VERSION "HINBNNNYYNNNYYNNNNNNNNNNNNYNNNYYYNNYNNNNNN/4//%%/4/'%**4NNN///"

NS_ :

BS_:

BU_: VirtualNMTMaster TTGateway_ID2 Master_ID1 SupportFront_ID12 LadderDrive_ID11 SupportRear_ID13 ControlPanel_ID10

BO_ 1794 HBGuard_002: 1 TTGateway_ID2
 SG_ Toggle : 7|1@1+ (1,0) [0|0] "" Vector__XXX
 SG_ State : 0|7@1+ (1,0) [0|0] "" Vector__XXX

BO_ 1410 SSDO_002: 8 TTGateway_ID2
 SG_ requested_engine_speed_minimum_v m3 : 32|16@1+ (1,0) [0|65535] "" Vector__XXX
 SG_ requested_engine_speed_maximum_v m2 : 32|16@1+ (1,0) [0|65535] "" Vector__XXX
 SG_ requested_engine_speed_value_614 m1 : 32|16@1- (1,0) [-32768|32767] "" Vector__XXX
 SG_ requested_engine_speed_number_of m0 : 32|8@1+ (1,0) [0|255] "" Vector__XXX
 SG_ SubIndex_614A m24906M : 24|8@1+ (1,0) [0|3] "" Vector__XXX
 SG_ requested_engine_speed_lower_lim m3 : 32|16@1+ (1,0) [0|65535] "" Vector__XXX
 SG_ requested_engine_speed_lowe_0000 m2 : 32|16@1+ (1,0) [0|65535] "" Vector__XXX
 SG_ requested_engine_speed_lowe_0001 m1 : 32|16@1+ (1,0) [0|65535] "" Vector__XXX
 SG_ requested_engine_speed_lowe_0002 m0 : 32|8@1+ (1,0) [0|255] "" Vector__XXX
 SG_ SubIndex_6142 m24898M : 24|8@1+ (1,0) [0|3] "" Vector__XXX
 SG_ requested_engine_speed_upper_lim m3 : 32|16@1+ (1,0) [0|65535] "" Vector__XXX
 SG_ requested_engine_speed_uppe_0000 m2 : 32|16@1+ (1,0) [0|65535] "" Vector__XXX
 SG_ requested_engine_speed_uppe_0001 m1 : 32|16@1+ (1,0) [0|65535] "" Vector__XXX
 SG_ requested_engine_speed_uppe_0002 m0 : 32|8@1+ (1,0) [0|255] "" Vector__XXX
 SG_ SubIndex_6140 m24896M : 24|8@1+ (1,0) [0|3] "" Vector__XXX
 SG_ engine_stop_switch_Bit_1_613F_01 m1 : 32|8@1+ (1,0) [0|255] "" Vector__XXX
 SG_ engine_stop_switch_Number_of_ent m0 : 32|8@1+ (1,0) [0|255] "" Vector__XXX
 SG_ SubIndex_613F m24895M : 24|8@1+ (1,0) [0|1] "" Vector__XXX
 SG_ engine_start_switch_Bit_1_613E_0 m1 : 32|8@1+ (1,0) [0|255] "" Vector__XXX
 SG_ engine_start_switch_Number_of_en m0 : 32|8@1+ (1,0) [0|255] "" Vector__XXX
 SG_ SubIndex_613E m24894M : 24|8@1+ (1,0) [0|1] "" Vector__XXX
 SG_ first_clutch_dependent_PTO_switc m1 : 32|8@1+ (1,0) [0|255] "" Vector__XXX
 SG_ first_clutch_dependent_PTO__0000 m0 : 32|8@1+ (1,0) [0|255] "" Vector__XXX
 SG_ SubIndex_6136 m24886M : 24|8@1+ (1,0) [0|1] "" Vector__XXX
 SG_ first_engine_mounted_PTO_feedbac m1 : 32|8@1+ (1,0) [0|255] "" Vector__XXX
 SG_ first_engine_mounted_PTO_fe_0000 m0 : 32|8@1+ (1,0) [0|255] "" Vector__XXX
 SG_ SubIndex_6131 m24881M : 24|8@1+ (1,0) [0|1] "" Vector__XXX
 SG_ PTOSwitch_6113_05 m5 : 32|8@1+ (1,0) [0|255] "" Vector__XXX
 SG_ SupportPositionGateIn_6113_04 m4 : 32|8@1+ (1,0) [0|255] "" Vector__XXX
 SG_ engine_speed_minimum_value_range m3 : 32|16@1+ (1,0) [0|65535] "" Vector__XXX
 SG_ engine_speed_maximum_value_range m2 : 32|16@1+ (1,0) [0|65535] "" Vector__XXX
 SG_ EngineSpeed_6113_01 m1 : 32|16@1+ (1,0) [0|65535] "" Vector__XXX
 SG_ NrOfObjects_6113_00 m0 : 32|8@1+ (1,0) [5|5] "" Vector__XXX
 SG_ SubIndex_6113 m24851M : 24|8@1+ (1,0) [0|5] "" Vector__XXX
 SG_ current_gear_minimum_value_range m3 : 32|8@1- (1,0) [-128|127] "" Vector__XXX
 SG_ current_gear_maximum_value_range m2 : 32|8@1- (1,0) [-128|127] "" Vector__XXX
 SG_ CurrentGearValue_610C_01 m1 : 32|8@1- (1,0) [-128|127] "" Vector__XXX
 SG_ NrOfObjects_610C_00 m0 : 32|8@1+ (1,0) [0|255] "" Vector__XXX
 SG_ SubIndex_610C m24844M : 24|8@1+ (1,0) [0|3] "" Vector__XXX
 SG_ wheel_based_vehicle_speed_minimu m3 : 32|16@1+ (1,0) [0|65535] "" Vector__XXX
 SG_ wheel_based_vehicle_speed_maximu m2 : 32|16@1+ (1,0) [0|65535] "" Vector__XXX
 SG_ wheel_based_vehicle_speed_value_ m1 : 32|16@1+ (1,0) [0|65535] "" Vector__XXX
 SG_ wheel_based_vehicle_speed_number m0 : 32|8@1+ (1,0) [0|255] "" Vector__XXX
 SG_ SubIndex_6006 m24582M : 24|8@1+ (1,0) [0|3] "" Vector__XXX
 SG_ park_brake_demand_value_minimum_ m3 : 32|8@1+ (1,0) [0|255] "" Vector__XXX
 SG_ park_brake_demand_value_maximum_ m2 : 32|8@1+ (1,0) [0|255] "" Vector__XXX
 SG_ ParkBrakeDemandValue_6000_01 m1 : 32|8@1+ (1,0) [0|255] "" Vector__XXX
 SG_ NrOfObjects_6000_00 m0 : 32|8@1+ (1,0) [0|255] "" Vector__XXX
 SG_ SubIndex_6000 m24576M : 24|8@1+ (1,0) [0|3] "" Vector__XXX
 SG_ NrOfMappedObjects_1A02_00 m0 : 32|8@1+ (1,0) [0|64] "" Vector__XXX
 SG_ SubIndex_1A02 m6658M : 24|8@1+ (1,0) [0|0] "" Vector__XXX
 SG_ NrOfMappedObjects_1A01_00 m0 : 32|8@1+ (1,0) [0|64] "" Vector__XXX
 SG_ SubIndex_1A01 m6657M : 24|8@1+ (1,0) [0|0] "" Vector__XXX
 SG_ mappedObj5_1A00_05 m5 : 32|32@1+ (1,0) [0|4294967295] "" Vector__XXX
 SG_ mappedObj4_1A00_04 m4 : 32|32@1+ (1,0) [0|4294967295] "" Vector__XXX
 SG_ mappedObj3_1A00_03 m3 : 32|32@1+ (1,0) [0|4294967295] "" Vector__XXX
 SG_ mappedObj2_1A00_02 m2 : 32|32@1+ (1,0) [0|4294967295] "" Vector__XXX
 SG_ mappedObj1_1A00_01 m1 : 32|32@1+ (1,0) [0|4294967295] "" Vector__XXX
 SG_ NrOfMappedObjects_1A00_00 m0 : 32|8@1+ (1,0) [0|64] "" Vector__XXX
 SG_ SubIndex_1A00 m6656M : 24|8@1+ (1,0) [0|5] "" Vector__XXX
 SG_ EventTimer_1802_05 m5 : 32|16@1+ (1,0) [0|65535] "" Vector__XXX
 SG_ TransmissionType_1802_02 m2 : 32|8@1+ (1,0) [0|255] "" Vector__XXX
 SG_ COB_ID_1802_01 m1 : 32|32@1+ (1,0) [1|4294967295] "" Vector__XXX
 SG_ Highest_sub_index_supported_1802 m0 : 32|8@1+ (1,0) [2|5] "" Vector__XXX
 SG_ SubIndex_1802 m6146M : 24|8@1+ (1,0) [0|5] "" Vector__XXX
 SG_ EventTimer_1801_05 m5 : 32|16@1+ (1,0) [0|65535] "" Vector__XXX
 SG_ TransmissionType_1801_02 m2 : 32|8@1+ (1,0) [0|255] "" Vector__XXX
 SG_ COB_ID_1801_01 m1 : 32|32@1+ (1,0) [1|4294967295] "" Vector__XXX
 SG_ Highest_sub_index_supported_1801 m0 : 32|8@1+ (1,0) [2|5] "" Vector__XXX
 SG_ SubIndex_1801 m6145M : 24|8@1+ (1,0) [0|5] "" Vector__XXX
 SG_ EventTimer_1800_05 m5 : 32|16@1+ (1,0) [0|65535] "" Vector__XXX
 SG_ TransmissionType_1800_02 m2 : 32|8@1+ (1,0) [0|255] "" Vector__XXX
 SG_ COB_ID_1800_01 m1 : 32|32@1+ (1,0) [1|4294967295] "" Vector__XXX
 SG_ Highest_sub_index_supported_1800 m0 : 32|8@1+ (1,0) [2|5] "" Vector__XXX
 SG_ SubIndex_1800 m6144M : 24|8@1+ (1,0) [0|5] "" Vector__XXX
 SG_ GENERATED_1602_03 m3 : 32|32@1+ (1,0) [0|4294967295] "" Vector__XXX
 SG_ GENERATED_1602_02 m2 : 32|32@1+ (1,0) [0|4294967295] "" Vector__XXX
 SG_ GENERATED_1602_01 m1 : 32|32@1+ (1,0) [0|4294967295] "" Vector__XXX
 SG_ NrOfMappedObjects_1602_00 m0 : 32|8@1+ (1,0) [0|64] "" Vector__XXX
 SG_ SubIndex_1602 m5634M : 24|8@1+ (1,0) [0|3] "" Vector__XXX
 SG_ PTO_Switch_1601_01 m1 : 32|8@1+ (1,0) [0|255] "" Vector__XXX
 SG_ NrOfMappedObjects_1601_00 m0 : 32|8@1+ (1,0) [0|64] "" Vector__XXX
 SG_ SubIndex_1601 m5633M : 24|8@1+ (1,0) [0|1] "" Vector__XXX
 SG_ mappedObj5_1600_05 m5 : 32|32@1+ (1,0) [0|4294967295] "" Vector__XXX
 SG_ mappedObj4_1600_04 m4 : 32|32@1+ (1,0) [0|4294967295] "" Vector__XXX
 SG_ mappedObj3_1600_03 m3 : 32|32@1+ (1,0) [0|4294967295] "" Vector__XXX
 SG_ mappedObj2_1600_02 m2 : 32|32@1+ (1,0) [0|4294967295] "" Vector__XXX
 SG_ mappedObj1_1600_01 m1 : 32|32@1+ (1,0) [0|4294967295] "" Vector__XXX
 SG_ NrOfMappedObjects_1600_00 m0 : 32|8@1+ (1,0) [0|64] "" Vector__XXX
 SG_ SubIndex_1600 m5632M : 24|8@1+ (1,0) [0|5] "" Vector__XXX
 SG_ TransmissionType_1402_02 m2 : 32|8@1+ (1,0) [0|255] "" Vector__XXX
 SG_ COB_ID_1402_01 m1 : 32|32@1+ (1,0) [1|4294967295] "" Vector__XXX
 SG_ Highest_sub_index_supported_1402 m0 : 32|8@1+ (1,0) [2|5] "" Vector__XXX
 SG_ SubIndex_1402 m5122M : 24|8@1+ (1,0) [0|2] "" Vector__XXX
 SG_ TransmissionType_1401_02 m2 : 32|8@1+ (1,0) [0|255] "" Vector__XXX
 SG_ COB_ID_1401_01 m1 : 32|32@1+ (1,0) [1|4294967295] "" Vector__XXX
 SG_ Highest_sub_index_supported_1401 m0 : 32|8@1+ (1,0) [2|5] "" Vector__XXX
 SG_ SubIndex_1401 m5121M : 24|8@1+ (1,0) [0|2] "" Vector__XXX
 SG_ TransmissionType_1400_02 m2 : 32|8@1+ (1,0) [0|255] "" Vector__XXX
 SG_ COB_ID_1400_01 m1 : 32|32@1+ (1,0) [1|4294967295] "" Vector__XXX
 SG_ Highest_sub_index_supported_1400 m0 : 32|8@1+ (1,0) [2|5] "" Vector__XXX
 SG_ SubIndex_1400 m5120M : 24|8@1+ (1,0) [0|2] "" Vector__XXX
 SG_ Vendor_Id_1018_01 m1 : 32|32@1+ (1,0) [0|4294967295] "" Vector__XXX
 SG_ NrOfElements_1018_00 m0 : 32|8@1+ (1,0) [1|4] "" Vector__XXX
 SG_ SubIndex_1018 m4120M : 24|8@1+ (1,0) [0|1] "" Vector__XXX
 SG_ Sync_Window_Length_1007 m0 : 32|32@1+ (1,0) [0|4294967295] "" Vector__XXX
 SG_ SubIndex_1007 m4103M : 24|8@1+ (1,0) [0|0] "" Vector__XXX
 SG_ Communication_Cycle_Period_1006 m0 : 32|32@1+ (1,0) [0|4294967295] "" Vector__XXX
 SG_ SubIndex_1006 m4102M : 24|8@1+ (1,0) [0|0] "" Vector__XXX
 SG_ COB_ID_SYNC_1005 m0 : 32|32@1+ (1,0) [1|4294967295] "" Vector__XXX
 SG_ SubIndex_1005 m4101M : 24|8@1+ (1,0) [0|0] "" Vector__XXX
 SG_ ErrorRegister_1001 m0 : 32|8@1+ (1,0) [0|255] "" Vector__XXX
 SG_ SubIndex_1001 m4097M : 24|8@1+ (1,0) [0|0] "" Vector__XXX
 SG_ Device_Type_1000 m0 : 32|32@1+ (1,0) [0|4294967295] "" Vector__XXX
 SG_ SubIndex_1000 m4096M : 24|8@1+ (1,0) [0|0] "" Vector__XXX
 SG_ Index m1M : 8|16@1+ (1,0) [4096|24906] "" Vector__XXX
 SG_ TransferType m1M : 1|1@1+ (1,0) [0|1] "" Vector__XXX
 SG_ NotUsedBytes m1 : 2|2@1+ (1,0) [0|3] "" Vector__XXX
 SG_ SizeIndicator m1 : 0|1@1+ (1,0) [0|1] "" Vector__XXX
 SG_ SCS M : 5|3@1+ (1,0) [0|6] "" Vector__XXX

BO_ 1538 CSDO_002: 8 Vector__XXX
 SG_ requested_engine_speed_mini_0000 m3 : 32|16@1+ (1,0) [0|65535] ""  TTGateway_ID2
 SG_ requested_engine_speed_maxi_0000 m2 : 32|16@1+ (1,0) [0|65535] ""  TTGateway_ID2
 SG_ requested_engine_speed_valu_0000 m1 : 32|16@1- (1,0) [-32768|32767] ""  TTGateway_ID2
 SG_ requested_engine_speed_numb_0000 m0 : 32|8@1+ (1,0) [0|255] ""  TTGateway_ID2
 SG_ SubIndex_614A m24906M : 24|8@1+ (1,0) [0|3] ""  TTGateway_ID2
 SG_ requested_engine_speed_lowe_0003 m3 : 32|16@1+ (1,0) [0|65535] ""  TTGateway_ID2
 SG_ requested_engine_speed_lowe_0004 m2 : 32|16@1+ (1,0) [0|65535] ""  TTGateway_ID2
 SG_ requested_engine_speed_lowe_0005 m1 : 32|16@1+ (1,0) [0|65535] ""  TTGateway_ID2
 SG_ requested_engine_speed_lowe_0006 m0 : 32|8@1+ (1,0) [0|255] ""  TTGateway_ID2
 SG_ SubIndex_6142 m24898M : 24|8@1+ (1,0) [0|3] ""  TTGateway_ID2
 SG_ requested_engine_speed_uppe_0003 m3 : 32|16@1+ (1,0) [0|65535] ""  TTGateway_ID2
 SG_ requested_engine_speed_uppe_0004 m2 : 32|16@1+ (1,0) [0|65535] ""  TTGateway_ID2
 SG_ requested_engine_speed_uppe_0005 m1 : 32|16@1+ (1,0) [0|65535] ""  TTGateway_ID2
 SG_ requested_engine_speed_uppe_0006 m0 : 32|8@1+ (1,0) [0|255] ""  TTGateway_ID2
 SG_ SubIndex_6140 m24896M : 24|8@1+ (1,0) [0|3] ""  TTGateway_ID2
 SG_ engine_stop_switch_Bit_1_613F_01 m1 : 32|8@1+ (1,0) [0|255] ""  TTGateway_ID2
 SG_ engine_stop_switch_Number_o_0000 m0 : 32|8@1+ (1,0) [0|255] ""  TTGateway_ID2
 SG_ SubIndex_613F m24895M : 24|8@1+ (1,0) [0|1] ""  TTGateway_ID2
 SG_ engine_start_switch_Bit_1_6_0000 m1 : 32|8@1+ (1,0) [0|255] ""  TTGateway_ID2
 SG_ engine_start_switch_Number__0000 m0 : 32|8@1+ (1,0) [0|255] ""  TTGateway_ID2
 SG_ SubIndex_613E m24894M : 24|8@1+ (1,0) [0|1] ""  TTGateway_ID2
 SG_ first_clutch_dependent_PTO__0001 m1 : 32|8@1+ (1,0) [0|255] ""  TTGateway_ID2
 SG_ first_clutch_dependent_PTO__0002 m0 : 32|8@1+ (1,0) [0|255] ""  TTGateway_ID2
 SG_ SubIndex_6136 m24886M : 24|8@1+ (1,0) [0|1] ""  TTGateway_ID2
 SG_ first_engine_mounted_PTO_fe_0001 m1 : 32|8@1+ (1,0) [0|255] ""  TTGateway_ID2
 SG_ first_engine_mounted_PTO_fe_0002 m0 : 32|8@1+ (1,0) [0|255] ""  TTGateway_ID2
 SG_ SubIndex_6131 m24881M : 24|8@1+ (1,0) [0|1] ""  TTGateway_ID2
 SG_ PTOSwitch_6113_05 m5 : 32|8@1+ (1,0) [0|255] ""  TTGateway_ID2
 SG_ SupportPositionGateIn_6113_04 m4 : 32|8@1+ (1,0) [0|255] ""  TTGateway_ID2
 SG_ engine_speed_minimum_value__0000 m3 : 32|16@1+ (1,0) [0|65535] ""  TTGateway_ID2
 SG_ engine_speed_maximum_value__0000 m2 : 32|16@1+ (1,0) [0|65535] ""  TTGateway_ID2
 SG_ EngineSpeed_6113_01 m1 : 32|16@1+ (1,0) [0|65535] ""  TTGateway_ID2
 SG_ NrOfObjects_6113_00 m0 : 32|8@1+ (1,0) [5|5] ""  TTGateway_ID2
 SG_ SubIndex_6113 m24851M : 24|8@1+ (1,0) [0|5] ""  TTGateway_ID2
 SG_ current_gear_minimum_value__0000 m3 : 32|8@1- (1,0) [-128|127] ""  TTGateway_ID2
 SG_ current_gear_maximum_value__0000 m2 : 32|8@1- (1,0) [-128|127] ""  TTGateway_ID2
 SG_ CurrentGearValue_610C_01 m1 : 32|8@1- (1,0) [-128|127] ""  TTGateway_ID2
 SG_ NrOfObjects_610C_00 m0 : 32|8@1+ (1,0) [0|255] ""  TTGateway_ID2
 SG_ SubIndex_610C m24844M : 24|8@1+ (1,0) [0|3] ""  TTGateway_ID2
 SG_ wheel_based_vehicle_speed_m_0000 m3 : 32|16@1+ (1,0) [0|65535] ""  TTGateway_ID2
 SG_ wheel_based_vehicle_speed_m_0001 m2 : 32|16@1+ (1,0) [0|65535] ""  TTGateway_ID2
 SG_ wheel_based_vehicle_speed_v_0000 m1 : 32|16@1+ (1,0) [0|65535] ""  TTGateway_ID2
 SG_ wheel_based_vehicle_speed_n_0000 m0 : 32|8@1+ (1,0) [0|255] ""  TTGateway_ID2
 SG_ SubIndex_6006 m24582M : 24|8@1+ (1,0) [0|3] ""  TTGateway_ID2
 SG_ park_brake_demand_value_min_0000 m3 : 32|8@1+ (1,0) [0|255] ""  TTGateway_ID2
 SG_ park_brake_demand_value_max_0000 m2 : 32|8@1+ (1,0) [0|255] ""  TTGateway_ID2
 SG_ ParkBrakeDemandValue_6000_01 m1 : 32|8@1+ (1,0) [0|255] ""  TTGateway_ID2
 SG_ NrOfObjects_6000_00 m0 : 32|8@1+ (1,0) [0|255] ""  TTGateway_ID2
 SG_ SubIndex_6000 m24576M : 24|8@1+ (1,0) [0|3] ""  TTGateway_ID2
 SG_ NrOfMappedObjects_1A02_00 m0 : 32|8@1+ (1,0) [0|64] ""  TTGateway_ID2
 SG_ SubIndex_1A02 m6658M : 24|8@1+ (1,0) [0|0] ""  TTGateway_ID2
 SG_ NrOfMappedObjects_1A01_00 m0 : 32|8@1+ (1,0) [0|64] ""  TTGateway_ID2
 SG_ SubIndex_1A01 m6657M : 24|8@1+ (1,0) [0|0] ""  TTGateway_ID2
 SG_ mappedObj5_1A00_05 m5 : 32|32@1+ (1,0) [0|4294967295] ""  TTGateway_ID2
 SG_ mappedObj4_1A00_04 m4 : 32|32@1+ (1,0) [0|4294967295] ""  TTGateway_ID2
 SG_ mappedObj3_1A00_03 m3 : 32|32@1+ (1,0) [0|4294967295] ""  TTGateway_ID2
 SG_ mappedObj2_1A00_02 m2 : 32|32@1+ (1,0) [0|4294967295] ""  TTGateway_ID2
 SG_ mappedObj1_1A00_01 m1 : 32|32@1+ (1,0) [0|4294967295] ""  TTGateway_ID2
 SG_ NrOfMappedObjects_1A00_00 m0 : 32|8@1+ (1,0) [0|64] ""  TTGateway_ID2
 SG_ SubIndex_1A00 m6656M : 24|8@1+ (1,0) [0|5] ""  TTGateway_ID2
 SG_ EventTimer_1802_05 m5 : 32|16@1+ (1,0) [0|65535] ""  TTGateway_ID2
 SG_ TransmissionType_1802_02 m2 : 32|8@1+ (1,0) [0|255] ""  TTGateway_ID2
 SG_ COB_ID_1802_01 m1 : 32|32@1+ (1,0) [1|4294967295] ""  TTGateway_ID2
 SG_ Highest_sub_index_supported_0000 m0 : 32|8@1+ (1,0) [2|5] ""  TTGateway_ID2
 SG_ SubIndex_1802 m6146M : 24|8@1+ (1,0) [0|5] ""  TTGateway_ID2
 SG_ EventTimer_1801_05 m5 : 32|16@1+ (1,0) [0|65535] ""  TTGateway_ID2
 SG_ TransmissionType_1801_02 m2 : 32|8@1+ (1,0) [0|255] ""  TTGateway_ID2
 SG_ COB_ID_1801_01 m1 : 32|32@1+ (1,0) [1|4294967295] ""  TTGateway_ID2
 SG_ Highest_sub_index_supported_0001 m0 : 32|8@1+ (1,0) [2|5] ""  TTGateway_ID2
 SG_ SubIndex_1801 m6145M : 24|8@1+ (1,0) [0|5] ""  TTGateway_ID2
 SG_ EventTimer_1800_05 m5 : 32|16@1+ (1,0) [0|65535] ""  TTGateway_ID2
 SG_ TransmissionType_1800_02 m2 : 32|8@1+ (1,0) [0|255] ""  TTGateway_ID2
 SG_ COB_ID_1800_01 m1 : 32|32@1+ (1,0) [1|4294967295] ""  TTGateway_ID2
 SG_ Highest_sub_index_supported_0002 m0 : 32|8@1+ (1,0) [2|5] ""  TTGateway_ID2
 SG_ SubIndex_1800 m6144M : 24|8@1+ (1,0) [0|5] ""  TTGateway_ID2
 SG_ GENERATED_1602_03 m3 : 32|32@1+ (1,0) [0|4294967295] ""  TTGateway_ID2
 SG_ GENERATED_1602_02 m2 : 32|32@1+ (1,0) [0|4294967295] ""  TTGateway_ID2
 SG_ GENERATED_1602_01 m1 : 32|32@1+ (1,0) [0|4294967295] ""  TTGateway_ID2
 SG_ NrOfMappedObjects_1602_00 m0 : 32|8@1+ (1,0) [0|64] ""  TTGateway_ID2
 SG_ SubIndex_1602 m5634M : 24|8@1+ (1,0) [0|3] ""  TTGateway_ID2
 SG_ PTO_Switch_1601_01 m1 : 32|8@1+ (1,0) [0|255] ""  TTGateway_ID2
 SG_ NrOfMappedObjects_1601_00 m0 : 32|8@1+ (1,0) [0|64] ""  TTGateway_ID2
 SG_ SubIndex_1601 m5633M : 24|8@1+ (1,0) [0|1] ""  TTGateway_ID2
 SG_ mappedObj5_1600_05 m5 : 32|32@1+ (1,0) [0|4294967295] ""  TTGateway_ID2
 SG_ mappedObj4_1600_04 m4 : 32|32@1+ (1,0) [0|4294967295] ""  TTGateway_ID2
 SG_ mappedObj3_1600_03 m3 : 32|32@1+ (1,0) [0|4294967295] ""  TTGateway_ID2
 SG_ mappedObj2_1600_02 m2 : 32|32@1+ (1,0) [0|4294967295] ""  TTGateway_ID2
 SG_ mappedObj1_1600_01 m1 : 32|32@1+ (1,0) [0|4294967295] ""  TTGateway_ID2
 SG_ NrOfMappedObjects_1600_00 m0 : 32|8@1+ (1,0) [0|64] ""  TTGateway_ID2
 SG_ SubIndex_1600 m5632M : 24|8@1+ (1,0) [0|5] ""  TTGateway_ID2
 SG_ TransmissionType_1402_02 m2 : 32|8@1+ (1,0) [0|255] ""  TTGateway_ID2
 SG_ COB_ID_1402_01 m1 : 32|32@1+ (1,0) [1|4294967295] ""  TTGateway_ID2
 SG_ Highest_sub_index_supported_0003 m0 : 32|8@1+ (1,0) [2|5] ""  TTGateway_ID2
 SG_ SubIndex_1402 m5122M : 24|8@1+ (1,0) [0|2] ""  TTGateway_ID2
 SG_ TransmissionType_1401_02 m2 : 32|8@1+ (1,0) [0|255] ""  TTGateway_ID2
 SG_ COB_ID_1401_01 m1 : 32|32@1+ (1,0) [1|4294967295] ""  TTGateway_ID2
 SG_ Highest_sub_index_supported_0004 m0 : 32|8@1+ (1,0) [2|5] ""  TTGateway_ID2
 SG_ SubIndex_1401 m5121M : 24|8@1+ (1,0) [0|2] ""  TTGateway_ID2
 SG_ TransmissionType_1400_02 m2 : 32|8@1+ (1,0) [0|255] ""  TTGateway_ID2
 SG_ COB_ID_1400_01 m1 : 32|32@1+ (1,0) [1|4294967295] ""  TTGateway_ID2
 SG_ Highest_sub_index_supported_0005 m0 : 32|8@1+ (1,0) [2|5] ""  TTGateway_ID2
 SG_ SubIndex_1400 m5120M : 24|8@1+ (1,0) [0|2] ""  TTGateway_ID2
 SG_ Vendor_Id_1018_01 m1 : 32|32@1+ (1,0) [0|4294967295] ""  TTGateway_ID2
 SG_ NrOfElements_1018_00 m0 : 32|8@1+ (1,0) [1|4] ""  TTGateway_ID2
 SG_ SubIndex_1018 m4120M : 24|8@1+ (1,0) [0|1] ""  TTGateway_ID2
 SG_ Sync_Window_Length_1007 m0 : 32|32@1+ (1,0) [0|4294967295] ""  TTGateway_ID2
 SG_ SubIndex_1007 m4103M : 24|8@1+ (1,0) [0|0] ""  TTGateway_ID2
 SG_ Communication_Cycle_Period_1006 m0 : 32|32@1+ (1,0) [0|4294967295] ""  TTGateway_ID2
 SG_ SubIndex_1006 m4102M : 24|8@1+ (1,0) [0|0] ""  TTGateway_ID2
 SG_ COB_ID_SYNC_1005 m0 : 32|32@1+ (1,0) [1|4294967295] ""  TTGateway_ID2
 SG_ SubIndex_1005 m4101M : 24|8@1+ (1,0) [0|0] ""  TTGateway_ID2
 SG_ ErrorRegister_1001 m0 : 32|8@1+ (1,0) [0|255] ""  TTGateway_ID2
 SG_ SubIndex_1001 m4097M : 24|8@1+ (1,0) [0|0] ""  TTGateway_ID2
 SG_ Device_Type_1000 m0 : 32|32@1+ (1,0) [0|4294967295] ""  TTGateway_ID2
 SG_ SubIndex_1000 m4096M : 24|8@1+ (1,0) [0|0] ""  TTGateway_ID2
 SG_ Index m1M : 8|16@1+ (1,0) [4096|24906] ""  TTGateway_ID2
 SG_ TransferType m1M : 1|1@1+ (1,0) [0|1] ""  TTGateway_ID2
 SG_ NotUsedBytes m1 : 2|2@1+ (1,0) [0|3] ""  TTGateway_ID2
 SG_ SizeIndicator m1 : 0|1@1+ (1,0) [0|1] ""  TTGateway_ID2
 SG_ CCS M : 5|3@1+ (1,0) [0|6] ""  TTGateway_ID2

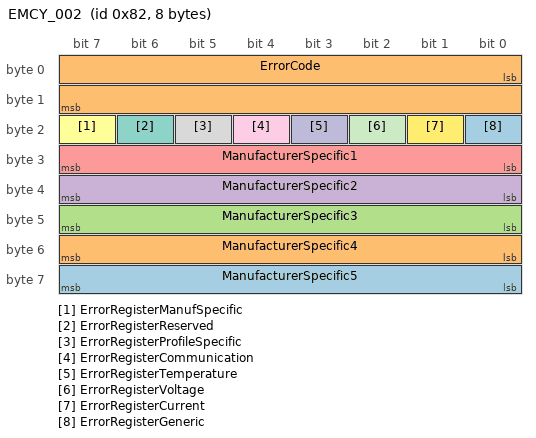
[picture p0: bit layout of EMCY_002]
BO_ 130 EMCY_002: 8 TTGateway_ID2
 SG_ ManufacturerSpecific5 : 56|8@1+ (1,0) [0|0] "" Vector__XXX
 SG_ ManufacturerSpecific4 : 48|8@1+ (1,0) [0|0] "" Vector__XXX
 SG_ ManufacturerSpecific3 : 40|8@1+ (1,0) [0|0] "" Vector__XXX
 SG_ ManufacturerSpecific2 : 32|8@1+ (1,0) [0|0] "" Vector__XXX
 SG_ ManufacturerSpecific1 : 24|8@1+ (1,0) [0|0] "" Vector__XXX
 SG_ ErrorRegisterManufSpecific : 23|1@1+ (1,0) [0|0] "" Vector__XXX
 SG_ ErrorRegisterReserved : 22|1@1+ (1,0) [0|0] "" Vector__XXX
 SG_ ErrorRegisterProfileSpecific : 21|1@1+ (1,0) [0|0] "" Vector__XXX
 SG_ ErrorRegisterCommunication : 20|1@1+ (1,0) [0|0] "" Vector__XXX
 SG_ ErrorRegisterTemperature : 19|1@1+ (1,0) [0|0] "" Vector__XXX
 SG_ ErrorRegisterVoltage : 18|1@1+ (1,0) [0|0] "" Vector__XXX
 SG_ ErrorRegisterCurrent : 17|1@1+ (1,0) [0|0] "" Vector__XXX
 SG_ ErrorRegisterGeneric : 16|1@1+ (1,0) [0|0] "" Vector__XXX
 SG_ ErrorCode : 0|16@1+ (1,0) [0|0] "" Vector__XXX

BO_ 128 SYNC_001: 0 Vector__XXX

BO_ 1793 HBGuard_001: 1 Master_ID1
 SG_ Toggle : 7|1@1+ (1,0) [0|0] "" Vector__XXX
 SG_ State : 0|7@1+ (1,0) [0|0] "" Vector__XXX

BO_ 1409 SSDO_001: 8 Master_ID1
 SG_ NetVarUInt32Out10_A680_0A m10 : 32|32@1+ (1,0) [0|4294967295] "" Vector__XXX
 SG_ NetVarUInt32Out9_A680_09 m9 : 32|32@1+ (1,0) [0|4294967295] "" Vector__XXX
 SG_ NetVarUInt32Out8_A680_08 m8 : 32|32@1+ (1,0) [0|4294967295] "" Vector__XXX
 SG_ NetVarUInt32Out7_A680_07 m7 : 32|32@1+ (1,0) [0|4294967295] "" Vector__XXX
 SG_ NetVarUInt32Out6_A680_06 m6 : 32|32@1+ (1,0) [0|4294967295] "" Vector__XXX
 SG_ NetVarUInt32Out5_A680_05 m5 : 32|32@1+ (1,0) [0|4294967295] "" Vector__XXX
 SG_ NetVarUInt32Out4_A680_04 m4 : 32|32@1+ (1,0) [0|4294967295] "" Vector__XXX
 SG_ NetVarUInt32Out3_A680_03 m3 : 32|32@1+ (1,0) [0|4294967295] "" Vector__XXX
 SG_ NetVarUInt32Out2_A680_02 m2 : 32|32@1+ (1,0) [0|4294967295] "" Vector__XXX
 SG_ NetVarUInt32Out1_A680_01 m1 : 32|32@1+ (1,0) [0|4294967295] "" Vector__XXX
 SG_ NrOfObjects_A680_00 m0 : 32|8@1+ (1,0) [0|255] "" Vector__XXX
 SG_ SubIndex_A680 m42624M : 24|8@1+ (1,0) [0|10] "" Vector__XXX
 SG_ NetVarInt32Out10_A640_0A m10 : 32|32@1- (1,0) [-2147483648|2147483647] "" Vector__XXX
 SG_ NetVarInt32Out9_A640_09 m9 : 32|32@1- (1,0) [-2147483648|2147483647] "" Vector__XXX
 SG_ NetVarInt32Out8_A640_08 m8 : 32|32@1- (1,0) [-2147483648|2147483647] "" Vector__XXX
 SG_ NetVarInt32Out7_A640_07 m7 : 32|32@1- (1,0) [-2147483648|2147483647] "" Vector__XXX
 SG_ NetVarInt32Out6_A640_06 m6 : 32|32@1- (1,0) [-2147483648|2147483647] "" Vector__XXX
 SG_ NetVarInt32Out5_A640_05 m5 : 32|32@1- (1,0) [-2147483648|2147483647] "" Vector__XXX
 SG_ NetVarInt32Out4_A640_04 m4 : 32|32@1- (1,0) [-2147483648|2147483647] "" Vector__XXX
 SG_ pos_act_val_sup_rear_A640_03 m3 : 32|32@1- (1,0) [-2147483648|2147483647] "" Vector__XXX
 SG_ pos_act_val_sup_front_A640_02 m2 : 32|32@1- (1,0) [-2147483648|2147483647] "" Vector__XXX
 SG_ pos_act_val_ladder_A640_01 m1 : 32|32@1- (1,0) [-2147483648|2147483647] "" Vector__XXX
 SG_ NrOfObjects_A640_00 m0 : 32|8@1+ (1,0) [0|255] "" Vector__XXX
 SG_ SubIndex_A640 m42560M : 24|8@1+ (1,0) [0|10] "" Vector__XXX
 SG_ NetVarUInt16Out10_A580_0A m10 : 32|16@1+ (1,0) [0|65535] "" Vector__XXX
 SG_ NetVarUInt16Out9_A580_09 m9 : 32|16@1+ (1,0) [0|65535] "" Vector__XXX
 SG_ NetVarUInt16Out8_A580_08 m8 : 32|16@1+ (1,0) [0|65535] "" Vector__XXX
 SG_ EngineSpeed_A580_07 m7 : 32|16@1+ (1,0) [0|65535] "" Vector__XXX
 SG_ wheel_based_vehicle_speed_A580_0 m6 : 32|16@1+ (1,0) [0|65535] "" Vector__XXX
 SG_ NetVarUInt16Out5_A580_05 m5 : 32|16@1+ (1,0) [0|65535] "" Vector__XXX
 SG_ NetVarUInt16Out4_A580_04 m4 : 32|16@1+ (1,0) [0|65535] "" Vector__XXX
 SG_ statusword_support_rear_A580_03 m3 : 32|16@1+ (1,0) [0|65535] "" Vector__XXX
 SG_ statusword_support_front_A580_02 m2 : 32|16@1+ (1,0) [0|65535] "" Vector__XXX
 SG_ statusword_ladder_A580_01 m1 : 32|16@1+ (1,0) [0|65535] "" Vector__XXX
 SG_ NrOfObjects_A580_00 m0 : 32|8@1+ (1,0) [0|255] "" Vector__XXX
 SG_ SubIndex_A580 m42368M : 24|8@1+ (1,0) [0|10] "" Vector__XXX
 SG_ NetVarInt16Out10_A540_0A m10 : 32|16@1- (1,0) [-32768|32767] "" Vector__XXX
 SG_ NetVarInt16Out9_A540_09 m9 : 32|16@1- (1,0) [-32768|32767] "" Vector__XXX
 SG_ NetVarInt16Out8_A540_08 m8 : 32|16@1- (1,0) [-32768|32767] "" Vector__XXX
 SG_ NetVarInt16Out7_A540_07 m7 : 32|16@1- (1,0) [-32768|32767] "" Vector__XXX
 SG_ NetVarInt16Out6_A540_06 m6 : 32|16@1- (1,0) [-32768|32767] "" Vector__XXX
 SG_ NetVarInt16Out5_A540_05 m5 : 32|16@1- (1,0) [-32768|32767] "" Vector__XXX
 SG_ NetVarInt16Out4_A540_04 m4 : 32|16@1- (1,0) [-32768|32767] "" Vector__XXX
 SG_ NetVarInt16Out3_A540_03 m3 : 32|16@1- (1,0) [-32768|32767] "" Vector__XXX
 SG_ NetVarInt16Out2_A540_02 m2 : 32|16@1- (1,0) [-32768|32767] "" Vector__XXX
 SG_ velocity_demand_ladder_A540_01 m1 : 32|16@1- (1,0) [-32768|32767] "" Vector__XXX
 SG_ NrOfObjects_A540_00 m0 : 32|8@1+ (1,0) [0|255] "" Vector__XXX
 SG_ SubIndex_A540 m42304M : 24|8@1+ (1,0) [0|10] "" Vector__XXX
 SG_ PTO_gear_Feedback_A4C0_0A m10 : 32|8@1+ (1,0) [0|255] "" Vector__XXX
 SG_ PTO_Switch_A4C0_09 m9 : 32|8@1+ (1,0) [0|255] "" Vector__XXX
 SG_ NetVarUInt8Out8_A4C0_08 m8 : 32|8@1+ (1,0) [0|255] "" Vector__XXX
 SG_ NetVarUInt8Out7_A4C0_07 m7 : 32|8@1+ (1,0) [0|255] "" Vector__XXX
 SG_ EngMountedPTO_A4C0_06 m6 : 32|8@1+ (1,0) [0|255] "" Vector__XXX
 SG_ ParkBrakeDemandValue_A4C0_05 m5 : 32|8@1+ (1,0) [0|255] "" Vector__XXX
 SG_ Support_Down_A4C0_04 m4 : 32|8@1+ (1,0) [0|255] "" Vector__XXX
 SG_ Support_Up_A4C0_03 m3 : 32|8@1+ (1,0) [0|255] "" Vector__XXX
 SG_ Ladder_Down_A4C0_02 m2 : 32|8@1+ (1,0) [0|255] "" Vector__XXX
 SG_ Ladder_Up_A4C0_01 m1 : 32|8@1+ (1,0) [0|255] "" Vector__XXX
 SG_ NrOfObjects_A4C0_00 m0 : 32|8@1+ (1,0) [0|255] "" Vector__XXX
 SG_ SubIndex_A4C0 m42176M : 24|8@1+ (1,0) [0|10] "" Vector__XXX
 SG_ NetVarInt8Out10_A480_0A m10 : 32|8@1- (1,0) [-128|127] "" Vector__XXX
 SG_ NetVarInt8Out9_A480_09 m9 : 32|8@1- (1,0) [-128|127] "" Vector__XXX
 SG_ NetVarInt8Out8_A480_08 m8 : 32|8@1- (1,0) [-128|127] "" Vector__XXX
 SG_ NetVarInt8Out7_A480_07 m7 : 32|8@1- (1,0) [-128|127] "" Vector__XXX
 SG_ CurrentGearValue_A480_06 m6 : 32|8@1- (1,0) [-128|127] "" Vector__XXX
 SG_ NetVarInt8Out5_A480_05 m5 : 32|16@1+ (1,0) [0|65535] "" Vector__XXX
 SG_ NetVarInt8Out4_A480_04 m4 : 32|16@1+ (1,0) [0|65535] "" Vector__XXX
 SG_ NetVarInt8Out3_A480_03 m3 : 32|8@1+ (1,0) [0|255] "" Vector__XXX
 SG_ NetVarInt8Out2_A480_02 m2 : 32|8@1+ (1,0) [0|255] "" Vector__XXX
 SG_ NetVarInt8Out1_A480_01 m1 : 32|8@1- (1,0) [-128|127] "" Vector__XXX
 SG_ NrOfObjects_A480_00 m0 : 32|8@1+ (1,0) [0|255] "" Vector__XXX
 SG_ SubIndex_A480 m42112M : 24|8@1+ (1,0) [0|10] "" Vector__XXX
 SG_ NetVarUInt32In10_A200_0A m10 : 32|32@1+ (1,0) [0|4294967295] "" Vector__XXX
 SG_ NetVarUInt32In9_A200_09 m9 : 32|32@1+ (1,0) [0|4294967295] "" Vector__XXX
 SG_ NetVarUInt32In8_A200_08 m8 : 32|32@1+ (1,0) [0|4294967295] "" Vector__XXX
 SG_ NetVarUInt32In7_A200_07 m7 : 32|32@1+ (1,0) [0|4294967295] "" Vector__XXX
 SG_ NetVarUInt32In6_A200_06 m6 : 32|32@1+ (1,0) [0|4294967295] "" Vector__XXX
 SG_ NetVarUInt32In5_A200_05 m5 : 32|32@1+ (1,0) [0|4294967295] "" Vector__XXX
 SG_ NetVarUInt32In4_A200_04 m4 : 32|32@1+ (1,0) [0|4294967295] "" Vector__XXX
 SG_ NetVarUInt32In3_A200_03 m3 : 32|32@1+ (1,0) [0|4294967295] "" Vector__XXX
 SG_ NetVarUInt32In2_A200_02 m2 : 32|32@1+ (1,0) [0|4294967295] "" Vector__XXX
 SG_ NetVarUInt32In1_A200_01 m1 : 32|32@1+ (1,0) [0|4294967295] "" Vector__XXX
 SG_ NrOfObjects_A200_00 m0 : 32|8@1+ (1,0) [0|255] "" Vector__XXX
 SG_ SubIndex_A200 m41472M : 24|8@1+ (1,0) [0|10] "" Vector__XXX
 SG_ NetVarInt32In10_A1C0_0A m10 : 32|32@1- (1,0) [-2147483648|2147483647] "" Vector__XXX
 SG_ NetVarInt32In9_A1C0_09 m9 : 32|32@1- (1,0) [-2147483648|2147483647] "" Vector__XXX
 SG_ NetVarInt32In8_A1C0_08 m8 : 32|32@1- (1,0) [-2147483648|2147483647] "" Vector__XXX
 SG_ NetVarInt32In7_A1C0_07 m7 : 32|32@1- (1,0) [-2147483648|2147483647] "" Vector__XXX
 SG_ NetVarInt32In6_A1C0_06 m6 : 32|32@1- (1,0) [-2147483648|2147483647] "" Vector__XXX
 SG_ NetVarInt32In5_A1C0_05 m5 : 32|32@1- (1,0) [-2147483648|2147483647] "" Vector__XXX
 SG_ NetVarInt32In4_A1C0_04 m4 : 32|32@1- (1,0) [-2147483648|2147483647] "" Vector__XXX
 SG_ NetVarInt32In3_A1C0_03 m3 : 32|32@1- (1,0) [-2147483648|2147483647] "" Vector__XXX
 SG_ NetVarInt32In2_A1C0_02 m2 : 32|32@1- (1,0) [-2147483648|2147483647] "" Vector__XXX
 SG_ NetVarInt32In1_A1C0_01 m1 : 32|32@1- (1,0) [-2147483648|2147483647] "" Vector__XXX
 SG_ NrOfObjects_A1C0_00 m0 : 32|8@1+ (1,0) [0|255] "" Vector__XXX
 SG_ SubIndex_A1C0 m41408M : 24|8@1+ (1,0) [0|10] "" Vector__XXX
 SG_ NetVarUInt16In10_A100_0A m10 : 32|16@1+ (1,0) [0|65535] "" Vector__XXX
 SG_ NetVarUInt16In9_A100_09 m9 : 32|16@1+ (1,0) [0|65535] "" Vector__XXX
 SG_ NetVarUInt16In8_A100_08 m8 : 32|16@1+ (1,0) [0|65535] "" Vector__XXX
 SG_ NetVarUInt16In7_A100_07 m7 : 32|16@1+ (1,0) [0|65535] "" Vector__XXX
 SG_ NetVarUInt16In6_A100_06 m6 : 32|16@1+ (1,0) [0|65535] "" Vector__XXX
 SG_ NetVarUInt16In5_A100_05 m5 : 32|16@1+ (1,0) [0|65535] "" Vector__XXX
 SG_ NetVarUInt16In4_A100_04 m4 : 32|16@1+ (1,0) [0|65535] "" Vector__XXX
 SG_ controlword_sup_rear_A100_03 m3 : 32|16@1+ (1,0) [0|65535] "" Vector__XXX
 SG_ controlword_sup_front_A100_02 m2 : 32|16@1+ (1,0) [0|65535] "" Vector__XXX
 SG_ controlword_ladder_A100_01 m1 : 32|16@1+ (1,0) [0|65535] "" Vector__XXX
 SG_ NrOfObjects_A100_00 m0 : 32|8@1+ (1,0) [0|255] "" Vector__XXX
 SG_ SubIndex_A100 m41216M : 24|8@1+ (1,0) [0|10] "" Vector__XXX
 SG_ NetVarInt16In10_A0C0_0A m10 : 32|16@1- (1,0) [-32768|32767] "" Vector__XXX
 SG_ NetVarInt16In9_A0C0_09 m9 : 32|16@1- (1,0) [-32768|32767] "" Vector__XXX
 SG_ NetVarInt16In8_A0C0_08 m8 : 32|16@1- (1,0) [-32768|32767] "" Vector__XXX
 SG_ NetVarInt16In7_A0C0_07 m7 : 32|16@1- (1,0) [-32768|32767] "" Vector__XXX
 SG_ NetVarInt16In6_A0C0_06 m6 : 32|16@1- (1,0) [-32768|32767] "" Vector__XXX
 SG_ NetVarInt16In5_A0C0_05 m5 : 32|16@1- (1,0) [-32768|32767] "" Vector__XXX
 SG_ requested_engine_speed_A0C0_04 m4 : 32|16@1- (1,0) [-32768|32767] "" Vector__XXX
 SG_ vl_target_velocity_sup_rear_A0C0 m3 : 32|16@1- (1,0) [-32768|32767] "" Vector__XXX
 SG_ vl_target_velocity_sup_front_A0C m2 : 32|16@1- (1,0) [-32768|32767] "" Vector__XXX
 SG_ vl_target_velocity_ladder_A0C0_0 m1 : 32|16@1- (1,0) [-32768|32767] "" Vector__XXX
 SG_ NrOfObjects_A0C0_00 m0 : 32|8@1+ (1,0) [0|255] "" Vector__XXX
 SG_ SubIndex_A0C0 m41152M : 24|8@1+ (1,0) [0|10] "" Vector__XXX
 SG_ NetVarUInt8In9A_A040_0A m10 : 32|8@1+ (1,0) [0|255] "" Vector__XXX
 SG_ MasterPTO_Feedback_A040_09 m9 : 32|8@1+ (1,0) [0|255] "" Vector__XXX
 SG_ NetVarUInt8In8_A040_08 m8 : 32|8@1+ (1,0) [0|255] "" Vector__XXX
 SG_ NetVarUInt8In7_A040_07 m7 : 32|8@1+ (1,0) [0|255] "" Vector__XXX
 SG_ NetVarUInt8In6_A040_06 m6 : 32|8@1+ (1,0) [0|255] "" Vector__XXX
 SG_ NetVarUInt8In5_A040_05 m5 : 32|8@1+ (1,0) [0|255] "" Vector__XXX
 SG_ PTO_Switch_State_A040_04 m4 : 32|8@1+ (1,0) [0|255] "" Vector__XXX
 SG_ Supportposvalue_A040_03 m3 : 32|8@1+ (1,0) [0|255] "" Vector__XXX
 SG_ SupportLock_A040_02 m2 : 32|8@1+ (1,0) [0|255] "" Vector__XXX
 SG_ LadderLock_A040_01 m1 : 32|8@1+ (1,0) [0|255] "" Vector__XXX
 SG_ NrOfObjects_A040_00 m0 : 32|8@1+ (1,0) [0|255] "" Vector__XXX
 SG_ SubIndex_A040 m41024M : 24|8@1+ (1,0) [0|10] "" Vector__XXX
 SG_ NetVarInt8In10_A000_0A m10 : 32|8@1- (1,0) [-128|127] "" Vector__XXX
 SG_ NetVarInt8In9_A000_09 m9 : 32|8@1- (1,0) [-128|127] "" Vector__XXX
 SG_ NetVarInt8In8_A000_08 m8 : 32|8@1- (1,0) [-128|127] "" Vector__XXX
 SG_ NetVarInt8In7_A000_07 m7 : 32|8@1- (1,0) [-128|127] "" Vector__XXX
 SG_ NetVarInt8In6_A000_06 m6 : 32|8@1- (1,0) [-128|127] "" Vector__XXX
 SG_ NetVarInt8In5_A000_05 m5 : 32|8@1- (1,0) [-128|127] "" Vector__XXX
 SG_ NetVarInt8In4_A000_04 m4 : 32|8@1- (1,0) [-128|127] "" Vector__XXX
 SG_ NetVarInt8In3_A000_03 m3 : 32|8@1- (1,0) [-128|127] "" Vector__XXX
 SG_ NetVarInt8In2_A000_02 m2 : 32|8@1- (1,0) [-128|127] "" Vector__XXX
 SG_ CurrentGearValueM_A000_01 m1 : 32|8@1- (1,0) [-128|127] "" Vector__XXX
 SG_ NrOfObjects_A000_00 m0 : 32|8@1+ (1,0) [0|255] "" Vector__XXX
 SG_ SubIndex_A000 m40960M : 24|8@1+ (1,0) [0|10] "" Vector__XXX
 SG_ SerialNumber_7f_1F88_7F m127 : 32|32@1+ (1,0) [0|4294967295] "" Vector__XXX
 SG_ SerialNumber_7e_1F88_7E m126 : 32|32@1+ (1,0) [0|4294967295] "" Vector__XXX
 SG_ SerialNumber_7d_1F88_7D m125 : 32|32@1+ (1,0) [0|4294967295] "" Vector__XXX
 SG_ SerialNumber_7c_1F88_7C m124 : 32|32@1+ (1,0) [0|4294967295] "" Vector__XXX
 SG_ SerialNumber_7b_1F88_7B m123 : 32|32@1+ (1,0) [0|4294967295] "" Vector__XXX
 SG_ SerialNumber_7a_1F88_7A m122 : 32|32@1+ (1,0) [0|4294967295] "" Vector__XXX
 SG_ SerialNumber_79_1F88_79 m121 : 32|32@1+ (1,0) [0|4294967295] "" Vector__XXX
 SG_ SerialNumber_78_1F88_78 m120 : 32|32@1+ (1,0) [0|4294967295] "" Vector__XXX
 SG_ SerialNumber_77_1F88_77 m119 : 32|32@1+ (1,0) [0|4294967295] "" Vector__XXX
 SG_ SerialNumber_76_1F88_76 m118 : 32|32@1+ (1,0) [0|4294967295] "" Vector__XXX
 SG_ SerialNumber_75_1F88_75 m117 : 32|32@1+ (1,0) [0|4294967295] "" Vector__XXX
 SG_ SerialNumber_74_1F88_74 m116 : 32|32@1+ (1,0) [0|4294967295] "" Vector__XXX
 SG_ SerialNumber_73_1F88_73 m115 : 32|32@1+ (1,0) [0|4294967295] "" Vector__XXX
 SG_ SerialNumber_72_1F88_72 m114 : 32|32@1+ (1,0) [0|4294967295] "" Vector__XXX
 SG_ SerialNumber_71_1F88_71 m113 : 32|32@1+ (1,0) [0|4294967295] "" Vector__XXX
 SG_ SerialNumber_70_1F88_70 m112 : 32|32@1+ (1,0) [0|4294967295] "" Vector__XXX
 SG_ SerialNumber_6f_1F88_6F m111 : 32|32@1+ (1,0) [0|4294967295] "" Vector__XXX
 SG_ SerialNumber_6e_1F88_6E m110 : 32|32@1+ (1,0) [0|4294967295] "" Vector__XXX
 SG_ SerialNumber_6d_1F88_6D m109 : 32|32@1+ (1,0) [0|4294967295] "" Vector__XXX
 SG_ SerialNumber_6c_1F88_6C m108 : 32|32@1+ (1,0) [0|4294967295] "" Vector__XXX
 SG_ SerialNumber_6b_1F88_6B m107 : 32|32@1+ (1,0) [0|4294967295] "" Vector__XXX
 SG_ SerialNumber_6a_1F88_6A m106 : 32|32@1+ (1,0) [0|4294967295] "" Vector__XXX
 SG_ SerialNumber_69_1F88_69 m105 : 32|32@1+ (1,0) [0|4294967295] "" Vector__XXX
 SG_ SerialNumber_68_1F88_68 m104 : 32|32@1+ (1,0) [0|4294967295] "" Vector__XXX
 SG_ SerialNumber_67_1F88_67 m103 : 32|32@1+ (1,0) [0|4294967295] "" Vector__XXX
 SG_ SerialNumber_66_1F88_66 m102 : 32|32@1+ (1,0) [0|4294967295] "" Vector__XXX
 SG_ SerialNumber_65_1F88_65 m101 : 32|32@1+ (1,0) [0|4294967295] "" Vector__XXX
 SG_ SerialNumber_64_1F88_64 m100 : 32|32@1+ (1,0) [0|4294967295] "" Vector__XXX
 SG_ SerialNumber_63_1F88_63 m99 : 32|32@1+ (1,0) [0|4294967295] "" Vector__XXX
 SG_ SerialNumber_62_1F88_62 m98 : 32|32@1+ (1,0) [0|4294967295] "" Vector__XXX
 SG_ SerialNumber_61_1F88_61 m97 : 32|32@1+ (1,0) [0|4294967295] "" Vector__XXX
 SG_ SerialNumber_60_1F88_60 m96 : 32|32@1+ (1,0) [0|4294967295] "" Vector__XXX
 SG_ SerialNumber_5f_1F88_5F m95 : 32|32@1+ (1,0) [0|4294967295] "" Vector__XXX
 SG_ SerialNumber_5e_1F88_5E m94 : 32|32@1+ (1,0) [0|4294967295] "" Vector__XXX
 SG_ SerialNumber_5d_1F88_5D m93 : 32|32@1+ (1,0) [0|4294967295] "" Vector__XXX
 SG_ SerialNumber_5c_1F88_5C m92 : 32|32@1+ (1,0) [0|4294967295] "" Vector__XXX
 SG_ SerialNumber_5b_1F88_5B m91 : 32|32@1+ (1,0) [0|4294967295] "" Vector__XXX
 SG_ SerialNumber_5a_1F88_5A m90 : 32|32@1+ (1,0) [0|4294967295] "" Vector__XXX
 SG_ SerialNumber_59_1F88_59 m89 : 32|32@1+ (1,0) [0|4294967295] "" Vector__XXX
 SG_ SerialNumber_58_1F88_58 m88 : 32|32@1+ (1,0) [0|4294967295] "" Vector__XXX
 SG_ SerialNumber_57_1F88_57 m87 : 32|32@1+ (1,0) [0|4294967295] "" Vector__XXX
 SG_ SerialNumber_56_1F88_56 m86 : 32|32@1+ (1,0) [0|4294967295] "" Vector__XXX
 SG_ SerialNumber_55_1F88_55 m85 : 32|32@1+ (1,0) [0|4294967295] "" Vector__XXX
 SG_ SerialNumber_54_1F88_54 m84 : 32|32@1+ (1,0) [0|4294967295] "" Vector__XXX
 SG_ SerialNumber_53_1F88_53 m83 : 32|32@1+ (1,0) [0|4294967295] "" Vector__XXX
 SG_ SerialNumber_52_1F88_52 m82 : 32|32@1+ (1,0) [0|4294967295] "" Vector__XXX
 SG_ SerialNumber_51_1F88_51 m81 : 32|32@1+ (1,0) [0|4294967295] "" Vector__XXX
 SG_ SerialNumber_50_1F88_50 m80 : 32|32@1+ (1,0) [0|4294967295] "" Vector__XXX
 SG_ SerialNumber_4f_1F88_4F m79 : 32|32@1+ (1,0) [0|4294967295] "" Vector__XXX
 SG_ SerialNumber_4e_1F88_4E m78 : 32|32@1+ (1,0) [0|4294967295] "" Vector__XXX
 SG_ SerialNumber_4d_1F88_4D m77 : 32|32@1+ (1,0) [0|4294967295] "" Vector__XXX
 SG_ SerialNumber_4c_1F88_4C m76 : 32|32@1+ (1,0) [0|4294967295] "" Vector__XXX
 SG_ SerialNumber_4b_1F88_4B m75 : 32|32@1+ (1,0) [0|4294967295] "" Vector__XXX
 SG_ SerialNumber_4a_1F88_4A m74 : 32|32@1+ (1,0) [0|4294967295] "" Vector__XXX
 SG_ SerialNumber_49_1F88_49 m73 : 32|32@1+ (1,0) [0|4294967295] "" Vector__XXX
 SG_ SerialNumber_48_1F88_48 m72 : 32|32@1+ (1,0) [0|4294967295] "" Vector__XXX
 SG_ SerialNumber_47_1F88_47 m71 : 32|32@1+ (1,0) [0|4294967295] "" Vector__XXX
 SG_ SerialNumber_46_1F88_46 m70 : 32|32@1+ (1,0) [0|4294967295] "" Vector__XXX
 SG_ SerialNumber_45_1F88_45 m69 : 32|32@1+ (1,0) [0|4294967295] "" Vector__XXX
 SG_ SerialNumber_44_1F88_44 m68 : 32|32@1+ (1,0) [0|4294967295] "" Vector__XXX
 SG_ SerialNumber_43_1F88_43 m67 : 32|32@1+ (1,0) [0|4294967295] "" Vector__XXX
 SG_ SerialNumber_42_1F88_42 m66 : 32|32@1+ (1,0) [0|4294967295] "" Vector__XXX
 SG_ SerialNumber_41_1F88_41 m65 : 32|32@1+ (1,0) [0|4294967295] "" Vector__XXX
 SG_ SerialNumber_40_1F88_40 m64 : 32|32@1+ (1,0) [0|4294967295] "" Vector__XXX
 SG_ SerialNumber_3f_1F88_3F m63 : 32|32@1+ (1,0) [0|4294967295] "" Vector__XXX
 SG_ SerialNumber_3e_1F88_3E m62 : 32|32@1+ (1,0) [0|4294967295] "" Vector__XXX
 SG_ SerialNumber_3d_1F88_3D m61 : 32|32@1+ (1,0) [0|4294967295] "" Vector__XXX
 SG_ SerialNumber_3c_1F88_3C m60 : 32|32@1+ (1,0) [0|4294967295] "" Vector__XXX
 SG_ SerialNumber_3b_1F88_3B m59 : 32|32@1+ (1,0) [0|4294967295] "" Vector__XXX
 SG_ SerialNumber_3a_1F88_3A m58 : 32|32@1+ (1,0) [0|4294967295] "" Vector__XXX
 SG_ SerialNumber_39_1F88_39 m57 : 32|32@1+ (1,0) [0|4294967295] "" Vector__XXX
 SG_ SerialNumber_38_1F88_38 m56 : 32|32@1+ (1,0) [0|4294967295] "" Vector__XXX
 SG_ SerialNumber_37_1F88_37 m55 : 32|32@1+ (1,0) [0|4294967295] "" Vector__XXX
 SG_ SerialNumber_36_1F88_36 m54 : 32|32@1+ (1,0) [0|4294967295] "" Vector__XXX
 SG_ SerialNumber_35_1F88_35 m53 : 32|32@1+ (1,0) [0|4294967295] "" Vector__XXX
 SG_ SerialNumber_34_1F88_34 m52 : 32|32@1+ (1,0) [0|4294967295] "" Vector__XXX
 SG_ SerialNumber_33_1F88_33 m51 : 32|32@1+ (1,0) [0|4294967295] "" Vector__XXX
 SG_ SerialNumber_32_1F88_32 m50 : 32|32@1+ (1,0) [0|4294967295] "" Vector__XXX
 SG_ SerialNumber_31_1F88_31 m49 : 32|32@1+ (1,0) [0|4294967295] "" Vector__XXX
 SG_ SerialNumber_30_1F88_30 m48 : 32|32@1+ (1,0) [0|4294967295] "" Vector__XXX
 SG_ SerialNumber_2f_1F88_2F m47 : 32|32@1+ (1,0) [0|4294967295] "" Vector__XXX
 SG_ SerialNumber_2e_1F88_2E m46 : 32|32@1+ (1,0) [0|4294967295] "" Vector__XXX
 SG_ SerialNumber_2d_1F88_2D m45 : 32|32@1+ (1,0) [0|4294967295] "" Vector__XXX
 SG_ SerialNumber_2c_1F88_2C m44 : 32|32@1+ (1,0) [0|4294967295] "" Vector__XXX
 SG_ SerialNumber_2b_1F88_2B m43 : 32|32@1+ (1,0) [0|4294967295] "" Vector__XXX
 SG_ SerialNumber_2a_1F88_2A m42 : 32|32@1+ (1,0) [0|4294967295] "" Vector__XXX
 SG_ SerialNumber_29_1F88_29 m41 : 32|32@1+ (1,0) [0|4294967295] "" Vector__XXX
 SG_ SerialNumber_28_1F88_28 m40 : 32|32@1+ (1,0) [0|4294967295] "" Vector__XXX
 SG_ SerialNumber_27_1F88_27 m39 : 32|32@1+ (1,0) [0|4294967295] "" Vector__XXX
 SG_ SerialNumber_26_1F88_26 m38 : 32|32@1+ (1,0) [0|4294967295] "" Vector__XXX
 SG_ SerialNumber_25_1F88_25 m37 : 32|32@1+ (1,0) [0|4294967295] "" Vector__XXX
 SG_ SerialNumber_24_1F88_24 m36 : 32|32@1+ (1,0) [0|4294967295] "" Vector__XXX
 SG_ SerialNumber_23_1F88_23 m35 : 32|32@1+ (1,0) [0|4294967295] "" Vector__XXX
 SG_ SerialNumber_22_1F88_22 m34 : 32|32@1+ (1,0) [0|4294967295] "" Vector__XXX
 SG_ SerialNumber_21_1F88_21 m33 : 32|32@1+ (1,0) [0|4294967295] "" Vector__XXX
 SG_ SerialNumber_20_1F88_20 m32 : 32|32@1+ (1,0) [0|4294967295] "" Vector__XXX
 SG_ SerialNumber_1f_1F88_1F m31 : 32|32@1+ (1,0) [0|4294967295] "" Vector__XXX
 SG_ SerialNumber_1e_1F88_1E m30 : 32|32@1+ (1,0) [0|4294967295] "" Vector__XXX
 SG_ SerialNumber_1d_1F88_1D m29 : 32|32@1+ (1,0) [0|4294967295] "" Vector__XXX
 SG_ SerialNumber_1c_1F88_1C m28 : 32|32@1+ (1,0) [0|4294967295] "" Vector__XXX
 SG_ SerialNumber_1b_1F88_1B m27 : 32|32@1+ (1,0) [0|4294967295] "" Vector__XXX
 SG_ SerialNumber_1a_1F88_1A m26 : 32|32@1+ (1,0) [0|4294967295] "" Vector__XXX
 SG_ SerialNumber_19_1F88_19 m25 : 32|32@1+ (1,0) [0|4294967295] "" Vector__XXX
 SG_ SerialNumber_18_1F88_18 m24 : 32|32@1+ (1,0) [0|4294967295] "" Vector__XXX
 SG_ SerialNumber_17_1F88_17 m23 : 32|32@1+ (1,0) [0|4294967295] "" Vector__XXX
 SG_ SerialNumber_16_1F88_16 m22 : 32|32@1+ (1,0) [0|4294967295] "" Vector__XXX
 SG_ SerialNumber_15_1F88_15 m21 : 32|32@1+ (1,0) [0|4294967295] "" Vector__XXX
 SG_ SerialNumber_14_1F88_14 m20 : 32|32@1+ (1,0) [0|4294967295] "" Vector__XXX
 SG_ SerialNumber_13_1F88_13 m19 : 32|32@1+ (1,0) [0|4294967295] "" Vector__XXX
 SG_ SerialNumber_12_1F88_12 m18 : 32|32@1+ (1,0) [0|4294967295] "" Vector__XXX
 SG_ SerialNumber_11_1F88_11 m17 : 32|32@1+ (1,0) [0|4294967295] "" Vector__XXX
 SG_ SerialNumber_10_1F88_10 m16 : 32|32@1+ (1,0) [0|4294967295] "" Vector__XXX
 SG_ SerialNumber_f_1F88_0F m15 : 32|32@1+ (1,0) [0|4294967295] "" Vector__XXX
 SG_ SerialNumber_e_1F88_0E m14 : 32|32@1+ (1,0) [0|4294967295] "" Vector__XXX
 SG_ SerialNumber_d_1F88_0D m13 : 32|32@1+ (1,0) [0|4294967295] "" Vector__XXX
 SG_ SerialNumber_c_1F88_0C m12 : 32|32@1+ (1,0) [0|4294967295] "" Vector__XXX
 SG_ SerialNumber_b_1F88_0B m11 : 32|32@1+ (1,0) [0|4294967295] "" Vector__XXX
 SG_ SerialNumber_a_1F88_0A m10 : 32|32@1+ (1,0) [0|4294967295] "" Vector__XXX
 SG_ SerialNumber_9_1F88_09 m9 : 32|32@1+ (1,0) [0|4294967295] "" Vector__XXX
 SG_ SerialNumber_8_1F88_08 m8 : 32|32@1+ (1,0) [0|4294967295] "" Vector__XXX
 SG_ SerialNumber_7_1F88_07 m7 : 32|32@1+ (1,0) [0|4294967295] "" Vector__XXX
 SG_ SerialNumber_6_1F88_06 m6 : 32|32@1+ (1,0) [0|4294967295] "" Vector__XXX
 SG_ SerialNumber_5_1F88_05 m5 : 32|32@1+ (1,0) [0|4294967295] "" Vector__XXX
 SG_ SerialNumber_4_1F88_04 m4 : 32|32@1+ (1,0) [0|4294967295] "" Vector__XXX
 SG_ SerialNumber_3_1F88_03 m3 : 32|32@1+ (1,0) [0|4294967295] "" Vector__XXX
 SG_ SerialNumber_2_1F88_02 m2 : 32|32@1+ (1,0) [0|4294967295] "" Vector__XXX
 SG_ SerialNumber_1F88_01 m1 : 32|32@1+ (1,0) [0|4294967295] "" Vector__XXX
 SG_ NrOfObjects_1F88_00 m0 : 32|8@1+ (1,0) [0|255] "" Vector__XXX
 SG_ SubIndex_1F88 m8072M : 24|8@1+ (1,0) [0|127] "" Vector__XXX
 SG_ VendorIdentification_7f_1F85_7F m127 : 32|32@1+ (1,0) [0|4294967295] "" Vector__XXX
 SG_ VendorIdentification_7e_1F85_7E m126 : 32|32@1+ (1,0) [0|4294967295] "" Vector__XXX
 SG_ VendorIdentification_7d_1F85_7D m125 : 32|32@1+ (1,0) [0|4294967295] "" Vector__XXX
 SG_ VendorIdentification_7c_1F85_7C m124 : 32|32@1+ (1,0) [0|4294967295] "" Vector__XXX
 SG_ VendorIdentification_7b_1F85_7B m123 : 32|32@1+ (1,0) [0|4294967295] "" Vector__XXX
 SG_ VendorIdentification_7a_1F85_7A m122 : 32|32@1+ (1,0) [0|4294967295] "" Vector__XXX
 SG_ VendorIdentification_79_1F85_79 m121 : 32|32@1+ (1,0) [0|4294967295] "" Vector__XXX
 SG_ VendorIdentification_78_1F85_78 m120 : 32|32@1+ (1,0) [0|4294967295] "" Vector__XXX
 SG_ VendorIdentification_77_1F85_77 m119 : 32|32@1+ (1,0) [0|4294967295] "" Vector__XXX
 SG_ VendorIdentification_76_1F85_76 m118 : 32|32@1+ (1,0) [0|4294967295] "" Vector__XXX
 SG_ VendorIdentification_75_1F85_75 m117 : 32|32@1+ (1,0) [0|4294967295] "" Vector__XXX
 SG_ VendorIdentification_74_1F85_74 m116 : 32|32@1+ (1,0) [0|4294967295] "" Vector__XXX
 SG_ VendorIdentification_73_1F85_73 m115 : 32|32@1+ (1,0) [0|4294967295] "" Vector__XXX
 SG_ VendorIdentification_72_1F85_72 m114 : 32|32@1+ (1,0) [0|4294967295] "" Vector__XXX
 SG_ VendorIdentification_71_1F85_71 m113 : 32|32@1+ (1,0) [0|4294967295] "" Vector__XXX
 SG_ VendorIdentification_70_1F85_70 m112 : 32|32@1+ (1,0) [0|4294967295] "" Vector__XXX
 SG_ VendorIdentification_6f_1F85_6F m111 : 32|32@1+ (1,0) [0|4294967295] "" Vector__XXX
 SG_ VendorIdentification_6e_1F85_6E m110 : 32|32@1+ (1,0) [0|4294967295] "" Vector__XXX
 SG_ VendorIdentification_6d_1F85_6D m109 : 32|32@1+ (1,0) [0|4294967295] "" Vector__XXX
 SG_ VendorIdentification_6c_1F85_6C m108 : 32|32@1+ (1,0) [0|4294967295] "" Vector__XXX
 SG_ VendorIdentification_6b_1F85_6B m107 : 32|32@1+ (1,0) [0|4294967295] "" Vector__XXX
 SG_ VendorIdentification_6a_1F85_6A m106 : 32|32@1+ (1,0) [0|4294967295] "" Vector__XXX
 SG_ VendorIdentification_69_1F85_69 m105 : 32|32@1+ (1,0) [0|4294967295] "" Vector__XXX
 SG_ VendorIdentification_68_1F85_68 m104 : 32|32@1+ (1,0) [0|4294967295] "" Vector__XXX
 SG_ VendorIdentification_67_1F85_67 m103 : 32|32@1+ (1,0) [0|4294967295] "" Vector__XXX
 SG_ VendorIdentification_66_1F85_66 m102 : 32|32@1+ (1,0) [0|4294967295] "" Vector__XXX
 SG_ VendorIdentification_65_1F85_65 m101 : 32|32@1+ (1,0) [0|4294967295] "" Vector__XXX
 SG_ VendorIdentification_64_1F85_64 m100 : 32|32@1+ (1,0) [0|4294967295] "" Vector__XXX
 SG_ VendorIdentification_63_1F85_63 m99 : 32|32@1+ (1,0) [0|4294967295] "" Vector__XXX
 SG_ VendorIdentification_62_1F85_62 m98 : 32|32@1+ (1,0) [0|4294967295] "" Vector__XXX
 SG_ VendorIdentification_61_1F85_61 m97 : 32|32@1+ (1,0) [0|4294967295] "" Vector__XXX
 SG_ VendorIdentification_60_1F85_60 m96 : 32|32@1+ (1,0) [0|4294967295] "" Vector__XXX
 SG_ VendorIdentification_5f_1F85_5F m95 : 32|32@1+ (1,0) [0|4294967295] "" Vector__XXX
 SG_ VendorIdentification_5e_1F85_5E m94 : 32|32@1+ (1,0) [0|4294967295] "" Vector__XXX
 SG_ VendorIdentification_5d_1F85_5D m93 : 32|32@1+ (1,0) [0|4294967295] "" Vector__XXX
 SG_ VendorIdentification_5c_1F85_5C m92 : 32|32@1+ (1,0) [0|4294967295] "" Vector__XXX
 SG_ VendorIdentification_5b_1F85_5B m91 : 32|32@1+ (1,0) [0|4294967295] "" Vector__XXX
 SG_ VendorIdentification_5a_1F85_5A m90 : 32|32@1+ (1,0) [0|4294967295] "" Vector__XXX
 SG_ VendorIdentification_59_1F85_59 m89 : 32|32@1+ (1,0) [0|4294967295] "" Vector__XXX
 SG_ VendorIdentification_58_1F85_58 m88 : 32|32@1+ (1,0) [0|4294967295] "" Vector__XXX
 SG_ VendorIdentification_57_1F85_57 m87 : 32|32@1+ (1,0) [0|4294967295] "" Vector__XXX
 SG_ VendorIdentification_56_1F85_56 m86 : 32|32@1+ (1,0) [0|4294967295] "" Vector__XXX
 SG_ VendorIdentification_55_1F85_55 m85 : 32|32@1+ (1,0) [0|4294967295] "" Vector__XXX
 SG_ VendorIdentification_54_1F85_54 m84 : 32|32@1+ (1,0) [0|4294967295] "" Vector__XXX
 SG_ VendorIdentification_53_1F85_53 m83 : 32|32@1+ (1,0) [0|4294967295] "" Vector__XXX
 SG_ VendorIdentification_52_1F85_52 m82 : 32|32@1+ (1,0) [0|4294967295] "" Vector__XXX
 SG_ VendorIdentification_51_1F85_51 m81 : 32|32@1+ (1,0) [0|4294967295] "" Vector__XXX
 SG_ VendorIdentification_50_1F85_50 m80 : 32|32@1+ (1,0) [0|4294967295] "" Vector__XXX
 SG_ VendorIdentification_4f_1F85_4F m79 : 32|32@1+ (1,0) [0|4294967295] "" Vector__XXX
 SG_ VendorIdentification_4e_1F85_4E m78 : 32|32@1+ (1,0) [0|4294967295] "" Vector__XXX
 SG_ VendorIdentification_4d_1F85_4D m77 : 32|32@1+ (1,0) [0|4294967295] "" Vector__XXX
 SG_ VendorIdentification_4c_1F85_4C m76 : 32|32@1+ (1,0) [0|4294967295] "" Vector__XXX
 SG_ VendorIdentification_4b_1F85_4B m75 : 32|32@1+ (1,0) [0|4294967295] "" Vector__XXX
 SG_ VendorIdentification_4a_1F85_4A m74 : 32|32@1+ (1,0) [0|4294967295] "" Vector__XXX
 SG_ VendorIdentification_49_1F85_49 m73 : 32|32@1+ (1,0) [0|4294967295] "" Vector__XXX
 SG_ VendorIdentification_48_1F85_48 m72 : 32|32@1+ (1,0) [0|4294967295] "" Vector__XXX
 SG_ VendorIdentification_47_1F85_47 m71 : 32|32@1+ (1,0) [0|4294967295] "" Vector__XXX
 SG_ VendorIdentification_46_1F85_46 m70 : 32|32@1+ (1,0) [0|4294967295] "" Vector__XXX
 SG_ VendorIdentification_45_1F85_45 m69 : 32|32@1+ (1,0) [0|4294967295] "" Vector__XXX
 SG_ VendorIdentification_44_1F85_44 m68 : 32|32@1+ (1,0) [0|4294967295] "" Vector__XXX
 SG_ VendorIdentification_43_1F85_43 m67 : 32|32@1+ (1,0) [0|4294967295] "" Vector__XXX
 SG_ VendorIdentification_42_1F85_42 m66 : 32|32@1+ (1,0) [0|4294967295] "" Vector__XXX
 SG_ VendorIdentification_41_1F85_41 m65 : 32|32@1+ (1,0) [0|4294967295] "" Vector__XXX
 SG_ VendorIdentification_40_1F85_40 m64 : 32|32@1+ (1,0) [0|4294967295] "" Vector__XXX
 SG_ VendorIdentification_3f_1F85_3F m63 : 32|32@1+ (1,0) [0|4294967295] "" Vector__XXX
 SG_ VendorIdentification_3e_1F85_3E m62 : 32|32@1+ (1,0) [0|4294967295] "" Vector__XXX
 SG_ VendorIdentification_3d_1F85_3D m61 : 32|32@1+ (1,0) [0|4294967295] "" Vector__XXX
 SG_ VendorIdentification_3c_1F85_3C m60 : 32|32@1+ (1,0) [0|4294967295] "" Vector__XXX
 SG_ VendorIdentification_3b_1F85_3B m59 : 32|32@1+ (1,0) [0|4294967295] "" Vector__XXX
 SG_ VendorIdentification_3a_1F85_3A m58 : 32|32@1+ (1,0) [0|4294967295] "" Vector__XXX
 SG_ VendorIdentification_39_1F85_39 m57 : 32|32@1+ (1,0) [0|4294967295] "" Vector__XXX
 SG_ VendorIdentification_38_1F85_38 m56 : 32|32@1+ (1,0) [0|4294967295] "" Vector__XXX
 SG_ VendorIdentification_37_1F85_37 m55 : 32|32@1+ (1,0) [0|4294967295] "" Vector__XXX
 SG_ VendorIdentification_36_1F85_36 m54 : 32|32@1+ (1,0) [0|4294967295] "" Vector__XXX
 SG_ VendorIdentification_35_1F85_35 m53 : 32|32@1+ (1,0) [0|4294967295] "" Vector__XXX
 SG_ VendorIdentification_34_1F85_34 m52 : 32|32@1+ (1,0) [0|4294967295] "" Vector__XXX
 SG_ VendorIdentification_33_1F85_33 m51 : 32|32@1+ (1,0) [0|4294967295] "" Vector__XXX
 SG_ VendorIdentification_32_1F85_32 m50 : 32|32@1+ (1,0) [0|4294967295] "" Vector__XXX
 SG_ VendorIdentification_31_1F85_31 m49 : 32|32@1+ (1,0) [0|4294967295] "" Vector__XXX
 SG_ VendorIdentification_30_1F85_30 m48 : 32|32@1+ (1,0) [0|4294967295] "" Vector__XXX
 SG_ VendorIdentification_2f_1F85_2F m47 : 32|32@1+ (1,0) [0|4294967295] "" Vector__XXX
 SG_ VendorIdentification_2e_1F85_2E m46 : 32|32@1+ (1,0) [0|4294967295] "" Vector__XXX
 SG_ VendorIdentification_2d_1F85_2D m45 : 32|32@1+ (1,0) [0|4294967295] "" Vector__XXX
 SG_ VendorIdentification_2c_1F85_2C m44 : 32|32@1+ (1,0) [0|4294967295] "" Vector__XXX
 SG_ VendorIdentification_2b_1F85_2B m43 : 32|32@1+ (1,0) [0|4294967295] "" Vector__XXX
 SG_ VendorIdentification_2a_1F85_2A m42 : 32|32@1+ (1,0) [0|4294967295] "" Vector__XXX
 SG_ VendorIdentification_29_1F85_29 m41 : 32|32@1+ (1,0) [0|4294967295] "" Vector__XXX
 SG_ VendorIdentification_28_1F85_28 m40 : 32|32@1+ (1,0) [0|4294967295] "" Vector__XXX
 SG_ VendorIdentification_27_1F85_27 m39 : 32|32@1+ (1,0) [0|4294967295] "" Vector__XXX
 SG_ VendorIdentification_26_1F85_26 m38 : 32|32@1+ (1,0) [0|4294967295] "" Vector__XXX
 SG_ VendorIdentification_25_1F85_25 m37 : 32|32@1+ (1,0) [0|4294967295] "" Vector__XXX
 SG_ VendorIdentification_24_1F85_24 m36 : 32|32@1+ (1,0) [0|4294967295] "" Vector__XXX
 SG_ VendorIdentification_23_1F85_23 m35 : 32|32@1+ (1,0) [0|4294967295] "" Vector__XXX
 SG_ VendorIdentification_22_1F85_22 m34 : 32|32@1+ (1,0) [0|4294967295] "" Vector__XXX
 SG_ VendorIdentification_21_1F85_21 m33 : 32|32@1+ (1,0) [0|4294967295] "" Vector__XXX
 SG_ VendorIdentification_20_1F85_20 m32 : 32|32@1+ (1,0) [0|4294967295] "" Vector__XXX
 SG_ VendorIdentification_1f_1F85_1F m31 : 32|32@1+ (1,0) [0|4294967295] "" Vector__XXX
 SG_ VendorIdentification_1e_1F85_1E m30 : 32|32@1+ (1,0) [0|4294967295] "" Vector__XXX
 SG_ VendorIdentification_1d_1F85_1D m29 : 32|32@1+ (1,0) [0|4294967295] "" Vector__XXX
 SG_ VendorIdentification_1c_1F85_1C m28 : 32|32@1+ (1,0) [0|4294967295] "" Vector__XXX
 SG_ VendorIdentification_1b_1F85_1B m27 : 32|32@1+ (1,0) [0|4294967295] "" Vector__XXX
 SG_ VendorIdentification_1a_1F85_1A m26 : 32|32@1+ (1,0) [0|4294967295] "" Vector__XXX
 SG_ VendorIdentification_19_1F85_19 m25 : 32|32@1+ (1,0) [0|4294967295] "" Vector__XXX
 SG_ VendorIdentification_18_1F85_18 m24 : 32|32@1+ (1,0) [0|4294967295] "" Vector__XXX
 SG_ VendorIdentification_17_1F85_17 m23 : 32|32@1+ (1,0) [0|4294967295] "" Vector__XXX
 SG_ VendorIdentification_16_1F85_16 m22 : 32|32@1+ (1,0) [0|4294967295] "" Vector__XXX
 SG_ VendorIdentification_15_1F85_15 m21 : 32|32@1+ (1,0) [0|4294967295] "" Vector__XXX
 SG_ VendorIdentification_14_1F85_14 m20 : 32|32@1+ (1,0) [0|4294967295] "" Vector__XXX
 SG_ VendorIdentification_13_1F85_13 m19 : 32|32@1+ (1,0) [0|4294967295] "" Vector__XXX
 SG_ VendorIdentification_12_1F85_12 m18 : 32|32@1+ (1,0) [0|4294967295] "" Vector__XXX
 SG_ VendorIdentification_11_1F85_11 m17 : 32|32@1+ (1,0) [0|4294967295] "" Vector__XXX
 SG_ VendorIdentification_10_1F85_10 m16 : 32|32@1+ (1,0) [0|4294967295] "" Vector__XXX
 SG_ VendorIdentification_f_1F85_0F m15 : 32|32@1+ (1,0) [0|4294967295] "" Vector__XXX
 SG_ VendorIdentification_e_1F85_0E m14 : 32|32@1+ (1,0) [0|4294967295] "" Vector__XXX
 SG_ VendorIdentification_d_1F85_0D m13 : 32|32@1+ (1,0) [0|4294967295] "" Vector__XXX
 SG_ VendorIdentification_c_1F85_0C m12 : 32|32@1+ (1,0) [0|4294967295] "" Vector__XXX
 SG_ VendorIdentification_b_1F85_0B m11 : 32|32@1+ (1,0) [0|4294967295] "" Vector__XXX
 SG_ VendorIdentification_a_1F85_0A m10 : 32|32@1+ (1,0) [0|4294967295] "" Vector__XXX
 SG_ VendorIdentification_9_1F85_09 m9 : 32|32@1+ (1,0) [0|4294967295] "" Vector__XXX
 SG_ VendorIdentification_8_1F85_08 m8 : 32|32@1+ (1,0) [0|4294967295] "" Vector__XXX
 SG_ VendorIdentification_7_1F85_07 m7 : 32|32@1+ (1,0) [0|4294967295] "" Vector__XXX
 SG_ VendorIdentification_6_1F85_06 m6 : 32|32@1+ (1,0) [0|4294967295] "" Vector__XXX
 SG_ VendorIdentification_5_1F85_05 m5 : 32|32@1+ (1,0) [0|4294967295] "" Vector__XXX
 SG_ VendorIdentification_4_1F85_04 m4 : 32|32@1+ (1,0) [0|4294967295] "" Vector__XXX
 SG_ VendorIdentification_3_1F85_03 m3 : 32|32@1+ (1,0) [0|4294967295] "" Vector__XXX
 SG_ VendorIdentification_2_1F85_02 m2 : 32|32@1+ (1,0) [0|4294967295] "" Vector__XXX
 SG_ VendorIdentification_1F85_01 m1 : 32|32@1+ (1,0) [0|4294967295] "" Vector__XXX
 SG_ NrOfObjects_1F85_00 m0 : 32|8@1+ (1,0) [0|255] "" Vector__XXX
 SG_ SubIndex_1F85 m8069M : 24|8@1+ (1,0) [0|127] "" Vector__XXX
 SG_ RequestGuard_All_1F83_80 m128 : 32|8@1+ (1,0) [0|255] "" Vector__XXX
 SG_ RequestGuard_1F83_7F m127 : 32|8@1+ (1,0) [0|255] "" Vector__XXX
 SG_ RequestGuard_1F83_7E m126 : 32|8@1+ (1,0) [0|255] "" Vector__XXX
 SG_ RequestGuard_1F83_7D m125 : 32|8@1+ (1,0) [0|255] "" Vector__XXX
 SG_ RequestGuard_1F83_7C m124 : 32|8@1+ (1,0) [0|255] "" Vector__XXX
 SG_ RequestGuard_1F83_7B m123 : 32|8@1+ (1,0) [0|255] "" Vector__XXX
 SG_ RequestGuard_1F83_7A m122 : 32|8@1+ (1,0) [0|255] "" Vector__XXX
 SG_ RequestGuard_1F83_79 m121 : 32|8@1+ (1,0) [0|255] "" Vector__XXX
 SG_ RequestGuard_1F83_78 m120 : 32|8@1+ (1,0) [0|255] "" Vector__XXX
 SG_ RequestGuard_1F83_77 m119 : 32|8@1+ (1,0) [0|255] "" Vector__XXX
 SG_ RequestGuard_1F83_76 m118 : 32|8@1+ (1,0) [0|255] "" Vector__XXX
 SG_ RequestGuard_1F83_75 m117 : 32|8@1+ (1,0) [0|255] "" Vector__XXX
 SG_ RequestGuard_1F83_74 m116 : 32|8@1+ (1,0) [0|255] "" Vector__XXX
 SG_ RequestGuard_1F83_73 m115 : 32|8@1+ (1,0) [0|255] "" Vector__XXX
 SG_ RequestGuard_1F83_72 m114 : 32|8@1+ (1,0) [0|255] "" Vector__XXX
 SG_ RequestGuard_1F83_71 m113 : 32|8@1+ (1,0) [0|255] "" Vector__XXX
 SG_ RequestGuard_1F83_70 m112 : 32|8@1+ (1,0) [0|255] "" Vector__XXX
 SG_ RequestGuard_1F83_6F m111 : 32|8@1+ (1,0) [0|255] "" Vector__XXX
 SG_ RequestGuard_1F83_6E m110 : 32|8@1+ (1,0) [0|255] "" Vector__XXX
 SG_ RequestGuard_1F83_6D m109 : 32|8@1+ (1,0) [0|255] "" Vector__XXX
 SG_ RequestGuard_1F83_6C m108 : 32|8@1+ (1,0) [0|255] "" Vector__XXX
 SG_ RequestGuard_1F83_6B m107 : 32|8@1+ (1,0) [0|255] "" Vector__XXX
 SG_ RequestGuard_1F83_6A m106 : 32|8@1+ (1,0) [0|255] "" Vector__XXX
 SG_ RequestGuard_1F83_69 m105 : 32|8@1+ (1,0) [0|255] "" Vector__XXX
 SG_ RequestGuard_1F83_68 m104 : 32|8@1+ (1,0) [0|255] "" Vector__XXX
 SG_ RequestGuard_1F83_67 m103 : 32|8@1+ (1,0) [0|255] "" Vector__XXX
 SG_ RequestGuard_1F83_66 m102 : 32|8@1+ (1,0) [0|255] "" Vector__XXX
 SG_ RequestGuard_1F83_65 m101 : 32|8@1+ (1,0) [0|255] "" Vector__XXX
 SG_ RequestGuard_1F83_64 m100 : 32|8@1+ (1,0) [0|255] "" Vector__XXX
 SG_ RequestGuard_1F83_63 m99 : 32|8@1+ (1,0) [0|255] "" Vector__XXX
 SG_ RequestGuard_1F83_62 m98 : 32|8@1+ (1,0) [0|255] "" Vector__XXX
 SG_ RequestGuard_1F83_61 m97 : 32|8@1+ (1,0) [0|255] "" Vector__XXX
 SG_ RequestGuard_1F83_60 m96 : 32|8@1+ (1,0) [0|255] "" Vector__XXX
 SG_ RequestGuard_1F83_5F m95 : 32|8@1+ (1,0) [0|255] "" Vector__XXX
 SG_ RequestGuard_1F83_5E m94 : 32|8@1+ (1,0) [0|255] "" Vector__XXX
 SG_ RequestGuard_1F83_5D m93 : 32|8@1+ (1,0) [0|255] "" Vector__XXX
 SG_ RequestGuard_1F83_5C m92 : 32|8@1+ (1,0) [0|255] "" Vector__XXX
 SG_ RequestGuard_1F83_5B m91 : 32|8@1+ (1,0) [0|255] "" Vector__XXX
 SG_ RequestGuard_1F83_5A m90 : 32|8@1+ (1,0) [0|255] "" Vector__XXX
 SG_ RequestGuard_1F83_59 m89 : 32|8@1+ (1,0) [0|255] "" Vector__XXX
 SG_ RequestGuard_1F83_58 m88 : 32|8@1+ (1,0) [0|255] "" Vector__XXX
 SG_ RequestGuard_1F83_57 m87 : 32|8@1+ (1,0) [0|255] "" Vector__XXX
 SG_ RequestGuard_1F83_56 m86 : 32|8@1+ (1,0) [0|255] "" Vector__XXX
 SG_ RequestGuard_1F83_55 m85 : 32|8@1+ (1,0) [0|255] "" Vector__XXX
 SG_ RequestGuard_1F83_54 m84 : 32|8@1+ (1,0) [0|255] "" Vector__XXX
 SG_ RequestGuard_1F83_53 m83 : 32|8@1+ (1,0) [0|255] "" Vector__XXX
 SG_ RequestGuard_1F83_52 m82 : 32|8@1+ (1,0) [0|255] "" Vector__XXX
 SG_ RequestGuard_1F83_51 m81 : 32|8@1+ (1,0) [0|255] "" Vector__XXX
 SG_ RequestGuard_1F83_50 m80 : 32|8@1+ (1,0) [0|255] "" Vector__XXX
 SG_ RequestGuard_1F83_4F m79 : 32|8@1+ (1,0) [0|255] "" Vector__XXX
 SG_ RequestGuard_1F83_4E m78 : 32|8@1+ (1,0) [0|255] "" Vector__XXX
 SG_ RequestGuard_1F83_4D m77 : 32|8@1+ (1,0) [0|255] "" Vector__XXX
 SG_ RequestGuard_1F83_4C m76 : 32|8@1+ (1,0) [0|255] "" Vector__XXX
 SG_ RequestGuard_1F83_4B m75 : 32|8@1+ (1,0) [0|255] "" Vector__XXX
 SG_ RequestGuard_1F83_4A m74 : 32|8@1+ (1,0) [0|255] "" Vector__XXX
 SG_ RequestGuard_1F83_49 m73 : 32|8@1+ (1,0) [0|255] "" Vector__XXX
 SG_ RequestGuard_1F83_48 m72 : 32|8@1+ (1,0) [0|255] "" Vector__XXX
 SG_ RequestGuard_1F83_47 m71 : 32|8@1+ (1,0) [0|255] "" Vector__XXX
 SG_ RequestGuard_1F83_46 m70 : 32|8@1+ (1,0) [0|255] "" Vector__XXX
 SG_ RequestGuard_1F83_45 m69 : 32|8@1+ (1,0) [0|255] "" Vector__XXX
 SG_ RequestGuard_1F83_44 m68 : 32|8@1+ (1,0) [0|255] "" Vector__XXX
 SG_ RequestGuard_1F83_43 m67 : 32|8@1+ (1,0) [0|255] "" Vector__XXX
 SG_ RequestGuard_1F83_42 m66 : 32|8@1+ (1,0) [0|255] "" Vector__XXX
 SG_ RequestGuard_1F83_41 m65 : 32|8@1+ (1,0) [0|255] "" Vector__XXX
 SG_ RequestGuard_1F83_40 m64 : 32|8@1+ (1,0) [0|255] "" Vector__XXX
 SG_ RequestGuard_1F83_3F m63 : 32|8@1+ (1,0) [0|255] "" Vector__XXX
 SG_ RequestGuard_1F83_3E m62 : 32|8@1+ (1,0) [0|255] "" Vector__XXX
 SG_ RequestGuard_1F83_3D m61 : 32|8@1+ (1,0) [0|255] "" Vector__XXX
 SG_ RequestGuard_1F83_3C m60 : 32|8@1+ (1,0) [0|255] "" Vector__XXX
 SG_ RequestGuard_1F83_3B m59 : 32|8@1+ (1,0) [0|255] "" Vector__XXX
 SG_ RequestGuard_1F83_3A m58 : 32|8@1+ (1,0) [0|255] "" Vector__XXX
 SG_ RequestGuard_1F83_39 m57 : 32|8@1+ (1,0) [0|255] "" Vector__XXX
 SG_ RequestGuard_1F83_38 m56 : 32|8@1+ (1,0) [0|255] "" Vector__XXX
 SG_ RequestGuard_1F83_37 m55 : 32|8@1+ (1,0) [0|255] "" Vector__XXX
 SG_ RequestGuard_1F83_36 m54 : 32|8@1+ (1,0) [0|255] "" Vector__XXX
 SG_ RequestGuard_1F83_35 m53 : 32|8@1+ (1,0) [0|255] "" Vector__XXX
 SG_ RequestGuard_1F83_34 m52 : 32|8@1+ (1,0) [0|255] "" Vector__XXX
 SG_ RequestGuard_1F83_33 m51 : 32|8@1+ (1,0) [0|255] "" Vector__XXX
 SG_ RequestGuard_1F83_32 m50 : 32|8@1+ (1,0) [0|255] "" Vector__XXX
 SG_ RequestGuard_1F83_31 m49 : 32|8@1+ (1,0) [0|255] "" Vector__XXX
 SG_ RequestGuard_1F83_30 m48 : 32|8@1+ (1,0) [0|255] "" Vector__XXX
 SG_ RequestGuard_1F83_2F m47 : 32|8@1+ (1,0) [0|255] "" Vector__XXX
 SG_ RequestGuard_1F83_2E m46 : 32|8@1+ (1,0) [0|255] "" Vector__XXX
 SG_ RequestGuard_1F83_2D m45 : 32|8@1+ (1,0) [0|255] "" Vector__XXX
 SG_ RequestGuard_1F83_2C m44 : 32|8@1+ (1,0) [0|255] "" Vector__XXX
 SG_ RequestGuard_1F83_2B m43 : 32|8@1+ (1,0) [0|255] "" Vector__XXX
 SG_ RequestGuard_1F83_2A m42 : 32|8@1+ (1,0) [0|255] "" Vector__XXX
 SG_ RequestGuard_1F83_29 m41 : 32|8@1+ (1,0) [0|255] "" Vector__XXX
 SG_ RequestGuard_1F83_28 m40 : 32|8@1+ (1,0) [0|255] "" Vector__XXX
 SG_ RequestGuard_1F83_27 m39 : 32|8@1+ (1,0) [0|255] "" Vector__XXX
 SG_ RequestGuard_1F83_26 m38 : 32|8@1+ (1,0) [0|255] "" Vector__XXX
 SG_ RequestGuard_1F83_25 m37 : 32|8@1+ (1,0) [0|255] "" Vector__XXX
 SG_ RequestGuard_1F83_24 m36 : 32|8@1+ (1,0) [0|255] "" Vector__XXX
 SG_ RequestGuard_1F83_23 m35 : 32|8@1+ (1,0) [0|255] "" Vector__XXX
 SG_ RequestGuard_1F83_22 m34 : 32|8@1+ (1,0) [0|255] "" Vector__XXX
 SG_ RequestGuard_1F83_21 m33 : 32|8@1+ (1,0) [0|255] "" Vector__XXX
 SG_ RequestGuard_1F83_20 m32 : 32|8@1+ (1,0) [0|255] "" Vector__XXX
 SG_ RequestGuard_1F83_1F m31 : 32|8@1+ (1,0) [0|255] "" Vector__XXX
 SG_ RequestGuard_1F83_1E m30 : 32|8@1+ (1,0) [0|255] "" Vector__XXX
 SG_ RequestGuard_1F83_1D m29 : 32|8@1+ (1,0) [0|255] "" Vector__XXX
 SG_ RequestGuard_1F83_1C m28 : 32|8@1+ (1,0) [0|255] "" Vector__XXX
 SG_ RequestGuard_1F83_1B m27 : 32|8@1+ (1,0) [0|255] "" Vector__XXX
 SG_ RequestGuard_1F83_1A m26 : 32|8@1+ (1,0) [0|255] "" Vector__XXX
 SG_ RequestGuard_1F83_19 m25 : 32|8@1+ (1,0) [0|255] "" Vector__XXX
 SG_ RequestGuard_1F83_18 m24 : 32|8@1+ (1,0) [0|255] "" Vector__XXX
 SG_ RequestGuard_1F83_17 m23 : 32|8@1+ (1,0) [0|255] "" Vector__XXX
 SG_ RequestGuard_1F83_16 m22 : 32|8@1+ (1,0) [0|255] "" Vector__XXX
 SG_ RequestGuard_1F83_15 m21 : 32|8@1+ (1,0) [0|255] "" Vector__XXX
 SG_ RequestGuard_1F83_14 m20 : 32|8@1+ (1,0) [0|255] "" Vector__XXX
 SG_ RequestGuard_1F83_13 m19 : 32|8@1+ (1,0) [0|255] "" Vector__XXX
 SG_ RequestGuard_1F83_12 m18 : 32|8@1+ (1,0) [0|255] "" Vector__XXX
 SG_ RequestGuard_1F83_11 m17 : 32|8@1+ (1,0) [0|255] "" Vector__XXX
 SG_ RequestGuard_1F83_10 m16 : 32|8@1+ (1,0) [0|255] "" Vector__XXX
 SG_ RequestGuard_1F83_0F m15 : 32|8@1+ (1,0) [0|255] "" Vector__XXX
 SG_ RequestGuard_1F83_0E m14 : 32|8@1+ (1,0) [0|255] "" Vector__XXX
 SG_ RequestGuard_1F83_0D m13 : 32|8@1+ (1,0) [0|255] "" Vector__XXX
 SG_ RequestGuard_1F83_0C m12 : 32|8@1+ (1,0) [0|255] "" Vector__XXX
 SG_ RequestGuard_1F83_0B m11 : 32|8@1+ (1,0) [0|255] "" Vector__XXX
 SG_ RequestGuard_1F83_0A m10 : 32|8@1+ (1,0) [0|255] "" Vector__XXX
 SG_ RequestGuard_1F83_09 m9 : 32|8@1+ (1,0) [0|255] "" Vector__XXX
 SG_ RequestGuard_1F83_08 m8 : 32|8@1+ (1,0) [0|255] "" Vector__XXX
 SG_ RequestGuard_1F83_07 m7 : 32|8@1+ (1,0) [0|255] "" Vector__XXX
 SG_ RequestGuard_1F83_06 m6 : 32|8@1+ (1,0) [0|255] "" Vector__XXX
 SG_ RequestGuard_1F83_05 m5 : 32|8@1+ (1,0) [0|255] "" Vector__XXX
 SG_ RequestGuard_1F83_04 m4 : 32|8@1+ (1,0) [0|255] "" Vector__XXX
 SG_ RequestGuard_1F83_03 m3 : 32|8@1+ (1,0) [0|255] "" Vector__XXX
 SG_ RequestGuard_1F83_02 m2 : 32|8@1+ (1,0) [0|255] "" Vector__XXX
 SG_ RequestGuard_1F83_01 m1 : 32|8@1+ (1,0) [0|255] "" Vector__XXX
 SG_ Highest_sub_index_supported_1F83 m0 : 32|8@1+ (1,0) [0|255] "" Vector__XXX
 SG_ SubIndex_1F83 m8067M : 24|8@1+ (1,0) [0|128] "" Vector__XXX
 SG_ RequestNMT_All_1F82_80 m128 : 32|8@1+ (1,0) [0|255] "" Vector__XXX
 SG_ RequestNMT_1F82_7F m127 : 32|8@1+ (1,0) [0|255] "" Vector__XXX
 SG_ RequestNMT_1F82_7E m126 : 32|8@1+ (1,0) [0|255] "" Vector__XXX
 SG_ RequestNMT_1F82_7D m125 : 32|8@1+ (1,0) [0|255] "" Vector__XXX
 SG_ RequestNMT_1F82_7C m124 : 32|8@1+ (1,0) [0|255] "" Vector__XXX
 SG_ RequestNMT_1F82_7B m123 : 32|8@1+ (1,0) [0|255] "" Vector__XXX
 SG_ RequestNMT_1F82_7A m122 : 32|8@1+ (1,0) [0|255] "" Vector__XXX
 SG_ RequestNMT_1F82_79 m121 : 32|8@1+ (1,0) [0|255] "" Vector__XXX
 SG_ RequestNMT_1F82_78 m120 : 32|8@1+ (1,0) [0|255] "" Vector__XXX
 SG_ RequestNMT_1F82_77 m119 : 32|8@1+ (1,0) [0|255] "" Vector__XXX
 SG_ RequestNMT_1F82_76 m118 : 32|8@1+ (1,0) [0|255] "" Vector__XXX
 SG_ RequestNMT_1F82_75 m117 : 32|8@1+ (1,0) [0|255] "" Vector__XXX
 SG_ RequestNMT_1F82_74 m116 : 32|8@1+ (1,0) [0|255] "" Vector__XXX
 SG_ RequestNMT_1F82_73 m115 : 32|8@1+ (1,0) [0|255] "" Vector__XXX
 SG_ RequestNMT_1F82_72 m114 : 32|8@1+ (1,0) [0|255] "" Vector__XXX
 SG_ RequestNMT_1F82_71 m113 : 32|8@1+ (1,0) [0|255] "" Vector__XXX
 SG_ RequestNMT_1F82_70 m112 : 32|8@1+ (1,0) [0|255] "" Vector__XXX
 SG_ RequestNMT_1F82_6F m111 : 32|8@1+ (1,0) [0|255] "" Vector__XXX
 SG_ RequestNMT_1F82_6E m110 : 32|8@1+ (1,0) [0|255] "" Vector__XXX
 SG_ RequestNMT_1F82_6D m109 : 32|8@1+ (1,0) [0|255] "" Vector__XXX
 SG_ RequestNMT_1F82_6C m108 : 32|8@1+ (1,0) [0|255] "" Vector__XXX
 SG_ RequestNMT_1F82_6B m107 : 32|8@1+ (1,0) [0|255] "" Vector__XXX
 SG_ RequestNMT_1F82_6A m106 : 32|8@1+ (1,0) [0|255] "" Vector__XXX
 SG_ RequestNMT_1F82_69 m105 : 32|8@1+ (1,0) [0|255] "" Vector__XXX
 SG_ RequestNMT_1F82_68 m104 : 32|8@1+ (1,0) [0|255] "" Vector__XXX
 SG_ RequestNMT_1F82_67 m103 : 32|8@1+ (1,0) [0|255] "" Vector__XXX
 SG_ RequestNMT_1F82_66 m102 : 32|8@1+ (1,0) [0|255] "" Vector__XXX
 SG_ RequestNMT_1F82_65 m101 : 32|8@1+ (1,0) [0|255] "" Vector__XXX
 SG_ RequestNMT_1F82_64 m100 : 32|8@1+ (1,0) [0|255] "" Vector__XXX
 SG_ RequestNMT_1F82_63 m99 : 32|8@1+ (1,0) [0|255] "" Vector__XXX
 SG_ RequestNMT_1F82_62 m98 : 32|8@1+ (1,0) [0|255] "" Vector__XXX
 SG_ RequestNMT_1F82_61 m97 : 32|8@1+ (1,0) [0|255] "" Vector__XXX
 SG_ RequestNMT_1F82_60 m96 : 32|8@1+ (1,0) [0|255] "" Vector__XXX
 SG_ RequestNMT_1F82_5F m95 : 32|8@1+ (1,0) [0|255] "" Vector__XXX
 SG_ RequestNMT_1F82_5E m94 : 32|8@1+ (1,0) [0|255] "" Vector__XXX
 SG_ RequestNMT_1F82_5D m93 : 32|8@1+ (1,0) [0|255] "" Vector__XXX
 SG_ RequestNMT_1F82_5C m92 : 32|8@1+ (1,0) [0|255] "" Vector__XXX
 SG_ RequestNMT_1F82_5B m91 : 32|8@1+ (1,0) [0|255] "" Vector__XXX
 SG_ RequestNMT_1F82_5A m90 : 32|8@1+ (1,0) [0|255] "" Vector__XXX
 SG_ RequestNMT_1F82_59 m89 : 32|8@1+ (1,0) [0|255] "" Vector__XXX
 SG_ RequestNMT_1F82_58 m88 : 32|8@1+ (1,0) [0|255] "" Vector__XXX
 SG_ RequestNMT_1F82_57 m87 : 32|8@1+ (1,0) [0|255] "" Vector__XXX
 SG_ RequestNMT_1F82_56 m86 : 32|8@1+ (1,0) [0|255] "" Vector__XXX
 SG_ RequestNMT_1F82_55 m85 : 32|8@1+ (1,0) [0|255] "" Vector__XXX
 SG_ RequestNMT_1F82_54 m84 : 32|8@1+ (1,0) [0|255] "" Vector__XXX
 SG_ RequestNMT_1F82_53 m83 : 32|8@1+ (1,0) [0|255] "" Vector__XXX
 SG_ RequestNMT_1F82_52 m82 : 32|8@1+ (1,0) [0|255] "" Vector__XXX
 SG_ RequestNMT_1F82_51 m81 : 32|8@1+ (1,0) [0|255] "" Vector__XXX
 SG_ RequestNMT_1F82_50 m80 : 32|8@1+ (1,0) [0|255] "" Vector__XXX
 SG_ RequestNMT_1F82_4F m79 : 32|8@1+ (1,0) [0|255] "" Vector__XXX
 SG_ RequestNMT_1F82_4E m78 : 32|8@1+ (1,0) [0|255] "" Vector__XXX
 SG_ RequestNMT_1F82_4D m77 : 32|8@1+ (1,0) [0|255] "" Vector__XXX
 SG_ RequestNMT_1F82_4C m76 : 32|8@1+ (1,0) [0|255] "" Vector__XXX
 SG_ RequestNMT_1F82_4B m75 : 32|8@1+ (1,0) [0|255] "" Vector__XXX
 SG_ RequestNMT_1F82_4A m74 : 32|8@1+ (1,0) [0|255] "" Vector__XXX
 SG_ RequestNMT_1F82_49 m73 : 32|8@1+ (1,0) [0|255] "" Vector__XXX
 SG_ RequestNMT_1F82_48 m72 : 32|8@1+ (1,0) [0|255] "" Vector__XXX
 SG_ RequestNMT_1F82_47 m71 : 32|8@1+ (1,0) [0|255] "" Vector__XXX
 SG_ RequestNMT_1F82_46 m70 : 32|8@1+ (1,0) [0|255] "" Vector__XXX
 SG_ RequestNMT_1F82_45 m69 : 32|8@1+ (1,0) [0|255] "" Vector__XXX
 SG_ RequestNMT_1F82_44 m68 : 32|8@1+ (1,0) [0|255] "" Vector__XXX
 SG_ RequestNMT_1F82_43 m67 : 32|8@1+ (1,0) [0|255] "" Vector__XXX
 SG_ RequestNMT_1F82_42 m66 : 32|8@1+ (1,0) [0|255] "" Vector__XXX
 SG_ RequestNMT_1F82_41 m65 : 32|8@1+ (1,0) [0|255] "" Vector__XXX
 SG_ RequestNMT_1F82_40 m64 : 32|8@1+ (1,0) [0|255] "" Vector__XXX
 SG_ RequestNMT_1F82_3F m63 : 32|8@1+ (1,0) [0|255] "" Vector__XXX
 SG_ RequestNMT_1F82_3E m62 : 32|8@1+ (1,0) [0|255] "" Vector__XXX
 SG_ RequestNMT_1F82_3D m61 : 32|8@1+ (1,0) [0|255] "" Vector__XXX
 SG_ RequestNMT_1F82_3C m60 : 32|8@1+ (1,0) [0|255] "" Vector__XXX
 SG_ RequestNMT_1F82_3B m59 : 32|8@1+ (1,0) [0|255] "" Vector__XXX
 SG_ RequestNMT_1F82_3A m58 : 32|8@1+ (1,0) [0|255] "" Vector__XXX
 SG_ RequestNMT_1F82_39 m57 : 32|8@1+ (1,0) [0|255] "" Vector__XXX
 SG_ RequestNMT_1F82_38 m56 : 32|8@1+ (1,0) [0|255] "" Vector__XXX
 SG_ RequestNMT_1F82_37 m55 : 32|8@1+ (1,0) [0|255] "" Vector__XXX
 SG_ RequestNMT_1F82_36 m54 : 32|8@1+ (1,0) [0|255] "" Vector__XXX
 SG_ RequestNMT_1F82_35 m53 : 32|8@1+ (1,0) [0|255] "" Vector__XXX
 SG_ RequestNMT_1F82_34 m52 : 32|8@1+ (1,0) [0|255] "" Vector__XXX
 SG_ RequestNMT_1F82_33 m51 : 32|8@1+ (1,0) [0|255] "" Vector__XXX
 SG_ RequestNMT_1F82_32 m50 : 32|8@1+ (1,0) [0|255] "" Vector__XXX
 SG_ RequestNMT_1F82_31 m49 : 32|8@1+ (1,0) [0|255] "" Vector__XXX
 SG_ RequestNMT_1F82_30 m48 : 32|8@1+ (1,0) [0|255] "" Vector__XXX
 SG_ RequestNMT_1F82_2F m47 : 32|8@1+ (1,0) [0|255] "" Vector__XXX
 SG_ RequestNMT_1F82_2E m46 : 32|8@1+ (1,0) [0|255] "" Vector__XXX
 SG_ RequestNMT_1F82_2D m45 : 32|8@1+ (1,0) [0|255] "" Vector__XXX
 SG_ RequestNMT_1F82_2C m44 : 32|8@1+ (1,0) [0|255] "" Vector__XXX
 SG_ RequestNMT_1F82_2B m43 : 32|8@1+ (1,0) [0|255] "" Vector__XXX
 SG_ RequestNMT_1F82_2A m42 : 32|8@1+ (1,0) [0|255] "" Vector__XXX
 SG_ RequestNMT_1F82_29 m41 : 32|8@1+ (1,0) [0|255] "" Vector__XXX
 SG_ RequestNMT_1F82_28 m40 : 32|8@1+ (1,0) [0|255] "" Vector__XXX
 SG_ RequestNMT_1F82_27 m39 : 32|8@1+ (1,0) [0|255] "" Vector__XXX
 SG_ RequestNMT_1F82_26 m38 : 32|8@1+ (1,0) [0|255] "" Vector__XXX
 SG_ RequestNMT_1F82_25 m37 : 32|8@1+ (1,0) [0|255] "" Vector__XXX
 SG_ RequestNMT_1F82_24 m36 : 32|8@1+ (1,0) [0|255] "" Vector__XXX
 SG_ RequestNMT_1F82_23 m35 : 32|8@1+ (1,0) [0|255] "" Vector__XXX
 SG_ RequestNMT_1F82_22 m34 : 32|8@1+ (1,0) [0|255] "" Vector__XXX
 SG_ RequestNMT_1F82_21 m33 : 32|8@1+ (1,0) [0|255] "" Vector__XXX
 SG_ RequestNMT_1F82_20 m32 : 32|8@1+ (1,0) [0|255] "" Vector__XXX
 SG_ RequestNMT_1F82_1F m31 : 32|8@1+ (1,0) [0|255] "" Vector__XXX
 SG_ RequestNMT_1F82_1E m30 : 32|8@1+ (1,0) [0|255] "" Vector__XXX
 SG_ RequestNMT_1F82_1D m29 : 32|8@1+ (1,0) [0|255] "" Vector__XXX
 SG_ RequestNMT_1F82_1C m28 : 32|8@1+ (1,0) [0|255] "" Vector__XXX
 SG_ RequestNMT_1F82_1B m27 : 32|8@1+ (1,0) [0|255] "" Vector__XXX
 SG_ RequestNMT_1F82_1A m26 : 32|8@1+ (1,0) [0|255] "" Vector__XXX
 SG_ RequestNMT_1F82_19 m25 : 32|8@1+ (1,0) [0|255] "" Vector__XXX
 SG_ RequestNMT_1F82_18 m24 : 32|8@1+ (1,0) [0|255] "" Vector__XXX
 SG_ RequestNMT_1F82_17 m23 : 32|8@1+ (1,0) [0|255] "" Vector__XXX
 SG_ RequestNMT_1F82_16 m22 : 32|8@1+ (1,0) [0|255] "" Vector__XXX
 SG_ RequestNMT_1F82_15 m21 : 32|8@1+ (1,0) [0|255] "" Vector__XXX
 SG_ RequestNMT_1F82_14 m20 : 32|8@1+ (1,0) [0|255] "" Vector__XXX
 SG_ RequestNMT_1F82_13 m19 : 32|8@1+ (1,0) [0|255] "" Vector__XXX
 SG_ RequestNMT_1F82_12 m18 : 32|8@1+ (1,0) [0|255] "" Vector__XXX
 SG_ RequestNMT_1F82_11 m17 : 32|8@1+ (1,0) [0|255] "" Vector__XXX
 SG_ RequestNMT_1F82_10 m16 : 32|8@1+ (1,0) [0|255] "" Vector__XXX
 SG_ RequestNMT_1F82_0F m15 : 32|8@1+ (1,0) [0|255] "" Vector__XXX
 SG_ RequestNMT_1F82_0E m14 : 32|8@1+ (1,0) [0|255] "" Vector__XXX
 SG_ RequestNMT_1F82_0D m13 : 32|8@1+ (1,0) [0|255] "" Vector__XXX
 SG_ RequestNMT_1F82_0C m12 : 32|8@1+ (1,0) [0|255] "" Vector__XXX
 SG_ RequestNMT_1F82_0B m11 : 32|8@1+ (1,0) [0|255] "" Vector__XXX
 SG_ RequestNMT_1F82_0A m10 : 32|8@1+ (1,0) [0|255] "" Vector__XXX
 SG_ RequestNMT_1F82_09 m9 : 32|8@1+ (1,0) [0|255] "" Vector__XXX
 SG_ RequestNMT_1F82_08 m8 : 32|8@1+ (1,0) [0|255] "" Vector__XXX
 SG_ RequestNMT_1F82_07 m7 : 32|8@1+ (1,0) [0|255] "" Vector__XXX
 SG_ RequestNMT_1F82_06 m6 : 32|8@1+ (1,0) [0|255] "" Vector__XXX
 SG_ RequestNMT_1F82_05 m5 : 32|8@1+ (1,0) [0|255] "" Vector__XXX
 SG_ RequestNMT_1F82_04 m4 : 32|8@1+ (1,0) [0|255] "" Vector__XXX
 SG_ RequestNMT_1F82_03 m3 : 32|8@1+ (1,0) [0|255] "" Vector__XXX
 SG_ RequestNMT_1F82_02 m2 : 32|8@1+ (1,0) [0|255] "" Vector__XXX
 SG_ RequestNMT_1F82_01 m1 : 32|8@1+ (1,0) [0|255] "" Vector__XXX
 SG_ Highest_sub_index_supported_1F82 m0 : 32|8@1+ (1,0) [0|255] "" Vector__XXX
 SG_ SubIndex_1F82 m8066M : 24|8@1+ (1,0) [0|128] "" Vector__XXX
 SG_ SlaveAssignment_1F81_7F m127 : 32|32@1+ (1,0) [0|4294967295] "" Vector__XXX
 SG_ SlaveAssignment_1F81_7E m126 : 32|32@1+ (1,0) [0|4294967295] "" Vector__XXX
 SG_ SlaveAssignment_1F81_7D m125 : 32|32@1+ (1,0) [0|4294967295] "" Vector__XXX
 SG_ SlaveAssignment_1F81_7C m124 : 32|32@1+ (1,0) [0|4294967295] "" Vector__XXX
 SG_ SlaveAssignment_1F81_7B m123 : 32|32@1+ (1,0) [0|4294967295] "" Vector__XXX
 SG_ SlaveAssignment_1F81_7A m122 : 32|32@1+ (1,0) [0|4294967295] "" Vector__XXX
 SG_ SlaveAssignment_1F81_79 m121 : 32|32@1+ (1,0) [0|4294967295] "" Vector__XXX
 SG_ SlaveAssignment_1F81_78 m120 : 32|32@1+ (1,0) [0|4294967295] "" Vector__XXX
 SG_ SubIndex_1F81 m8065M : 24|8@1+ (1,0) [0|127] "" Vector__XXX
 SG_ Index m1M : 8|16@1+ (1,0) [4096|42624] "" Vector__XXX
 SG_ SCS M : 5|3@1+ (1,0) [0|6] "" Vector__XXX

BA_DEF_ BU_  "CO_DCF" STRING ;
BA_DEF_ BU_  "CO_ID" INT 0 127;
BA_DEF_ BU_  "CO_NVSEGMENT0" STRING ;
BA_DEF_ BU_  "CO_NVSEGMENT1" STRING ;
BA_DEF_ BU_  "CO_NVSEGMENT2" STRING ;
BA_DEF_ BU_  "CO_NVSEGMENT3" STRING ;
BA_DEF_ BU_  "CO_NVSEGMENT4" STRING ;
BA_DEF_ BU_  "CO_NVSEGMENT5" STRING ;
BA_DEF_ BU_  "CO_NVSEGMENT6" STRING ;
BA_DEF_ BU_  "CO_NVSEGMENT7" STRING ;
BA_DEF_ BU_  "CO_NVSEGMENT8" STRING ;
BA_DEF_ BU_  "CO_NVSEGMENT9" STRING ;
BA_DEF_ BU_  "CO_NVSEGMENT10" STRING ;
BA_DEF_ BU_  "CO_NVSEGMENT11" STRING ;
BA_DEF_ BU_  "CO_NVSEGMENT12" STRING ;
BA_DEF_ BU_  "CO_NVSEGMENT13" STRING ;
BA_DEF_ BU_  "CO_NVSEGMENT14" STRING ;
BA_DEF_ BU_  "CO_NVSEGMENT15" STRING ;
BA_DEF_ BU_  "CO_NVSEGMENT16" STRING ;
BA_DEF_ BU_  "CO_NVSEGMENT17" STRING ;
BA_DEF_ BU_  "CO_NVSEGMENT18" STRING ;
BA_DEF_ BU_  "CO_NVSEGMENT19" STRING ;
BA_DEF_ BU_  "CO_NVSEGMENT20" STRING ;
BA_DEF_ BU_  "CO_NVSEGMENT21" STRING ;
BA_DEF_ BU_  "CO_NVSEGMENT22" STRING ;
BA_DEF_ BU_  "CO_NVSEGMENT23" STRING ;
BA_DEF_ BU_  "CO_NVSEGMENT24" STRING ;
BA_DEF_ BU_  "CO_NVSEGMENT25" STRING ;
BA_DEF_ BU_  "CO_NVSEGMENT26" STRING ;
BA_DEF_ BU_  "CO_NVSEGMENT27" STRING ;
BA_DEF_ BU_  "CO_NVSEGMENT28" STRING ;
BA_DEF_ BU_  "CO_NVSEGMENT29" STRING ;
BA_DEF_ BU_  "CO_NVSEGMENT30" STRING ;
BA_DEF_ BU_  "CO_NVSEGMENT31" STRING ;
BA_DEF_ BU_  "CO_NVSEGMENT32" STRING ;
BA_DEF_ BU_  "CO_NVSEGMENT33" STRING ;
BA_DEF_ BU_  "CO_NVSEGMENT34" STRING ;
BA_DEF_ BU_  "CO_NVSEGMENT35" STRING ;
BA_DEF_ BU_  "CO_NVSEGMENT36" STRING ;
BA_DEF_ BU_  "CO_NVSEGMENT37" STRING ;
BA_DEF_ BU_  "CO_NVSEGMENT38" STRING ;
BA_DEF_ BU_  "CO_NVSEGMENT39" STRING ;
BA_DEF_ BU_  "CO_NVSEGMENT40" STRING ;
BA_DEF_ BU_  "CO_NVSEGMENT41" STRING ;
BA_DEF_ BU_  "CO_NVSEGMENT42" STRING ;
BA_DEF_ BU_  "CO_NVSEGMENT43" STRING ;
BA_DEF_ BU_  "CO_NVSEGMENT44" STRING ;
BA_DEF_ BU_  "CO_NVSEGMENT45" STRING ;
BA_DEF_  "OptionLoadDCF" INT 0 1;
BA_DEF_ BO_  "GenMsgSendType" ENUM  "Cyclic","SendType1","SendType2","SendType3","SendType4","SendType5","SendType6","SendType7","SendType8","SendType9";
BA_DEF_ BO_  "GenMsgCycleTime" INT 0 0;
BA_DEF_ SG_  "GenSigStartValue" INT 0 0;
BA_DEF_ BO_  "CO_MsgCategory" INT 0 0;
BA_DEF_  "CO_MsgColourSupported" INT 0 1;
BA_DEF_  "GeneratedBy" STRING ;
BA_DEF_  "CANopenApplProfile" INT 0 0;
BA_DEF_  "ProtocolType" STRING ;
BA_DEF_  "AUTOGENERATION" INT 0 1;
BA_DEF_ SG_  "SystemSignalLongSymbol" STRING ;
BA_DEF_DEF_  "CO_DCF" "";
BA_DEF_DEF_  "CO_ID" 0;
BA_DEF_DEF_  "CO_NVSEGMENT0" "";
BA_DEF_DEF_  "CO_NVSEGMENT1" "";
BA_DEF_DEF_  "CO_NVSEGMENT2" "";
BA_DEF_DEF_  "CO_NVSEGMENT3" "";
BA_DEF_DEF_  "CO_NVSEGMENT4" "";
BA_DEF_DEF_  "CO_NVSEGMENT5" "";
BA_DEF_DEF_  "CO_NVSEGMENT6" "";
BA_DEF_DEF_  "CO_NVSEGMENT7" "";
BA_DEF_DEF_  "CO_NVSEGMENT8" "";
BA_DEF_DEF_  "CO_NVSEGMENT9" "";
BA_DEF_DEF_  "CO_NVSEGMENT10" "";
BA_DEF_DEF_  "CO_NVSEGMENT11" "";
BA_DEF_DEF_  "CO_NVSEGMENT12" "";
BA_DEF_DEF_  "CO_NVSEGMENT13" "";
BA_DEF_DEF_  "CO_NVSEGMENT14" "";
BA_DEF_DEF_  "CO_NVSEGMENT15" "";
BA_DEF_DEF_  "CO_NVSEGMENT16" "";
BA_DEF_DEF_  "CO_NVSEGMENT17" "";
BA_DEF_DEF_  "CO_NVSEGMENT18" "";
BA_DEF_DEF_  "CO_NVSEGMENT19" "";
BA_DEF_DEF_  "CO_NVSEGMENT20" "";
BA_DEF_DEF_  "CO_NVSEGMENT21" "";
BA_DEF_DEF_  "CO_NVSEGMENT22" "";
BA_DEF_DEF_  "CO_NVSEGMENT23" "";
BA_DEF_DEF_  "CO_NVSEGMENT24" "";
BA_DEF_DEF_  "CO_NVSEGMENT25" "";
BA_DEF_DEF_  "CO_NVSEGMENT26" "";
BA_DEF_DEF_  "CO_NVSEGMENT27" "";
BA_DEF_DEF_  "CO_NVSEGMENT28" "";
BA_DEF_DEF_  "CO_NVSEGMENT29" "";
BA_DEF_DEF_  "CO_NVSEGMENT30" "";
BA_DEF_DEF_  "CO_NVSEGMENT31" "";
BA_DEF_DEF_  "CO_NVSEGMENT32" "";
BA_DEF_DEF_  "CO_NVSEGMENT33" "";
BA_DEF_DEF_  "CO_NVSEGMENT34" "";
BA_DEF_DEF_  "CO_NVSEGMENT35" "";
BA_DEF_DEF_  "CO_NVSEGMENT36" "";
BA_DEF_DEF_  "CO_NVSEGMENT37" "";
BA_DEF_DEF_  "CO_NVSEGMENT38" "";
BA_DEF_DEF_  "CO_NVSEGMENT39" "";
BA_DEF_DEF_  "CO_NVSEGMENT40" "";
BA_DEF_DEF_  "CO_NVSEGMENT41" "";
BA_DEF_DEF_  "CO_NVSEGMENT42" "";
BA_DEF_DEF_  "CO_NVSEGMENT43" "";
BA_DEF_DEF_  "CO_NVSEGMENT44" "";
BA_DEF_DEF_  "CO_NVSEGMENT45" "";
BA_DEF_DEF_  "OptionLoadDCF" 0;
BA_DEF_DEF_  "GenMsgSendType" "";
BA_DEF_DEF_  "GenMsgCycleTime" 0;
BA_DEF_DEF_  "GenSigStartValue" 0;
BA_DEF_DEF_  "CO_MsgCategory" 0;
BA_DEF_DEF_  "CO_MsgColourSupported" 1;
BA_DEF_DEF_  "GeneratedBy" "";
BA_DEF_DEF_  "CANopenApplProfile" 301;
BA_DEF_DEF_  "ProtocolType" "CANopen";
BA_DEF_DEF_  "AUTOGENERATION" 0;
BA_DEF_DEF_  "SystemSignalLongSymbol" "";
BA_ "OptionLoadDCF" 1;
BA_ "GeneratedBy" "CANoe 17.3.91";
BA_ "AUTOGENERATION" 1;
BA_ "CO_DCF" BU_ TTGateway_ID2 "TTGateway_ID2.dcf";
BA_ "CO_ID" BU_ TTGateway_ID2 2;
BA_ "CO_DCF" BU_ Master_ID1 "Master_ID1.dcf";
BA_ "CO_ID" BU_ Master_ID1 1;
BA_ "CO_DCF" BU_ SupportFront_ID12 "SupportFront_ID12.dcf";
BA_ "CO_ID" BU_ SupportFront_ID12 12;
BA_ "CO_DCF" BU_ LadderDrive_ID11 "LadderDrive_ID11.dcf";
BA_ "CO_ID" BU_ LadderDrive_ID11 11;
BA_ "CO_DCF" BU_ SupportRear_ID13 "SupportRear_ID13.dcf";
BA_ "CO_ID" BU_ SupportRear_ID13 13;
BA_ "CO_DCF" BU_ ControlPanel_ID10 "ControlPanel_ID10.dcf";
BA_ "CO_ID" BU_ ControlPanel_ID10 10;
BA_ "CO_MsgCategory" BO_ 1794 505;
BA_ "CO_MsgCategory" BO_ 1410 410;
BA_ "CO_MsgCategory" BO_ 1538 405;
BA_ "CO_MsgCategory" BO_ 130 205;
BA_ "CO_MsgCategory" BO_ 128 110;
BA_ "GenMsgSendType" BO_ 1793 0;
BA_ "GenMsgCycleTime" BO_ 1793 500;
BA_ "CO_MsgCategory" BO_ 1793 505;
BA_ "CO_MsgCategory" BO_ 1409 410;
BA_ "SystemSignalLongSymbol" SG_ 1410 requested_engine_speed_minimum_v "requested_engine_speed_minimum_value_range_614A_03";
BA_ "GenSigStartValue" SG_ 1410 requested_engine_speed_maximum_v 64255;
BA_ "SystemSignalLongSymbol" SG_ 1410 requested_engine_speed_maximum_v "requested_engine_speed_maximum_value_range_614A_02";
BA_ "SystemSignalLongSymbol" SG_ 1410 requested_engine_speed_value_614 "requested_engine_speed_value_614A_01";
BA_ "GenSigStartValue" SG_ 1410 requested_engine_speed_number_of 3;
BA_ "SystemSignalLongSymbol" SG_ 1410 requested_engine_speed_number_of "requested_engine_speed_number_of_entries_614A_00";
BA_ "SystemSignalLongSymbol" SG_ 1410 requested_engine_speed_lower_lim "requested_engine_speed_lower_limit_minimum_value_range_6142_03";
BA_ "GenSigStartValue" SG_ 1410 requested_engine_speed_lowe_0000 64255;
BA_ "SystemSignalLongSymbol" SG_ 1410 requested_engine_speed_lowe_0000 "requested_engine_speed_lower_limit_maximum_value_range_6142_02";
BA_ "GenSigStartValue" SG_ 1410 requested_engine_speed_lowe_0001 65535;
BA_ "SystemSignalLongSymbol" SG_ 1410 requested_engine_speed_lowe_0001 "requested_engine_speed_lower_limit_value_6142_01";
BA_ "GenSigStartValue" SG_ 1410 requested_engine_speed_lowe_0002 3;
BA_ "SystemSignalLongSymbol" SG_ 1410 requested_engine_speed_lowe_0002 "requested_engine_speed_lower_limit_number_of_entries_6142_00";
BA_ "SystemSignalLongSymbol" SG_ 1410 requested_engine_speed_upper_lim "requested_engine_speed_upper_limit_minimum_value_range_6140_03";
BA_ "GenSigStartValue" SG_ 1410 requested_engine_speed_uppe_0000 64255;
BA_ "SystemSignalLongSymbol" SG_ 1410 requested_engine_speed_uppe_0000 "requested_engine_speed_upper_limit_maximum_value_range_6140_02";
BA_ "GenSigStartValue" SG_ 1410 requested_engine_speed_uppe_0001 65535;
BA_ "SystemSignalLongSymbol" SG_ 1410 requested_engine_speed_uppe_0001 "requested_engine_speed_upper_limit_value_6140_01";
BA_ "GenSigStartValue" SG_ 1410 requested_engine_speed_uppe_0002 3;
BA_ "SystemSignalLongSymbol" SG_ 1410 requested_engine_speed_uppe_0002 "requested_engine_speed_upper_limit_number_of_entries_6140_00";
BA_ "GenSigStartValue" SG_ 1410 engine_stop_switch_Bit_1_613F_01 1;
BA_ "GenSigStartValue" SG_ 1410 engine_stop_switch_Number_of_ent 1;
BA_ "SystemSignalLongSymbol" SG_ 1410 engine_stop_switch_Number_of_ent "engine_stop_switch_Number_of_entries_613F_00";
BA_ "GenSigStartValue" SG_ 1410 engine_start_switch_Bit_1_613E_0 1;
BA_ "SystemSignalLongSymbol" SG_ 1410 engine_start_switch_Bit_1_613E_0 "engine_start_switch_Bit_1_613E_01";
BA_ "GenSigStartValue" SG_ 1410 engine_start_switch_Number_of_en 1;
BA_ "SystemSignalLongSymbol" SG_ 1410 engine_start_switch_Number_of_en "engine_start_switch_Number_of_entries_613E_00";
BA_ "SystemSignalLongSymbol" SG_ 1410 first_clutch_dependent_PTO_switc "first_clutch_dependent_PTO_switch_Bit_1_6136_01";
BA_ "GenSigStartValue" SG_ 1410 first_clutch_dependent_PTO__0000 1;
BA_ "SystemSignalLongSymbol" SG_ 1410 first_clutch_dependent_PTO__0000 "first_clutch_dependent_PTO_switch_Number_of_entries_6136_00";
BA_ "SystemSignalLongSymbol" SG_ 1410 first_engine_mounted_PTO_feedbac "first_engine_mounted_PTO_feedback_Bit_1_6131_01";
BA_ "GenSigStartValue" SG_ 1410 first_engine_mounted_PTO_fe_0000 1;
BA_ "SystemSignalLongSymbol" SG_ 1410 first_engine_mounted_PTO_fe_0000 "first_engine_mounted_PTO_feedback_Number_of_entries_6131_00";
BA_ "GenSigStartValue" SG_ 1410 PTOSwitch_6113_05 1;
BA_ "SystemSignalLongSymbol" SG_ 1410 engine_speed_minimum_value_range "engine_speed_minimum_value_range_6113_03";
BA_ "GenSigStartValue" SG_ 1410 engine_speed_maximum_value_range 64255;
BA_ "SystemSignalLongSymbol" SG_ 1410 engine_speed_maximum_value_range "engine_speed_maximum_value_range_6113_02";
BA_ "GenSigStartValue" SG_ 1410 EngineSpeed_6113_01 65535;
BA_ "GenSigStartValue" SG_ 1410 NrOfObjects_6113_00 5;
BA_ "GenSigStartValue" SG_ 1410 current_gear_minimum_value_range 4294967171;
BA_ "SystemSignalLongSymbol" SG_ 1410 current_gear_minimum_value_range "current_gear_minimum_value_range_610C_03";
BA_ "GenSigStartValue" SG_ 1410 current_gear_maximum_value_range 125;
BA_ "SystemSignalLongSymbol" SG_ 1410 current_gear_maximum_value_range "current_gear_maximum_value_range_610C_02";
BA_ "GenSigStartValue" SG_ 1410 NrOfObjects_610C_00 3;
BA_ "SystemSignalLongSymbol" SG_ 1410 wheel_based_vehicle_speed_minimu "wheel_based_vehicle_speed_minimum_value_range_6006_03";
BA_ "GenSigStartValue" SG_ 1410 wheel_based_vehicle_speed_maximu 64000;
BA_ "SystemSignalLongSymbol" SG_ 1410 wheel_based_vehicle_speed_maximu "wheel_based_vehicle_speed_maximum_value_range_6006_02";
BA_ "GenSigStartValue" SG_ 1410 wheel_based_vehicle_speed_value_ 65535;
BA_ "SystemSignalLongSymbol" SG_ 1410 wheel_based_vehicle_speed_value_ "wheel_based_vehicle_speed_value_6006_01";
BA_ "GenSigStartValue" SG_ 1410 wheel_based_vehicle_speed_number 3;
BA_ "SystemSignalLongSymbol" SG_ 1410 wheel_based_vehicle_speed_number "wheel_based_vehicle_speed_number_of_entries_6006_00";
BA_ "SystemSignalLongSymbol" SG_ 1410 park_brake_demand_value_minimum_ "park_brake_demand_value_minimum_value_range_6000_03";
BA_ "GenSigStartValue" SG_ 1410 park_brake_demand_value_maximum_ 250;
BA_ "SystemSignalLongSymbol" SG_ 1410 park_brake_demand_value_maximum_ "park_brake_demand_value_maximum_value_range_6000_02";
BA_ "GenSigStartValue" SG_ 1410 ParkBrakeDemandValue_6000_01 1;
BA_ "GenSigStartValue" SG_ 1410 NrOfObjects_6000_00 3;
BA_ "GenSigStartValue" SG_ 1410 mappedObj5_1A00_05 1628635408;
BA_ "GenSigStartValue" SG_ 1410 mappedObj4_1A00_04 1611006224;
BA_ "GenSigStartValue" SG_ 1410 mappedObj3_1A00_03 1630601480;
BA_ "GenSigStartValue" SG_ 1410 mappedObj2_1A00_02 1610613000;
BA_ "GenSigStartValue" SG_ 1410 mappedObj1_1A00_01 1628176648;
BA_ "GenSigStartValue" SG_ 1410 NrOfMappedObjects_1A00_00 5;
BA_ "GenSigStartValue" SG_ 1410 TransmissionType_1802_02 255;
BA_ "GenSigStartValue" SG_ 1410 COB_ID_1802_01 2147484546;
BA_ "GenSigStartValue" SG_ 1410 Highest_sub_index_supported_1802 5;
BA_ "SystemSignalLongSymbol" SG_ 1410 Highest_sub_index_supported_1802 "Highest_sub_index_supported_1802_00";
BA_ "GenSigStartValue" SG_ 1410 TransmissionType_1801_02 255;
BA_ "GenSigStartValue" SG_ 1410 COB_ID_1801_01 2147484290;
BA_ "GenSigStartValue" SG_ 1410 Highest_sub_index_supported_1801 5;
BA_ "SystemSignalLongSymbol" SG_ 1410 Highest_sub_index_supported_1801 "Highest_sub_index_supported_1801_00";
BA_ "GenSigStartValue" SG_ 1410 TransmissionType_1800_02 1;
BA_ "GenSigStartValue" SG_ 1410 COB_ID_1800_01 662;
BA_ "GenSigStartValue" SG_ 1410 Highest_sub_index_supported_1800 5;
BA_ "SystemSignalLongSymbol" SG_ 1410 Highest_sub_index_supported_1800 "Highest_sub_index_supported_1800_00";
BA_ "GenSigStartValue" SG_ 1410 GENERATED_1602_03 1632239888;
BA_ "GenSigStartValue" SG_ 1410 GENERATED_1602_02 1628636424;
BA_ "GenSigStartValue" SG_ 1410 GENERATED_1602_01 1628636168;
BA_ "GenSigStartValue" SG_ 1410 NrOfMappedObjects_1602_00 3;
BA_ "GenSigStartValue" SG_ 1410 PTO_Switch_1601_01 16;
BA_ "GenSigStartValue" SG_ 1410 mappedObj5_1600_05 1631715600;
BA_ "GenSigStartValue" SG_ 1410 mappedObj4_1600_04 1631584528;
BA_ "GenSigStartValue" SG_ 1410 mappedObj3_1600_03 1631518984;
BA_ "GenSigStartValue" SG_ 1410 mappedObj2_1600_02 1631453448;
BA_ "GenSigStartValue" SG_ 1410 mappedObj1_1600_01 1630929160;
BA_ "GenSigStartValue" SG_ 1410 NrOfMappedObjects_1600_00 5;
BA_ "GenSigStartValue" SG_ 1410 TransmissionType_1402_02 255;
BA_ "GenSigStartValue" SG_ 1410 COB_ID_1402_01 1320;
BA_ "GenSigStartValue" SG_ 1410 Highest_sub_index_supported_1402 2;
BA_ "SystemSignalLongSymbol" SG_ 1410 Highest_sub_index_supported_1402 "Highest_sub_index_supported_1402_00";
BA_ "GenSigStartValue" SG_ 1410 TransmissionType_1401_02 255;
BA_ "GenSigStartValue" SG_ 1410 COB_ID_1401_01 2147484298;
BA_ "GenSigStartValue" SG_ 1410 Highest_sub_index_supported_1401 2;
BA_ "SystemSignalLongSymbol" SG_ 1410 Highest_sub_index_supported_1401 "Highest_sub_index_supported_1401_00";
BA_ "GenSigStartValue" SG_ 1410 TransmissionType_1400_02 255;
BA_ "GenSigStartValue" SG_ 1410 COB_ID_1400_01 2147484801;
BA_ "GenSigStartValue" SG_ 1410 Highest_sub_index_supported_1400 2;
BA_ "SystemSignalLongSymbol" SG_ 1410 Highest_sub_index_supported_1400 "Highest_sub_index_supported_1400_00";
BA_ "GenSigStartValue" SG_ 1410 Vendor_Id_1018_01 5;
BA_ "GenSigStartValue" SG_ 1410 NrOfElements_1018_00 1;
BA_ "GenSigStartValue" SG_ 1410 Sync_Window_Length_1007 100;
BA_ "GenSigStartValue" SG_ 1410 Communication_Cycle_Period_1006 200000;
BA_ "GenSigStartValue" SG_ 1410 COB_ID_SYNC_1005 2147483776;
BA_ "GenSigStartValue" SG_ 1410 Device_Type_1000 413;
BA_ "GenSigStartValue" SG_ 1410 Index 4096;
BA_ "SystemSignalLongSymbol" SG_ 1538 requested_engine_speed_mini_0000 "requested_engine_speed_minimum_value_range_614A_03";
BA_ "GenSigStartValue" SG_ 1538 requested_engine_speed_maxi_0000 64255;
BA_ "SystemSignalLongSymbol" SG_ 1538 requested_engine_speed_maxi_0000 "requested_engine_speed_maximum_value_range_614A_02";
BA_ "SystemSignalLongSymbol" SG_ 1538 requested_engine_speed_valu_0000 "requested_engine_speed_value_614A_01";
BA_ "GenSigStartValue" SG_ 1538 requested_engine_speed_numb_0000 3;
BA_ "SystemSignalLongSymbol" SG_ 1538 requested_engine_speed_numb_0000 "requested_engine_speed_number_of_entries_614A_00";
BA_ "SystemSignalLongSymbol" SG_ 1538 requested_engine_speed_lowe_0003 "requested_engine_speed_lower_limit_minimum_value_range_6142_03";
BA_ "GenSigStartValue" SG_ 1538 requested_engine_speed_lowe_0004 64255;
BA_ "SystemSignalLongSymbol" SG_ 1538 requested_engine_speed_lowe_0004 "requested_engine_speed_lower_limit_maximum_value_range_6142_02";
BA_ "GenSigStartValue" SG_ 1538 requested_engine_speed_lowe_0005 65535;
BA_ "SystemSignalLongSymbol" SG_ 1538 requested_engine_speed_lowe_0005 "requested_engine_speed_lower_limit_value_6142_01";
BA_ "GenSigStartValue" SG_ 1538 requested_engine_speed_lowe_0006 3;
BA_ "SystemSignalLongSymbol" SG_ 1538 requested_engine_speed_lowe_0006 "requested_engine_speed_lower_limit_number_of_entries_6142_00";
BA_ "SystemSignalLongSymbol" SG_ 1538 requested_engine_speed_uppe_0003 "requested_engine_speed_upper_limit_minimum_value_range_6140_03";
BA_ "GenSigStartValue" SG_ 1538 requested_engine_speed_uppe_0004 64255;
BA_ "SystemSignalLongSymbol" SG_ 1538 requested_engine_speed_uppe_0004 "requested_engine_speed_upper_limit_maximum_value_range_6140_02";
BA_ "GenSigStartValue" SG_ 1538 requested_engine_speed_uppe_0005 65535;
BA_ "SystemSignalLongSymbol" SG_ 1538 requested_engine_speed_uppe_0005 "requested_engine_speed_upper_limit_value_6140_01";
BA_ "GenSigStartValue" SG_ 1538 requested_engine_speed_uppe_0006 3;
BA_ "SystemSignalLongSymbol" SG_ 1538 requested_engine_speed_uppe_0006 "requested_engine_speed_upper_limit_number_of_entries_6140_00";
BA_ "GenSigStartValue" SG_ 1538 engine_stop_switch_Bit_1_613F_01 1;
BA_ "GenSigStartValue" SG_ 1538 engine_stop_switch_Number_o_0000 1;
BA_ "SystemSignalLongSymbol" SG_ 1538 engine_stop_switch_Number_o_0000 "engine_stop_switch_Number_of_entries_613F_00";
BA_ "GenSigStartValue" SG_ 1538 engine_start_switch_Bit_1_6_0000 1;
BA_ "SystemSignalLongSymbol" SG_ 1538 engine_start_switch_Bit_1_6_0000 "engine_start_switch_Bit_1_613E_01";
BA_ "GenSigStartValue" SG_ 1538 engine_start_switch_Number__0000 1;
BA_ "SystemSignalLongSymbol" SG_ 1538 engine_start_switch_Number__0000 "engine_start_switch_Number_of_entries_613E_00";
BA_ "SystemSignalLongSymbol" SG_ 1538 first_clutch_dependent_PTO__0001 "first_clutch_dependent_PTO_switch_Bit_1_6136_01";
BA_ "GenSigStartValue" SG_ 1538 first_clutch_dependent_PTO__0002 1;
BA_ "SystemSignalLongSymbol" SG_ 1538 first_clutch_dependent_PTO__0002 "first_clutch_dependent_PTO_switch_Number_of_entries_6136_00";
BA_ "SystemSignalLongSymbol" SG_ 1538 first_engine_mounted_PTO_fe_0001 "first_engine_mounted_PTO_feedback_Bit_1_6131_01";
BA_ "GenSigStartValue" SG_ 1538 first_engine_mounted_PTO_fe_0002 1;
BA_ "SystemSignalLongSymbol" SG_ 1538 first_engine_mounted_PTO_fe_0002 "first_engine_mounted_PTO_feedback_Number_of_entries_6131_00";
BA_ "GenSigStartValue" SG_ 1538 PTOSwitch_6113_05 1;
BA_ "SystemSignalLongSymbol" SG_ 1538 engine_speed_minimum_value__0000 "engine_speed_minimum_value_range_6113_03";
BA_ "GenSigStartValue" SG_ 1538 engine_speed_maximum_value__0000 64255;
BA_ "SystemSignalLongSymbol" SG_ 1538 engine_speed_maximum_value__0000 "engine_speed_maximum_value_range_6113_02";
BA_ "GenSigStartValue" SG_ 1538 EngineSpeed_6113_01 65535;
BA_ "GenSigStartValue" SG_ 1538 NrOfObjects_6113_00 5;
BA_ "GenSigStartValue" SG_ 1538 current_gear_minimum_value__0000 4294967171;
BA_ "SystemSignalLongSymbol" SG_ 1538 current_gear_minimum_value__0000 "current_gear_minimum_value_range_610C_03";
BA_ "GenSigStartValue" SG_ 1538 current_gear_maximum_value__0000 125;
BA_ "SystemSignalLongSymbol" SG_ 1538 current_gear_maximum_value__0000 "current_gear_maximum_value_range_610C_02";
BA_ "GenSigStartValue" SG_ 1538 NrOfObjects_610C_00 3;
BA_ "SystemSignalLongSymbol" SG_ 1538 wheel_based_vehicle_speed_m_0000 "wheel_based_vehicle_speed_minimum_value_range_6006_03";
BA_ "GenSigStartValue" SG_ 1538 wheel_based_vehicle_speed_m_0001 64000;
BA_ "SystemSignalLongSymbol" SG_ 1538 wheel_based_vehicle_speed_m_0001 "wheel_based_vehicle_speed_maximum_value_range_6006_02";
BA_ "GenSigStartValue" SG_ 1538 wheel_based_vehicle_speed_v_0000 65535;
BA_ "SystemSignalLongSymbol" SG_ 1538 wheel_based_vehicle_speed_v_0000 "wheel_based_vehicle_speed_value_6006_01";
BA_ "GenSigStartValue" SG_ 1538 wheel_based_vehicle_speed_n_0000 3;
BA_ "SystemSignalLongSymbol" SG_ 1538 wheel_based_vehicle_speed_n_0000 "wheel_based_vehicle_speed_number_of_entries_6006_00";
BA_ "SystemSignalLongSymbol" SG_ 1538 park_brake_demand_value_min_0000 "park_brake_demand_value_minimum_value_range_6000_03";
BA_ "GenSigStartValue" SG_ 1538 park_brake_demand_value_max_0000 250;
BA_ "SystemSignalLongSymbol" SG_ 1538 park_brake_demand_value_max_0000 "park_brake_demand_value_maximum_value_range_6000_02";
BA_ "GenSigStartValue" SG_ 1538 ParkBrakeDemandValue_6000_01 1;
BA_ "GenSigStartValue" SG_ 1538 NrOfObjects_6000_00 3;
BA_ "GenSigStartValue" SG_ 1538 mappedObj5_1A00_05 1628635408;
BA_ "GenSigStartValue" SG_ 1538 mappedObj4_1A00_04 1611006224;
BA_ "GenSigStartValue" SG_ 1538 mappedObj3_1A00_03 1630601480;
BA_ "GenSigStartValue" SG_ 1538 mappedObj2_1A00_02 1610613000;
BA_ "GenSigStartValue" SG_ 1538 mappedObj1_1A00_01 1628176648;
BA_ "GenSigStartValue" SG_ 1538 NrOfMappedObjects_1A00_00 5;
BA_ "GenSigStartValue" SG_ 1538 TransmissionType_1802_02 255;
BA_ "GenSigStartValue" SG_ 1538 COB_ID_1802_01 2147484546;
BA_ "GenSigStartValue" SG_ 1538 Highest_sub_index_supported_0000 5;
BA_ "SystemSignalLongSymbol" SG_ 1538 Highest_sub_index_supported_0000 "Highest_sub_index_supported_1802_00";
BA_ "GenSigStartValue" SG_ 1538 TransmissionType_1801_02 255;
BA_ "GenSigStartValue" SG_ 1538 COB_ID_1801_01 2147484290;
BA_ "GenSigStartValue" SG_ 1538 Highest_sub_index_supported_0001 5;
BA_ "SystemSignalLongSymbol" SG_ 1538 Highest_sub_index_supported_0001 "Highest_sub_index_supported_1801_00";
BA_ "GenSigStartValue" SG_ 1538 TransmissionType_1800_02 1;
BA_ "GenSigStartValue" SG_ 1538 COB_ID_1800_01 662;
BA_ "GenSigStartValue" SG_ 1538 Highest_sub_index_supported_0002 5;
BA_ "SystemSignalLongSymbol" SG_ 1538 Highest_sub_index_supported_0002 "Highest_sub_index_supported_1800_00";
BA_ "GenSigStartValue" SG_ 1538 GENERATED_1602_03 1632239888;
BA_ "GenSigStartValue" SG_ 1538 GENERATED_1602_02 1628636424;
BA_ "GenSigStartValue" SG_ 1538 GENERATED_1602_01 1628636168;
BA_ "GenSigStartValue" SG_ 1538 NrOfMappedObjects_1602_00 3;
BA_ "GenSigStartValue" SG_ 1538 PTO_Switch_1601_01 16;
BA_ "GenSigStartValue" SG_ 1538 mappedObj5_1600_05 1631715600;
BA_ "GenSigStartValue" SG_ 1538 mappedObj4_1600_04 1631584528;
BA_ "GenSigStartValue" SG_ 1538 mappedObj3_1600_03 1631518984;
BA_ "GenSigStartValue" SG_ 1538 mappedObj2_1600_02 1631453448;
BA_ "GenSigStartValue" SG_ 1538 mappedObj1_1600_01 1630929160;
BA_ "GenSigStartValue" SG_ 1538 NrOfMappedObjects_1600_00 5;
BA_ "GenSigStartValue" SG_ 1538 TransmissionType_1402_02 255;
BA_ "GenSigStartValue" SG_ 1538 COB_ID_1402_01 1320;
BA_ "GenSigStartValue" SG_ 1538 Highest_sub_index_supported_0003 2;
BA_ "SystemSignalLongSymbol" SG_ 1538 Highest_sub_index_supported_0003 "Highest_sub_index_supported_1402_00";
BA_ "GenSigStartValue" SG_ 1538 TransmissionType_1401_02 255;
BA_ "GenSigStartValue" SG_ 1538 COB_ID_1401_01 2147484298;
BA_ "GenSigStartValue" SG_ 1538 Highest_sub_index_supported_0004 2;
BA_ "SystemSignalLongSymbol" SG_ 1538 Highest_sub_index_supported_0004 "Highest_sub_index_supported_1401_00";
BA_ "GenSigStartValue" SG_ 1538 TransmissionType_1400_02 255;
BA_ "GenSigStartValue" SG_ 1538 COB_ID_1400_01 2147484801;
BA_ "GenSigStartValue" SG_ 1538 Highest_sub_index_supported_0005 2;
BA_ "SystemSignalLongSymbol" SG_ 1538 Highest_sub_index_supported_0005 "Highest_sub_index_supported_1400_00";
BA_ "GenSigStartValue" SG_ 1538 Vendor_Id_1018_01 5;
BA_ "GenSigStartValue" SG_ 1538 NrOfElements_1018_00 1;
BA_ "GenSigStartValue" SG_ 1538 Sync_Window_Length_1007 100;
BA_ "GenSigStartValue" SG_ 1538 Communication_Cycle_Period_1006 200000;
BA_ "GenSigStartValue" SG_ 1538 COB_ID_SYNC_1005 2147483776;
BA_ "GenSigStartValue" SG_ 1538 Device_Type_1000 413;
BA_ "GenSigStartValue" SG_ 1538 Index 4096;
BA_ "GenSigStartValue" SG_ 1409 NrOfObjects_A680_00 10;
BA_ "GenSigStartValue" SG_ 1409 pos_act_val_ladder_A640_01 60;
BA_ "GenSigStartValue" SG_ 1409 NrOfObjects_A640_00 10;
BA_ "GenSigStartValue" SG_ 1409 EngineSpeed_A580_07 65535;
BA_ "GenSigStartValue" SG_ 1409 wheel_based_vehicle_speed_A580_0 65535;
BA_ "SystemSignalLongSymbol" SG_ 1409 wheel_based_vehicle_speed_A580_0 "wheel_based_vehicle_speed_A580_06";
BA_ "GenSigStartValue" SG_ 1409 statusword_support_rear_A580_03 39;
BA_ "GenSigStartValue" SG_ 1409 statusword_support_front_A580_02 39;
BA_ "GenSigStartValue" SG_ 1409 statusword_ladder_A580_01 39;
BA_ "GenSigStartValue" SG_ 1409 NrOfObjects_A580_00 10;
BA_ "GenSigStartValue" SG_ 1409 NrOfObjects_A540_00 10;
BA_ "GenSigStartValue" SG_ 1409 PTO_Switch_A4C0_09 1;
BA_ "GenSigStartValue" SG_ 1409 ParkBrakeDemandValue_A4C0_05 1;
BA_ "GenSigStartValue" SG_ 1409 NrOfObjects_A4C0_00 10;
BA_ "GenSigStartValue" SG_ 1409 NrOfObjects_A480_00 10;
BA_ "GenSigStartValue" SG_ 1409 NrOfObjects_A200_00 10;
BA_ "GenSigStartValue" SG_ 1409 NrOfObjects_A1C0_00 10;
BA_ "GenSigStartValue" SG_ 1409 controlword_sup_rear_A100_03 43;
BA_ "GenSigStartValue" SG_ 1409 controlword_sup_front_A100_02 43;
BA_ "GenSigStartValue" SG_ 1409 controlword_ladder_A100_01 43;
BA_ "GenSigStartValue" SG_ 1409 NrOfObjects_A100_00 10;
BA_ "SystemSignalLongSymbol" SG_ 1409 vl_target_velocity_sup_rear_A0C0 "vl_target_velocity_sup_rear_A0C0_03";
BA_ "SystemSignalLongSymbol" SG_ 1409 vl_target_velocity_sup_front_A0C "vl_target_velocity_sup_front_A0C0_02";
BA_ "SystemSignalLongSymbol" SG_ 1409 vl_target_velocity_ladder_A0C0_0 "vl_target_velocity_ladder_A0C0_01";
BA_ "GenSigStartValue" SG_ 1409 NrOfObjects_A0C0_00 10;
BA_ "GenSigStartValue" SG_ 1409 MasterPTO_Feedback_A040_09 1;
BA_ "GenSigStartValue" SG_ 1409 PTO_Switch_State_A040_04 1;
BA_ "GenSigStartValue" SG_ 1409 SupportLock_A040_02 1;
BA_ "GenSigStartValue" SG_ 1409 NrOfObjects_A040_00 10;
BA_ "GenSigStartValue" SG_ 1409 NrOfObjects_A000_00 10;
BA_ "GenSigStartValue" SG_ 1409 SerialNumber_d_1F88_0D 2;
BA_ "GenSigStartValue" SG_ 1409 SerialNumber_c_1F88_0C 1;
BA_ "GenSigStartValue" SG_ 1409 SerialNumber_b_1F88_0B 1;
BA_ "GenSigStartValue" SG_ 1409 SerialNumber_a_1F88_0A 1;
BA_ "GenSigStartValue" SG_ 1409 NrOfObjects_1F88_00 127;
BA_ "GenSigStartValue" SG_ 1409 VendorIdentification_d_1F85_0D 5;
BA_ "GenSigStartValue" SG_ 1409 VendorIdentification_c_1F85_0C 5;
BA_ "GenSigStartValue" SG_ 1409 VendorIdentification_b_1F85_0B 5;
BA_ "GenSigStartValue" SG_ 1409 VendorIdentification_a_1F85_0A 5;
BA_ "GenSigStartValue" SG_ 1409 NrOfObjects_1F85_00 127;
BA_ "GenSigStartValue" SG_ 1409 Highest_sub_index_supported_1F83 128;
BA_ "SystemSignalLongSymbol" SG_ 1409 Highest_sub_index_supported_1F83 "Highest_sub_index_supported_1F83_00";
BA_ "GenSigStartValue" SG_ 1409 Highest_sub_index_supported_1F82 128;
BA_ "SystemSignalLongSymbol" SG_ 1409 Highest_sub_index_supported_1F82 "Highest_sub_index_supported_1F82_00";
VAL_ 1794 State 127 "PreOperational" 5 "Operational" 4 "Stopped" 0 "Bootup" ;
VAL_ 1410 SubIndex_614A 3 "requested_engine_speed_minimum_value_range" 2 "requested_engine_speed_maximum_value_range" 1 "requested_engine_speed_value" 0 "requested_engine_speed_number_of_entries" ;
VAL_ 1410 SubIndex_6142 3 "requested_engine_speed_lower_limit_minimum_value_range" 2 "requested_engine_speed_lower_limit_maximum_value_range" 1 "requested_engine_speed_lower_limit_value" 0 "requested_engine_speed_lower_limit_number_of_entries" ;
VAL_ 1410 SubIndex_6140 3 "requested_engine_speed_upper_limit_minimum_value_range" 2 "requested_engine_speed_upper_limit_maximum_value_range" 1 "requested_engine_speed_upper_limit_value" 0 "requested_engine_speed_upper_limit_number_of_entries" ;
VAL_ 1410 SubIndex_613F 1 "engine_stop_switch_Bit_1" 0 "engine_stop_switch_Number_of_entries" ;
VAL_ 1410 SubIndex_613E 1 "engine_start_switch_Bit_1" 0 "engine_start_switch_Number_of_entries" ;
VAL_ 1410 SubIndex_6136 1 "first_clutch_dependent_PTO_switch_Bit_1" 0 "first_clutch_dependent_PTO_switch_Number_of_entries" ;
VAL_ 1410 SubIndex_6131 1 "first_engine_mounted_PTO_feedback_Bit_1" 0 "first_engine_mounted_PTO_feedback_Number_of_entries" ;
VAL_ 1410 SubIndex_6113 5 "PTOSwitch" 4 "SupportPositionGateIn" 3 "engine_speed_minimum_value_range" 2 "engine_speed_maximum_value_range" 1 "EngineSpeed" 0 "NrOfObjects" ;
VAL_ 1410 SubIndex_610C 3 "current_gear_minimum_value_range" 2 "current_gear_maximum_value_range" 1 "CurrentGearValue" 0 "NrOfObjects" ;
VAL_ 1410 SubIndex_6006 3 "wheel_based_vehicle_speed_minimum_value_range" 2 "wheel_based_vehicle_speed_maximum_value_range" 1 "wheel_based_vehicle_speed_value" 0 "wheel_based_vehicle_speed_number_of_entries" ;
VAL_ 1410 SubIndex_6000 3 "park_brake_demand_value_minimum_value_range" 2 "park_brake_demand_value_maximum_value_range" 1 "ParkBrakeDemandValue" 0 "NrOfObjects" ;
VAL_ 1410 SubIndex_1A02 0 "NrOfMappedObjects" ;
VAL_ 1410 SubIndex_1A01 0 "NrOfMappedObjects" ;
VAL_ 1410 SubIndex_1A00 5 "mappedObj5" 4 "mappedObj4" 3 "mappedObj3" 2 "mappedObj2" 1 "mappedObj1" 0 "NrOfMappedObjects" ;
VAL_ 1410 SubIndex_1802 5 "EventTimer" 2 "TransmissionType" 1 "COB-ID" 0 "Highest sub-index supported" ;
VAL_ 1410 SubIndex_1801 5 "EventTimer" 2 "TransmissionType" 1 "COB-ID" 0 "Highest sub-index supported" ;
VAL_ 1410 SubIndex_1800 5 "EventTimer" 2 "TransmissionType" 1 "COB-ID" 0 "Highest sub-index supported" ;
VAL_ 1410 SubIndex_1602 3 "GENERATED" 2 "GENERATED" 1 "GENERATED" 0 "NrOfMappedObjects" ;
VAL_ 1410 SubIndex_1601 1 "PTO_Switch" 0 "NrOfMappedObjects" ;
VAL_ 1410 SubIndex_1600 5 "mappedObj5" 4 "mappedObj4" 3 "mappedObj3" 2 "mappedObj2" 1 "mappedObj1" 0 "NrOfMappedObjects" ;
VAL_ 1410 SubIndex_1402 2 "TransmissionType" 1 "COB-ID" 0 "Highest sub-index supported" ;
VAL_ 1410 SubIndex_1401 2 "TransmissionType" 1 "COB-ID" 0 "Highest sub-index supported" ;
VAL_ 1410 SubIndex_1400 2 "TransmissionType" 1 "COB-ID" 0 "Highest sub-index supported" ;
VAL_ 1410 SubIndex_1018 1 "Vendor Id" 0 "NrOfElements" ;
VAL_ 1410 SubIndex_1007 0 "Sync_Window Length" ;
VAL_ 1410 SubIndex_1006 0 "Communication Cycle Period" ;
VAL_ 1410 SubIndex_1005 0 "COB-ID SYNC" ;
VAL_ 1410 SubIndex_1001 0 "ErrorRegister" ;
VAL_ 1410 SubIndex_1000 0 "Device Type" ;
VAL_ 1410 Index 24906 "ReqEngSpeed" 24898 "ReqEngSpeedLowerLimit" 24896 "ReqEngSpeedUpperLimit" 24895 "engine_stop_switch" 24894 "EngineStartSwitch" 24886 "ClutchPTOSwitch" 24881 "PTOFeedBack" 24851 "EngineSpeed" 24844 "CurrentGear" 24582 "wheel_based_vehicle_speed" 24576 "ParkBrakeDemandValue" 6658 "TxPDOMapping" 6657 "TxPDOMapping" 6656 "TxPDOMapping" 6146 "TxPDOComPar" 6145 "TxPDOComPar" 6144 "TxPDOComPar" 5634 "RxPDOMapping" 5633 "RxPDOMapping" 5632 "RxPDOMapping" 5122 "RxPDOComPar" 5121 "RxPDOComPar" 5120 "RxPDOComPar" 4120 "Identity Object" 4103 "Sync_Window Length" 4102 "Communication Cycle Period" 4101 "COB-ID SYNC" 4097 "ErrorRegister" 4096 "Device Type" ;
VAL_ 1410 TransferType 1 "Expedited transfer" 0 "Normal transfer" ;
VAL_ 1410 SizeIndicator 1 "Size is indicated" 0 "Size is not indicated" ;
VAL_ 1410 SCS 2 "Upload" 1 "Download" ;
VAL_ 1538 SubIndex_614A 3 "requested_engine_speed_minimum_value_range" 2 "requested_engine_speed_maximum_value_range" 1 "requested_engine_speed_value" 0 "requested_engine_speed_number_of_entries" ;
VAL_ 1538 SubIndex_6142 3 "requested_engine_speed_lower_limit_minimum_value_range" 2 "requested_engine_speed_lower_limit_maximum_value_range" 1 "requested_engine_speed_lower_limit_value" 0 "requested_engine_speed_lower_limit_number_of_entries" ;
VAL_ 1538 SubIndex_6140 3 "requested_engine_speed_upper_limit_minimum_value_range" 2 "requested_engine_speed_upper_limit_maximum_value_range" 1 "requested_engine_speed_upper_limit_value" 0 "requested_engine_speed_upper_limit_number_of_entries" ;
VAL_ 1538 SubIndex_613F 1 "engine_stop_switch_Bit_1" 0 "engine_stop_switch_Number_of_entries" ;
VAL_ 1538 SubIndex_613E 1 "engine_start_switch_Bit_1" 0 "engine_start_switch_Number_of_entries" ;
VAL_ 1538 SubIndex_6136 1 "first_clutch_dependent_PTO_switch_Bit_1" 0 "first_clutch_dependent_PTO_switch_Number_of_entries" ;
VAL_ 1538 SubIndex_6131 1 "first_engine_mounted_PTO_feedback_Bit_1" 0 "first_engine_mounted_PTO_feedback_Number_of_entries" ;
VAL_ 1538 SubIndex_6113 5 "PTOSwitch" 4 "SupportPositionGateIn" 3 "engine_speed_minimum_value_range" 2 "engine_speed_maximum_value_range" 1 "EngineSpeed" 0 "NrOfObjects" ;
VAL_ 1538 SubIndex_610C 3 "current_gear_minimum_value_range" 2 "current_gear_maximum_value_range" 1 "CurrentGearValue" 0 "NrOfObjects" ;
VAL_ 1538 SubIndex_6006 3 "wheel_based_vehicle_speed_minimum_value_range" 2 "wheel_based_vehicle_speed_maximum_value_range" 1 "wheel_based_vehicle_speed_value" 0 "wheel_based_vehicle_speed_number_of_entries" ;
VAL_ 1538 SubIndex_6000 3 "park_brake_demand_value_minimum_value_range" 2 "park_brake_demand_value_maximum_value_range" 1 "ParkBrakeDemandValue" 0 "NrOfObjects" ;
VAL_ 1538 SubIndex_1A02 0 "NrOfMappedObjects" ;
VAL_ 1538 SubIndex_1A01 0 "NrOfMappedObjects" ;
VAL_ 1538 SubIndex_1A00 5 "mappedObj5" 4 "mappedObj4" 3 "mappedObj3" 2 "mappedObj2" 1 "mappedObj1" 0 "NrOfMappedObjects" ;
VAL_ 1538 SubIndex_1802 5 "EventTimer" 2 "TransmissionType" 1 "COB-ID" 0 "Highest sub-index supported" ;
VAL_ 1538 SubIndex_1801 5 "EventTimer" 2 "TransmissionType" 1 "COB-ID" 0 "Highest sub-index supported" ;
VAL_ 1538 SubIndex_1800 5 "EventTimer" 2 "TransmissionType" 1 "COB-ID" 0 "Highest sub-index supported" ;
VAL_ 1538 SubIndex_1602 3 "GENERATED" 2 "GENERATED" 1 "GENERATED" 0 "NrOfMappedObjects" ;
VAL_ 1538 SubIndex_1601 1 "PTO_Switch" 0 "NrOfMappedObjects" ;
VAL_ 1538 SubIndex_1600 5 "mappedObj5" 4 "mappedObj4" 3 "mappedObj3" 2 "mappedObj2" 1 "mappedObj1" 0 "NrOfMappedObjects" ;
VAL_ 1538 SubIndex_1402 2 "TransmissionType" 1 "COB-ID" 0 "Highest sub-index supported" ;
VAL_ 1538 SubIndex_1401 2 "TransmissionType" 1 "COB-ID" 0 "Highest sub-index supported" ;
VAL_ 1538 SubIndex_1400 2 "TransmissionType" 1 "COB-ID" 0 "Highest sub-index supported" ;
VAL_ 1538 SubIndex_1018 1 "Vendor Id" 0 "NrOfElements" ;
VAL_ 1538 SubIndex_1007 0 "Sync_Window Length" ;
VAL_ 1538 SubIndex_1006 0 "Communication Cycle Period" ;
VAL_ 1538 SubIndex_1005 0 "COB-ID SYNC" ;
VAL_ 1538 SubIndex_1001 0 "ErrorRegister" ;
VAL_ 1538 SubIndex_1000 0 "Device Type" ;
VAL_ 1538 Index 24906 "ReqEngSpeed" 24898 "ReqEngSpeedLowerLimit" 24896 "ReqEngSpeedUpperLimit" 24895 "engine_stop_switch" 24894 "EngineStartSwitch" 24886 "ClutchPTOSwitch" 24881 "PTOFeedBack" 24851 "EngineSpeed" 24844 "CurrentGear" 24582 "wheel_based_vehicle_speed" 24576 "ParkBrakeDemandValue" 6658 "TxPDOMapping" 6657 "TxPDOMapping" 6656 "TxPDOMapping" 6146 "TxPDOComPar" 6145 "TxPDOComPar" 6144 "TxPDOComPar" 5634 "RxPDOMapping" 5633 "RxPDOMapping" 5632 "RxPDOMapping" 5122 "RxPDOComPar" 5121 "RxPDOComPar" 5120 "RxPDOComPar" 4120 "Identity Object" 4103 "Sync_Window Length" 4102 "Communication Cycle Period" 4101 "COB-ID SYNC" 4097 "ErrorRegister" 4096 "Device Type" ;
VAL_ 1538 TransferType 1 "Expedited transfer" 0 "Normal transfer" ;
VAL_ 1538 SizeIndicator 1 "Size is indicated" 0 "Size is not indicated" ;
VAL_ 1538 CCS 2 "Upload" 1 "Download" ;
VAL_ 130 ErrorCode 65530 "(DS-413) Time out of IVN ECU with Source Address 250" 65529 "(DS-413) Time out of IVN ECU with Source Address 249" 65528 "(DS-413) Time out of IVN ECU with Source Address 248" 65527 "(DS-413) Time out of IVN ECU with Source Address 247" 65526 "(DS-413) Time out of IVN ECU with Source Address 246" 65525 "(DS-413) Time out of IVN ECU with Source Address 245" 65524 "(DS-413) Time out of IVN ECU with Source Address 244" 65523 "(DS-413) Time out of IVN ECU with Source Address 243" 65522 "(DS-413) Time out of IVN ECU with Source Address 242" 65521 "(DS-413) Time out of IVN ECU with Source Address 241" 65520 "(DS-413) Time out of IVN ECU with Source Address 240" 65519 "(DS-413) Time out of IVN ECU with Source Address 239" 65518 "(DS-413) Time out of IVN ECU with Source Address 238" 65517 "(DS-413) Time out of IVN ECU with Source Address 237" 65516 "(DS-413) Time out of IVN ECU with Source Address 236" 65515 "(DS-413) Time out of IVN ECU with Source Address 235" 65514 "(DS-413) Time out of IVN ECU with Source Address 234" 65513 "(DS-413) Time out of IVN ECU with Source Address 233" 65512 "(DS-413) Time out of IVN ECU with Source Address 232" 65511 "(DS-413) Time out of IVN ECU with Source Address 231" 65510 "(DS-413) Time out of IVN ECU with Source Address 230" 65509 "(DS-413) Time out of IVN ECU with Source Address 229" 65508 "(DS-413) Time out of IVN ECU with Source Address 228" 65507 "(DS-413) Time out of IVN ECU with Source Address 227" 65506 "(DS-413) Time out of IVN ECU with Source Address 226" 65505 "(DS-413) Time out of IVN ECU with Source Address 225" 65504 "(DS-413) Time out of IVN ECU with Source Address 224" 65503 "(DS-413) Time out of IVN ECU with Source Address 223" 65502 "(DS-413) Time out of IVN ECU with Source Address 222" 65501 "(DS-413) Time out of IVN ECU with Source Address 221" 65500 "(DS-413) Time out of IVN ECU with Source Address 220" 65499 "(DS-413) Time out of IVN ECU with Source Address 219" 65498 "(DS-413) Time out of IVN ECU with Source Address 218" 65497 "(DS-413) Time out of IVN ECU with Source Address 217" 65496 "(DS-413) Time out of IVN ECU with Source Address 216" 65495 "(DS-413) Time out of IVN ECU with Source Address 215" 65494 "(DS-413) Time out of IVN ECU with Source Address 214" 65493 "(DS-413) Time out of IVN ECU with Source Address 213" 65492 "(DS-413) Time out of IVN ECU with Source Address 212" 65491 "(DS-413) Time out of IVN ECU with Source Address 211" 65490 "(DS-413) Time out of IVN ECU with Source Address 210" 65489 "(DS-413) Time out of IVN ECU with Source Address 209" 65488 "(DS-413) Time out of IVN ECU with Source Address 208" 65487 "(DS-413) Time out of IVN ECU with Source Address 207" 65486 "(DS-413) Time out of IVN ECU with Source Address 206" 65485 "(DS-413) Time out of IVN ECU with Source Address 205" 65484 "(DS-413) Time out of IVN ECU with Source Address 204" 65483 "(DS-413) Time out of IVN ECU with Source Address 203" 65482 "(DS-413) Time out of IVN ECU with Source Address 202" 65481 "(DS-413) Time out of IVN ECU with Source Address 201" 65480 "(DS-413) Time out of IVN ECU with Source Address 200" 65479 "(DS-413) Time out of IVN ECU with Source Address 199" 65478 "(DS-413) Time out of IVN ECU with Source Address 198" 65477 "(DS-413) Time out of IVN ECU with Source Address 197" 65476 "(DS-413) Time out of IVN ECU with Source Address 196" 65475 "(DS-413) Time out of IVN ECU with Source Address 195" 65474 "(DS-413) Time out of IVN ECU with Source Address 194" 65473 "(DS-413) Time out of IVN ECU with Source Address 193" 65472 "(DS-413) Time out of IVN ECU with Source Address 192" 65471 "(DS-413) Time out of IVN ECU with Source Address 191" 65470 "(DS-413) Time out of IVN ECU with Source Address 190" 65469 "(DS-413) Time out of IVN ECU with Source Address 189" 65468 "(DS-413) Time out of IVN ECU with Source Address 188" 65467 "(DS-413) Time out of IVN ECU with Source Address 187" 65466 "(DS-413) Time out of IVN ECU with Source Address 186" 65465 "(DS-413) Time out of IVN ECU with Source Address 185" 65464 "(DS-413) Time out of IVN ECU with Source Address 184" 65463 "(DS-413) Time out of IVN ECU with Source Address 183" 65462 "(DS-413) Time out of IVN ECU with Source Address 182" 65461 "(DS-413) Time out of IVN ECU with Source Address 181" 65460 "(DS-413) Time out of IVN ECU with Source Address 180" 65459 "(DS-413) Time out of IVN ECU with Source Address 179" 65458 "(DS-413) Time out of IVN ECU with Source Address 178" 65457 "(DS-413) Time out of IVN ECU with Source Address 177" 65456 "(DS-413) Time out of IVN ECU with Source Address 176" 65455 "(DS-413) Time out of IVN ECU with Source Address 175" 65454 "(DS-413) Time out of IVN ECU with Source Address 174" 65453 "(DS-413) Time out of IVN ECU with Source Address 173" 65452 "(DS-413) Time out of IVN ECU with Source Address 172" 65451 "(DS-413) Time out of IVN ECU with Source Address 171" 65450 "(DS-413) Time out of IVN ECU with Source Address 170" 65449 "(DS-413) Time out of IVN ECU with Source Address 169" 65448 "(DS-413) Time out of IVN ECU with Source Address 168" 65447 "(DS-413) Time out of IVN ECU with Source Address 167" 65446 "(DS-413) Time out of IVN ECU with Source Address 166" 65445 "(DS-413) Time out of IVN ECU with Source Address 165" 65444 "(DS-413) Time out of IVN ECU with Source Address 164" 65443 "(DS-413) Time out of IVN ECU with Source Address 163" 65442 "(DS-413) Time out of IVN ECU with Source Address 162" 65441 "(DS-413) Time out of IVN ECU with Source Address 161" 65440 "(DS-413) Time out of IVN ECU with Source Address 160" 65439 "(DS-413) Time out of IVN ECU with Source Address 159" 65438 "(DS-413) Time out of IVN ECU with Source Address 158" 65437 "(DS-413) Time out of IVN ECU with Source Address 157" 65436 "(DS-413) Time out of IVN ECU with Source Address 156" 65435 "(DS-413) Time out of IVN ECU with Source Address 155" 65434 "(DS-413) Time out of IVN ECU with Source Address 154" 65433 "(DS-413) Time out of IVN ECU with Source Address 153" 65432 "(DS-413) Time out of IVN ECU with Source Address 152" 65431 "(DS-413) Time out of IVN ECU with Source Address 151" 65430 "(DS-413) Time out of IVN ECU with Source Address 150" 65429 "(DS-413) Time out of IVN ECU with Source Address 149" 65428 "(DS-413) Time out of IVN ECU with Source Address 148" 65427 "(DS-413) Time out of IVN ECU with Source Address 147" 65426 "(DS-413) Time out of IVN ECU with Source Address 146" 65425 "(DS-413) Time out of IVN ECU with Source Address 145" 65424 "(DS-413) Time out of IVN ECU with Source Address 144" 65423 "(DS-413) Time out of IVN ECU with Source Address 143" 65422 "(DS-413) Time out of IVN ECU with Source Address 142" 65421 "(DS-413) Time out of IVN ECU with Source Address 141" 65420 "(DS-413) Time out of IVN ECU with Source Address 140" 65419 "(DS-413) Time out of IVN ECU with Source Address 139" 65418 "(DS-413) Time out of IVN ECU with Source Address 138" 65417 "(DS-413) Time out of IVN ECU with Source Address 137" 65416 "(DS-413) Time out of IVN ECU with Source Address 136" 65415 "(DS-413) Time out of IVN ECU with Source Address 135" 65414 "(DS-413) Time out of IVN ECU with Source Address 134" 65413 "(DS-413) Time out of IVN ECU with Source Address 133" 65412 "(DS-413) Time out of IVN ECU with Source Address 132" 65411 "(DS-413) Time out of IVN ECU with Source Address 131" 65410 "(DS-413) Time out of IVN ECU with Source Address 130" 65409 "(DS-413) Time out of IVN ECU with Source Address 129" 65408 "(DS-413) Time out of IVN ECU with Source Address 128" 65407 "(DS-413) Time out of IVN ECU with Source Address 127" 65406 "(DS-413) Time out of IVN ECU with Source Address 126" 65405 "(DS-413) Time out of IVN ECU with Source Address 125" 65404 "(DS-413) Time out of IVN ECU with Source Address 124" 65403 "(DS-413) Time out of IVN ECU with Source Address 123" 65402 "(DS-413) Time out of IVN ECU with Source Address 122" 65401 "(DS-413) Time out of IVN ECU with Source Address 121" 65400 "(DS-413) Time out of IVN ECU with Source Address 120" 65399 "(DS-413) Time out of IVN ECU with Source Address 119" 65398 "(DS-413) Time out of IVN ECU with Source Address 118" 65397 "(DS-413) Time out of IVN ECU with Source Address 117" 65396 "(DS-413) Time out of IVN ECU with Source Address 116" 65395 "(DS-413) Time out of IVN ECU with Source Address 115" 65394 "(DS-413) Time out of IVN ECU with Source Address 114" 65393 "(DS-413) Time out of IVN ECU with Source Address 113" 65392 "(DS-413) Time out of IVN ECU with Source Address 112" 65391 "(DS-413) Time out of IVN ECU with Source Address 111" 65390 "(DS-413) Time out of IVN ECU with Source Address 110" 65389 "(DS-413) Time out of IVN ECU with Source Address 109" 65388 "(DS-413) Time out of IVN ECU with Source Address 108" 65387 "(DS-413) Time out of IVN ECU with Source Address 107" 65386 "(DS-413) Time out of IVN ECU with Source Address 106" 65385 "(DS-413) Time out of IVN ECU with Source Address 105" 65384 "(DS-413) Time out of IVN ECU with Source Address 104" 65383 "(DS-413) Time out of IVN ECU with Source Address 103" 65382 "(DS-413) Time out of IVN ECU with Source Address 102" 65381 "(DS-413) Time out of IVN ECU with Source Address 101" 65380 "(DS-413) Time out of IVN ECU with Source Address 100" 65379 "(DS-413) Time out of IVN ECU with Source Address 99" 65378 "(DS-413) Time out of IVN ECU with Source Address 98" 65377 "(DS-413) Time out of IVN ECU with Source Address 97" 65376 "(DS-413) Time out of IVN ECU with Source Address 96" 65375 "(DS-413) Time out of IVN ECU with Source Address 95" 65374 "(DS-413) Time out of IVN ECU with Source Address 94" 65373 "(DS-413) Time out of IVN ECU with Source Address 93" 65372 "(DS-413) Time out of IVN ECU with Source Address 92" 65371 "(DS-413) Time out of IVN ECU with Source Address 91" 65370 "(DS-413) Time out of IVN ECU with Source Address 90" 65369 "(DS-413) Time out of IVN ECU with Source Address 89" 65368 "(DS-413) Time out of IVN ECU with Source Address 88" 65367 "(DS-413) Time out of IVN ECU with Source Address 87" 65366 "(DS-413) Time out of IVN ECU with Source Address 86" 65365 "(DS-413) Time out of IVN ECU with Source Address 85" 65364 "(DS-413) Time out of IVN ECU with Source Address 84" 65363 "(DS-413) Time out of IVN ECU with Source Address 83" 65362 "(DS-413) Time out of IVN ECU with Source Address 82" 65361 "(DS-413) Time out of IVN ECU with Source Address 81" 65360 "(DS-413) Time out of IVN ECU with Source Address 80" 65359 "(DS-413) Time out of IVN ECU with Source Address 79" 65358 "(DS-413) Time out of IVN ECU with Source Address 78" 65357 "(DS-413) Time out of IVN ECU with Source Address 77" 65356 "(DS-413) Time out of IVN ECU with Source Address 76" 65355 "(DS-413) Time out of IVN ECU with Source Address 75" 65354 "(DS-413) Time out of IVN ECU with Source Address 74" 65353 "(DS-413) Time out of IVN ECU with Source Address 73" 65352 "(DS-413) Time out of IVN ECU with Source Address 72" 65351 "(DS-413) Time out of IVN ECU with Source Address 71" 65350 "(DS-413) Time out of IVN ECU with Source Address 70" 65349 "(DS-413) Time out of IVN ECU with Source Address 69" 65348 "(DS-413) Time out of IVN ECU with Source Address 68" 65347 "(DS-413) Time out of IVN ECU with Source Address 67" 65346 "(DS-413) Time out of IVN ECU with Source Address 66" 65345 "(DS-413) Time out of IVN ECU with Source Address 65" 65344 "(DS-413) Time out of IVN ECU with Source Address 64" 65343 "(DS-413) Time out of IVN ECU with Source Address 63" 65342 "(DS-413) Time out of IVN ECU with Source Address 62" 65341 "(DS-413) Time out of IVN ECU with Source Address 61" 65340 "(DS-413) Time out of IVN ECU with Source Address 60" 65339 "(DS-413) Time out of IVN ECU with Source Address 59" 65338 "(DS-413) Time out of IVN ECU with Source Address 58" 65337 "(DS-413) Time out of IVN ECU with Source Address 57" 65336 "(DS-413) Time out of IVN ECU with Source Address 56" 65335 "(DS-413) Time out of IVN ECU with Source Address 55" 65334 "(DS-413) Time out of IVN ECU with Source Address 54" 65333 "(DS-413) Time out of IVN ECU with Source Address 53" 65332 "(DS-413) Time out of IVN ECU with Source Address 52" 65331 "(DS-413) Time out of IVN ECU with Source Address 51" 65330 "(DS-413) Time out of IVN ECU with Source Address 50" 65329 "(DS-413) Time out of IVN ECU with Source Address 49" 65328 "(DS-413) Time out of IVN ECU with Source Address 48" 65327 "(DS-413) Time out of IVN ECU with Source Address 47" 65326 "(DS-413) Time out of IVN ECU with Source Address 46" 65325 "(DS-413) Time out of IVN ECU with Source Address 45" 65324 "(DS-413) Time out of IVN ECU with Source Address 44" 65323 "(DS-413) Time out of IVN ECU with Source Address 43" 65322 "(DS-413) Time out of IVN ECU with Source Address 42" 65321 "(DS-413) Time out of IVN ECU with Source Address 41" 65320 "(DS-413) Time out of IVN ECU with Source Address 40" 65319 "(DS-413) Time out of IVN ECU with Source Address 39" 65318 "(DS-413) Time out of IVN ECU with Source Address 38" 65317 "(DS-413) Time out of IVN ECU with Source Address 37" 65316 "(DS-413) Time out of IVN ECU with Source Address 36" 65315 "(DS-413) Time out of IVN ECU with Source Address 35" 65314 "(DS-413) Time out of IVN ECU with Source Address 34" 65313 "(DS-413) Time out of IVN ECU with Source Address 33" 65312 "(DS-413) Time out of IVN ECU with Source Address 32" 65311 "(DS-413) Time out of IVN ECU with Source Address 31" 65310 "(DS-413) Time out of IVN ECU with Source Address 30" 65309 "(DS-413) Time out of IVN ECU with Source Address 29" 65308 "(DS-413) Time out of IVN ECU with Source Address 28" 65307 "(DS-413) Time out of IVN ECU with Source Address 27" 65306 "(DS-413) Time out of IVN ECU with Source Address 26" 65305 "(DS-413) Time out of IVN ECU with Source Address 25" 65304 "(DS-413) Time out of IVN ECU with Source Address 24" 65303 "(DS-413) Time out of IVN ECU with Source Address 23" 65302 "(DS-413) Time out of IVN ECU with Source Address 22" 65301 "(DS-413) Time out of IVN ECU with Source Address 21" 65300 "(DS-413) Time out of IVN ECU with Source Address 20" 65299 "(DS-413) Time out of IVN ECU with Source Address 19" 65298 "(DS-413) Time out of IVN ECU with Source Address 18" 65297 "(DS-413) Time out of IVN ECU with Source Address 17" 65296 "(DS-413) Time out of IVN ECU with Source Address 16" 65295 "(DS-413) Time out of IVN ECU with Source Address 15" 65294 "(DS-413) Time out of IVN ECU with Source Address 14" 65293 "(DS-413) Time out of IVN ECU with Source Address 13" 65292 "(DS-413) Time out of IVN ECU with Source Address 12" 65291 "(DS-413) Time out of IVN ECU with Source Address 11" 65290 "(DS-413) Time out of IVN ECU with Source Address 10" 65289 "(DS-413) Time out of IVN ECU with Source Address 9" 65288 "(DS-413) Time out of IVN ECU with Source Address 8" 65287 "(DS-413) Time out of IVN ECU with Source Address 7" 65286 "(DS-413) Time out of IVN ECU with Source Address 6" 65285 "(DS-413) Time out of IVN ECU with Source Address 5" 65284 "(DS-413) Time out of IVN ECU with Source Address 4" 65283 "(DS-413) Time out of IVN ECU with Source Address 3" 65282 "(DS-413) Time out of IVN ECU with Source Address 2" 65281 "(DS-413) Time out of IVN ECU with Source Address 1" 33360 "RPDO timeout" 33344 "Unexpected SYNC data length" 33328 "DAM MPDO not processed, destination object not available" 33312 "PDO length exceeded" 33296 "PDO not processed due to length error" 33104 "Transmit COB-ID collision" 33088 "Recovered from bus off state" 33072 "Life guard error or heartbeat error" 33056 "CAN in error passive mode" 33040 "CAN overrun (objects lost)" ;
VAL_ 1793 State 127 "PreOperational" 5 "Operational" 4 "Stopped" 0 "Bootup" ;
VAL_ 1409 SubIndex_A680 10 "NetVarUInt32Out10" 9 "NetVarUInt32Out9" 8 "NetVarUInt32Out8" 7 "NetVarUInt32Out7" 6 "NetVarUInt32Out6" 5 "NetVarUInt32Out5" 4 "NetVarUInt32Out4" 3 "NetVarUInt32Out3" 2 "NetVarUInt32Out2" 1 "NetVarUInt32Out1" 0 "NrOfObjects" ;
VAL_ 1409 SubIndex_A640 10 "NetVarInt32Out10" 9 "NetVarInt32Out9" 8 "NetVarInt32Out8" 7 "NetVarInt32Out7" 6 "NetVarInt32Out6" 5 "NetVarInt32Out5" 4 "NetVarInt32Out4" 3 "pos_act_val_sup_rear" 2 "pos_act_val_sup_front" 1 "pos_act_val_ladder" 0 "NrOfObjects" ;
VAL_ 1409 SubIndex_A580 10 "NetVarUInt16Out10" 9 "NetVarUInt16Out9" 8 "NetVarUInt16Out8" 7 "EngineSpeed" 6 "wheel_based_vehicle_speed" 5 "NetVarUInt16Out5" 4 "NetVarUInt16Out4" 3 "statusword_support_rear" 2 "statusword_support_front" 1 "statusword_ladder" 0 "NrOfObjects" ;
VAL_ 1409 SubIndex_A540 10 "NetVarInt16Out10" 9 "NetVarInt16Out9" 8 "NetVarInt16Out8" 7 "NetVarInt16Out7" 6 "NetVarInt16Out6" 5 "NetVarInt16Out5" 4 "NetVarInt16Out4" 3 "NetVarInt16Out3" 2 "NetVarInt16Out2" 1 "velocity_demand_ladder" 0 "NrOfObjects" ;
VAL_ 1409 SubIndex_A4C0 10 "PTO_gear_Feedback" 9 "PTO_Switch" 8 "NetVarUInt8Out8" 7 "NetVarUInt8Out7" 6 "EngMountedPTO" 5 "ParkBrakeDemandValue" 4 "Support_Down" 3 "Support_Up" 2 "Ladder_Down" 1 "Ladder_Up" 0 "NrOfObjects" ;
VAL_ 1409 SubIndex_A480 10 "NetVarInt8Out10" 9 "NetVarInt8Out9" 8 "NetVarInt8Out8" 7 "NetVarInt8Out7" 6 "CurrentGearValue" 5 "NetVarInt8Out5" 4 "NetVarInt8Out4" 3 "NetVarInt8Out3" 2 "NetVarInt8Out2" 1 "NetVarInt8Out1" 0 "NrOfObjects" ;
VAL_ 1409 SubIndex_A200 10 "NetVarUInt32In10" 9 "NetVarUInt32In9" 8 "NetVarUInt32In8" 7 "NetVarUInt32In7" 6 "NetVarUInt32In6" 5 "NetVarUInt32In5" 4 "NetVarUInt32In4" 3 "NetVarUInt32In3" 2 "NetVarUInt32In2" 1 "NetVarUInt32In1" 0 "NrOfObjects" ;
VAL_ 1409 SubIndex_A1C0 10 "NetVarInt32In10" 9 "NetVarInt32In9" 8 "NetVarInt32In8" 7 "NetVarInt32In7" 6 "NetVarInt32In6" 5 "NetVarInt32In5" 4 "NetVarInt32In4" 3 "NetVarInt32In3" 2 "NetVarInt32In2" 1 "NetVarInt32In1" 0 "NrOfObjects" ;
VAL_ 1409 SubIndex_A100 10 "NetVarUInt16In10" 9 "NetVarUInt16In9" 8 "NetVarUInt16In8" 7 "NetVarUInt16In7" 6 "NetVarUInt16In6" 5 "NetVarUInt16In5" 4 "NetVarUInt16In4" 3 "controlword_sup_rear" 2 "controlword_sup_front" 1 "controlword_ladder" 0 "NrOfObjects" ;
VAL_ 1409 SubIndex_A0C0 10 "NetVarInt16In10" 9 "NetVarInt16In9" 8 "NetVarInt16In8" 7 "NetVarInt16In7" 6 "NetVarInt16In6" 5 "NetVarInt16In5" 4 "requested_engine_speed" 3 "vl_target_velocity_sup_rear" 2 "vl_target_velocity_sup_front" 1 "vl_target_velocity_ladder" 0 "NrOfObjects" ;
VAL_ 1409 SubIndex_A040 10 "NetVarUInt8In9A" 9 "MasterPTO_Feedback" 8 "NetVarUInt8In8" 7 "NetVarUInt8In7" 6 "NetVarUInt8In6" 5 "NetVarUInt8In5" 4 "PTO_Switch_State" 3 "Supportposvalue" 2 "SupportLock" 1 "LadderLock" 0 "NrOfObjects" ;
VAL_ 1409 SubIndex_A000 10 "NetVarInt8In10" 9 "NetVarInt8In9" 8 "NetVarInt8In8" 7 "NetVarInt8In7" 6 "NetVarInt8In6" 5 "NetVarInt8In5" 4 "NetVarInt8In4" 3 "NetVarInt8In3" 2 "NetVarInt8In2" 1 "CurrentGearValueM" 0 "NrOfObjects" ;
VAL_ 1409 SubIndex_1F88 127 "SerialNumber_7f" 126 "SerialNumber_7e" 125 "SerialNumber_7d" 124 "SerialNumber_7c" 123 "SerialNumber_7b" 122 "SerialNumber_7a" 121 "SerialNumber_79" 120 "SerialNumber_78" 119 "SerialNumber_77" 118 "SerialNumber_76" 117 "SerialNumber_75" 116 "SerialNumber_74" 115 "SerialNumber_73" 114 "SerialNumber_72" 113 "SerialNumber_71" 112 "SerialNumber_70" 111 "SerialNumber_6f" 110 "SerialNumber_6e" 109 "SerialNumber_6d" 108 "SerialNumber_6c" 107 "SerialNumber_6b" 106 "SerialNumber_6a" 105 "SerialNumber_69" 104 "SerialNumber_68" 103 "SerialNumber_67" 102 "SerialNumber_66" 101 "SerialNumber_65" 100 "SerialNumber_64" 99 "SerialNumber_63" 98 "SerialNumber_62" 97 "SerialNumber_61" 96 "SerialNumber_60" 95 "SerialNumber_5f" 94 "SerialNumber_5e" 93 "SerialNumber_5d" 92 "SerialNumber_5c" 91 "SerialNumber_5b" 90 "SerialNumber_5a" 89 "SerialNumber_59" 88 "SerialNumber_58" 87 "SerialNumber_57" 86 "SerialNumber_56" 85 "SerialNumber_55" 84 "SerialNumber_54" 83 "SerialNumber_53" 82 "SerialNumber_52" 81 "SerialNumber_51" 80 "SerialNumber_50" 79 "SerialNumber_4f" 78 "SerialNumber_4e" 77 "SerialNumber_4d" 76 "SerialNumber_4c" 75 "SerialNumber_4b" 74 "SerialNumber_4a" 73 "SerialNumber_49" 72 "SerialNumber_48" 71 "SerialNumber_47" 70 "SerialNumber_46" 69 "SerialNumber_45" 68 "SerialNumber_44" 67 "SerialNumber_43" 66 "SerialNumber_42" 65 "SerialNumber_41" 64 "SerialNumber_40" 63 "SerialNumber_3f" 62 "SerialNumber_3e" 61 "SerialNumber_3d" 60 "SerialNumber_3c" 59 "SerialNumber_3b" 58 "SerialNumber_3a" 57 "SerialNumber_39" 56 "SerialNumber_38" 55 "SerialNumber_37" 54 "SerialNumber_36" 53 "SerialNumber_35" 52 "SerialNumber_34" 51 "SerialNumber_33" 50 "SerialNumber_32" 49 "SerialNumber_31" 48 "SerialNumber_30" 47 "SerialNumber_2f" 46 "SerialNumber_2e" 45 "SerialNumber_2d" 44 "SerialNumber_2c" 43 "SerialNumber_2b" 42 "SerialNumber_2a" 41 "SerialNumber_29" 40 "SerialNumber_28" 39 "SerialNumber_27" 38 "SerialNumber_26" 37 "SerialNumber_25" 36 "SerialNumber_24" 35 "SerialNumber_23" 34 "SerialNumber_22" 33 "SerialNumber_21" 32 "SerialNumber_20" 31 "SerialNumber_1f" 30 "SerialNumber_1e" 29 "SerialNumber_1d" 28 "SerialNumber_1c" 27 "SerialNumber_1b" 26 "SerialNumber_1a" 25 "SerialNumber_19" 24 "SerialNumber_18" 23 "SerialNumber_17" 22 "SerialNumber_16" 21 "SerialNumber_15" 20 "SerialNumber_14" 19 "SerialNumber_13" 18 "SerialNumber_12" 17 "SerialNumber_11" 16 "SerialNumber_10" 15 "SerialNumber_f" 14 "SerialNumber_e" 13 "SerialNumber_d" 12 "SerialNumber_c" 11 "SerialNumber_b" 10 "SerialNumber_a" 9 "SerialNumber_9" 8 "SerialNumber_8" 7 "SerialNumber_7" 6 "SerialNumber_6" 5 "SerialNumber_5" 4 "SerialNumber_4" 3 "SerialNumber_3" 2 "SerialNumber_2" 1 "SerialNumber" 0 "NrOfObjects" ;
VAL_ 1409 SubIndex_1F85 127 "VendorIdentification_7f" 126 "VendorIdentification_7e" 125 "VendorIdentification_7d" 124 "VendorIdentification_7c" 123 "VendorIdentification_7b" 122 "VendorIdentification_7a" 121 "VendorIdentification_79" 120 "VendorIdentification_78" 119 "VendorIdentification_77" 118 "VendorIdentification_76" 117 "VendorIdentification_75" 116 "VendorIdentification_74" 115 "VendorIdentification_73" 114 "VendorIdentification_72" 113 "VendorIdentification_71" 112 "VendorIdentification_70" 111 "VendorIdentification_6f" 110 "VendorIdentification_6e" 109 "VendorIdentification_6d" 108 "VendorIdentification_6c" 107 "VendorIdentification_6b" 106 "VendorIdentification_6a" 105 "VendorIdentification_69" 104 "VendorIdentification_68" 103 "VendorIdentification_67" 102 "VendorIdentification_66" 101 "VendorIdentification_65" 100 "VendorIdentification_64" 99 "VendorIdentification_63" 98 "VendorIdentification_62" 97 "VendorIdentification_61" 96 "VendorIdentification_60" 95 "VendorIdentification_5f" 94 "VendorIdentification_5e" 93 "VendorIdentification_5d" 92 "VendorIdentification_5c" 91 "VendorIdentification_5b" 90 "VendorIdentification_5a" 89 "VendorIdentification_59" 88 "VendorIdentification_58" 87 "VendorIdentification_57" 86 "VendorIdentification_56" 85 "VendorIdentification_55" 84 "VendorIdentification_54" 83 "VendorIdentification_53" 82 "VendorIdentification_52" 81 "VendorIdentification_51" 80 "VendorIdentification_50" 79 "VendorIdentification_4f" 78 "VendorIdentification_4e" 77 "VendorIdentification_4d" 76 "VendorIdentification_4c" 75 "VendorIdentification_4b" 74 "VendorIdentification_4a" 73 "VendorIdentification_49" 72 "VendorIdentification_48" 71 "VendorIdentification_47" 70 "VendorIdentification_46" 69 "VendorIdentification_45" 68 "VendorIdentification_44" 67 "VendorIdentification_43" 66 "VendorIdentification_42" 65 "VendorIdentification_41" 64 "VendorIdentification_40" 63 "VendorIdentification_3f" 62 "VendorIdentification_3e" 61 "VendorIdentification_3d" 60 "VendorIdentification_3c" 59 "VendorIdentification_3b" 58 "VendorIdentification_3a" 57 "VendorIdentification_39" 56 "VendorIdentification_38" 55 "VendorIdentification_37" 54 "VendorIdentification_36" 53 "VendorIdentification_35" 52 "VendorIdentification_34" 51 "VendorIdentification_33" 50 "VendorIdentification_32" 49 "VendorIdentification_31" 48 "VendorIdentification_30" 47 "VendorIdentification_2f" 46 "VendorIdentification_2e" 45 "VendorIdentification_2d" 44 "VendorIdentification_2c" 43 "VendorIdentification_2b" 42 "VendorIdentification_2a" 41 "VendorIdentification_29" 40 "VendorIdentification_28" 39 "VendorIdentification_27" 38 "VendorIdentification_26" 37 "VendorIdentification_25" 36 "VendorIdentification_24" 35 "VendorIdentification_23" 34 "VendorIdentification_22" 33 "VendorIdentification_21" 32 "VendorIdentification_20" 31 "VendorIdentification_1f" 30 "VendorIdentification_1e" 29 "VendorIdentification_1d" 28 "VendorIdentification_1c" 27 "VendorIdentification_1b" 26 "VendorIdentification_1a" 25 "VendorIdentification_19" 24 "VendorIdentification_18" 23 "VendorIdentification_17" 22 "VendorIdentification_16" 21 "VendorIdentification_15" 20 "VendorIdentification_14" 19 "VendorIdentification_13" 18 "VendorIdentification_12" 17 "VendorIdentification_11" 16 "VendorIdentification_10" 15 "VendorIdentification_f" 14 "VendorIdentification_e" 13 "VendorIdentification_d" 12 "VendorIdentification_c" 11 "VendorIdentification_b" 10 "VendorIdentification_a" 9 "VendorIdentification_9" 8 "VendorIdentification_8" 7 "VendorIdentification_7" 6 "VendorIdentification_6" 5 "VendorIdentification_5" 4 "VendorIdentification_4" 3 "VendorIdentification_3" 2 "VendorIdentification_2" 1 "VendorIdentification" 0 "NrOfObjects" ;
VAL_ 1409 SubIndex_1F83 128 "RequestGuard All" 127 "RequestGuard" 126 "RequestGuard" 125 "RequestGuard" 124 "RequestGuard" 123 "RequestGuard" 122 "RequestGuard" 121 "RequestGuard" 120 "RequestGuard" 119 "RequestGuard" 118 "RequestGuard" 117 "RequestGuard" 116 "RequestGuard" 115 "RequestGuard" 114 "RequestGuard" 113 "RequestGuard" 112 "RequestGuard" 111 "RequestGuard" 110 "RequestGuard" 109 "RequestGuard" 108 "RequestGuard" 107 "RequestGuard" 106 "RequestGuard" 105 "RequestGuard" 104 "RequestGuard" 103 "RequestGuard" 102 "RequestGuard" 101 "RequestGuard" 100 "RequestGuard" 99 "RequestGuard" 98 "RequestGuard" 97 "RequestGuard" 96 "RequestGuard" 95 "RequestGuard" 94 "RequestGuard" 93 "RequestGuard" 92 "RequestGuard" 91 "RequestGuard" 90 "RequestGuard" 89 "RequestGuard" 88 "RequestGuard" 87 "RequestGuard" 86 "RequestGuard" 85 "RequestGuard" 84 "RequestGuard" 83 "RequestGuard" 82 "RequestGuard" 81 "RequestGuard" 80 "RequestGuard" 79 "RequestGuard" 78 "RequestGuard" 77 "RequestGuard" 76 "RequestGuard" 75 "RequestGuard" 74 "RequestGuard" 73 "RequestGuard" 72 "RequestGuard" 71 "RequestGuard" 70 "RequestGuard" 69 "RequestGuard" 68 "RequestGuard" 67 "RequestGuard" 66 "RequestGuard" 65 "RequestGuard" 64 "RequestGuard" 63 "RequestGuard" 62 "RequestGuard" 61 "RequestGuard" 60 "RequestGuard" 59 "RequestGuard" 58 "RequestGuard" 57 "RequestGuard" 56 "RequestGuard" 55 "RequestGuard" 54 "RequestGuard" 53 "RequestGuard" 52 "RequestGuard" 51 "RequestGuard" 50 "RequestGuard" 49 "RequestGuard" 48 "RequestGuard" 47 "RequestGuard" 46 "RequestGuard" 45 "RequestGuard" 44 "RequestGuard" 43 "RequestGuard" 42 "RequestGuard" 41 "RequestGuard" 40 "RequestGuard" 39 "RequestGuard" 38 "RequestGuard" 37 "RequestGuard" 36 "RequestGuard" 35 "RequestGuard" 34 "RequestGuard" 33 "RequestGuard" 32 "RequestGuard" 31 "RequestGuard" 30 "RequestGuard" 29 "RequestGuard" 28 "RequestGuard" 27 "RequestGuard" 26 "RequestGuard" 25 "RequestGuard" 24 "RequestGuard" 23 "RequestGuard" 22 "RequestGuard" 21 "RequestGuard" 20 "RequestGuard" 19 "RequestGuard" 18 "RequestGuard" 17 "RequestGuard" 16 "RequestGuard" 15 "RequestGuard" 14 "RequestGuard" 13 "RequestGuard" 12 "RequestGuard" 11 "RequestGuard" 10 "RequestGuard" 9 "RequestGuard" 8 "RequestGuard" 7 "RequestGuard" 6 "RequestGuard" 5 "RequestGuard" 4 "RequestGuard" 3 "RequestGuard" 2 "RequestGuard" 1 "RequestGuard" 0 "Highest sub-index supported" ;
VAL_ 1409 SubIndex_1F82 128 "RequestNMT All" 127 "RequestNMT" 126 "RequestNMT" 125 "RequestNMT" 124 "RequestNMT" 123 "RequestNMT" 122 "RequestNMT" 121 "RequestNMT" 120 "RequestNMT" 119 "RequestNMT" 118 "RequestNMT" 117 "RequestNMT" 116 "RequestNMT" 115 "RequestNMT" 114 "RequestNMT" 113 "RequestNMT" 112 "RequestNMT" 111 "RequestNMT" 110 "RequestNMT" 109 "RequestNMT" 108 "RequestNMT" 107 "RequestNMT" 106 "RequestNMT" 105 "RequestNMT" 104 "RequestNMT" 103 "RequestNMT" 102 "RequestNMT" 101 "RequestNMT" 100 "RequestNMT" 99 "RequestNMT" 98 "RequestNMT" 97 "RequestNMT" 96 "RequestNMT" 95 "RequestNMT" 94 "RequestNMT" 93 "RequestNMT" 92 "RequestNMT" 91 "RequestNMT" 90 "RequestNMT" 89 "RequestNMT" 88 "RequestNMT" 87 "RequestNMT" 86 "RequestNMT" 85 "RequestNMT" 84 "RequestNMT" 83 "RequestNMT" 82 "RequestNMT" 81 "RequestNMT" 80 "RequestNMT" 79 "RequestNMT" 78 "RequestNMT" 77 "RequestNMT" 76 "RequestNMT" 75 "RequestNMT" 74 "RequestNMT" 73 "RequestNMT" 72 "RequestNMT" 71 "RequestNMT" 70 "RequestNMT" 69 "RequestNMT" 68 "RequestNMT" 67 "RequestNMT" 66 "RequestNMT" 65 "RequestNMT" 64 "RequestNMT" 63 "RequestNMT" 62 "RequestNMT" 61 "RequestNMT" 60 "RequestNMT" 59 "RequestNMT" 58 "RequestNMT" 57 "RequestNMT" 56 "RequestNMT" 55 "RequestNMT" 54 "RequestNMT" 53 "RequestNMT" 52 "RequestNMT" 51 "RequestNMT" 50 "RequestNMT" 49 "RequestNMT" 48 "RequestNMT" 47 "RequestNMT" 46 "RequestNMT" 45 "RequestNMT" 44 "RequestNMT" 43 "RequestNMT" 42 "RequestNMT" 41 "RequestNMT" 40 "RequestNMT" 39 "RequestNMT" 38 "RequestNMT" 37 "RequestNMT" 36 "RequestNMT" 35 "RequestNMT" 34 "RequestNMT" 33 "RequestNMT" 32 "RequestNMT" 31 "RequestNMT" 30 "RequestNMT" 29 "RequestNMT" 28 "RequestNMT" 27 "RequestNMT" 26 "RequestNMT" 25 "RequestNMT" 24 "RequestNMT" 23 "RequestNMT" 22 "RequestNMT" 21 "RequestNMT" 20 "RequestNMT" 19 "RequestNMT" 18 "RequestNMT" 17 "RequestNMT" 16 "RequestNMT" 15 "RequestNMT" 14 "RequestNMT" 13 "RequestNMT" 12 "RequestNMT" 11 "RequestNMT" 10 "RequestNMT" 9 "RequestNMT" 8 "RequestNMT" 7 "RequestNMT" 6 "RequestNMT" 5 "RequestNMT" 4 "RequestNMT" 3 "RequestNMT" 2 "RequestNMT" 1 "RequestNMT" 0 "Highest sub-index supported" ;

SG_MUL_VAL_ 1410 requested_engine_speed_minimum_v SubIndex_614A 3-3;
SG_MUL_VAL_ 1410 requested_engine_speed_maximum_v SubIndex_614A 2-2;
SG_MUL_VAL_ 1410 requested_engine_speed_value_614 SubIndex_614A 1-1;
SG_MUL_VAL_ 1410 requested_engine_speed_number_of SubIndex_614A 0-0;
SG_MUL_VAL_ 1410 SubIndex_614A Index 24906-24906;
SG_MUL_VAL_ 1410 requested_engine_speed_lower_lim SubIndex_6142 3-3;
SG_MUL_VAL_ 1410 requested_engine_speed_lowe_0000 SubIndex_6142 2-2;
SG_MUL_VAL_ 1410 requested_engine_speed_lowe_0001 SubIndex_6142 1-1;
SG_MUL_VAL_ 1410 requested_engine_speed_lowe_0002 SubIndex_6142 0-0;
SG_MUL_VAL_ 1410 SubIndex_6142 Index 24898-24898;
SG_MUL_VAL_ 1410 requested_engine_speed_upper_lim SubIndex_6140 3-3;
SG_MUL_VAL_ 1410 requested_engine_speed_uppe_0000 SubIndex_6140 2-2;
SG_MUL_VAL_ 1410 requested_engine_speed_uppe_0001 SubIndex_6140 1-1;
SG_MUL_VAL_ 1410 requested_engine_speed_uppe_0002 SubIndex_6140 0-0;
SG_MUL_VAL_ 1410 SubIndex_6140 Index 24896-24896;
SG_MUL_VAL_ 1410 engine_stop_switch_Bit_1_613F_01 SubIndex_613F 1-1;
SG_MUL_VAL_ 1410 engine_stop_switch_Number_of_ent SubIndex_613F 0-0;
SG_MUL_VAL_ 1410 SubIndex_613F Index 24895-24895;
SG_MUL_VAL_ 1410 engine_start_switch_Bit_1_613E_0 SubIndex_613E 1-1;
SG_MUL_VAL_ 1410 engine_start_switch_Number_of_en SubIndex_613E 0-0;
SG_MUL_VAL_ 1410 SubIndex_613E Index 24894-24894;
SG_MUL_VAL_ 1410 first_clutch_dependent_PTO_switc SubIndex_6136 1-1;
SG_MUL_VAL_ 1410 first_clutch_dependent_PTO__0000 SubIndex_6136 0-0;
SG_MUL_VAL_ 1410 SubIndex_6136 Index 24886-24886;
SG_MUL_VAL_ 1410 first_engine_mounted_PTO_feedbac SubIndex_6131 1-1;
SG_MUL_VAL_ 1410 first_engine_mounted_PTO_fe_0000 SubIndex_6131 0-0;
SG_MUL_VAL_ 1410 SubIndex_6131 Index 24881-24881;
SG_MUL_VAL_ 1410 PTOSwitch_6113_05 SubIndex_6113 5-5;
SG_MUL_VAL_ 1410 SupportPositionGateIn_6113_04 SubIndex_6113 4-4;
SG_MUL_VAL_ 1410 engine_speed_minimum_value_range SubIndex_6113 3-3;
SG_MUL_VAL_ 1410 engine_speed_maximum_value_range SubIndex_6113 2-2;
SG_MUL_VAL_ 1410 EngineSpeed_6113_01 SubIndex_6113 1-1;
SG_MUL_VAL_ 1410 NrOfObjects_6113_00 SubIndex_6113 0-0;
SG_MUL_VAL_ 1410 SubIndex_6113 Index 24851-24851;
SG_MUL_VAL_ 1410 current_gear_minimum_value_range SubIndex_610C 3-3;
SG_MUL_VAL_ 1410 current_gear_maximum_value_range SubIndex_610C 2-2;
SG_MUL_VAL_ 1410 CurrentGearValue_610C_01 SubIndex_610C 1-1;
SG_MUL_VAL_ 1410 NrOfObjects_610C_00 SubIndex_610C 0-0;
SG_MUL_VAL_ 1410 SubIndex_610C Index 24844-24844;
SG_MUL_VAL_ 1410 wheel_based_vehicle_speed_minimu SubIndex_6006 3-3;
SG_MUL_VAL_ 1410 wheel_based_vehicle_speed_maximu SubIndex_6006 2-2;
SG_MUL_VAL_ 1410 wheel_based_vehicle_speed_value_ SubIndex_6006 1-1;
SG_MUL_VAL_ 1410 wheel_based_vehicle_speed_number SubIndex_6006 0-0;
SG_MUL_VAL_ 1410 SubIndex_6006 Index 24582-24582;
SG_MUL_VAL_ 1410 park_brake_demand_value_minimum_ SubIndex_6000 3-3;
SG_MUL_VAL_ 1410 park_brake_demand_value_maximum_ SubIndex_6000 2-2;
SG_MUL_VAL_ 1410 ParkBrakeDemandValue_6000_01 SubIndex_6000 1-1;
SG_MUL_VAL_ 1410 NrOfObjects_6000_00 SubIndex_6000 0-0;
SG_MUL_VAL_ 1410 SubIndex_6000 Index 24576-24576;
SG_MUL_VAL_ 1410 NrOfMappedObjects_1A02_00 SubIndex_1A02 0-0;
SG_MUL_VAL_ 1410 SubIndex_1A02 Index 6658-6658;
SG_MUL_VAL_ 1410 NrOfMappedObjects_1A01_00 SubIndex_1A01 0-0;
SG_MUL_VAL_ 1410 SubIndex_1A01 Index 6657-6657;
SG_MUL_VAL_ 1410 mappedObj5_1A00_05 SubIndex_1A00 5-5;
SG_MUL_VAL_ 1410 mappedObj4_1A00_04 SubIndex_1A00 4-4;
SG_MUL_VAL_ 1410 mappedObj3_1A00_03 SubIndex_1A00 3-3;
SG_MUL_VAL_ 1410 mappedObj2_1A00_02 SubIndex_1A00 2-2;
SG_MUL_VAL_ 1410 mappedObj1_1A00_01 SubIndex_1A00 1-1;
SG_MUL_VAL_ 1410 NrOfMappedObjects_1A00_00 SubIndex_1A00 0-0;
SG_MUL_VAL_ 1410 SubIndex_1A00 Index 6656-6656;
SG_MUL_VAL_ 1410 EventTimer_1802_05 SubIndex_1802 5-5;
SG_MUL_VAL_ 1410 TransmissionType_1802_02 SubIndex_1802 2-2;
SG_MUL_VAL_ 1410 COB_ID_1802_01 SubIndex_1802 1-1;
SG_MUL_VAL_ 1410 Highest_sub_index_supported_1802 SubIndex_1802 0-0;
SG_MUL_VAL_ 1410 SubIndex_1802 Index 6146-6146;
SG_MUL_VAL_ 1410 EventTimer_1801_05 SubIndex_1801 5-5;
SG_MUL_VAL_ 1410 TransmissionType_1801_02 SubIndex_1801 2-2;
SG_MUL_VAL_ 1410 COB_ID_1801_01 SubIndex_1801 1-1;
SG_MUL_VAL_ 1410 Highest_sub_index_supported_1801 SubIndex_1801 0-0;
SG_MUL_VAL_ 1410 SubIndex_1801 Index 6145-6145;
SG_MUL_VAL_ 1410 EventTimer_1800_05 SubIndex_1800 5-5;
SG_MUL_VAL_ 1410 TransmissionType_1800_02 SubIndex_1800 2-2;
SG_MUL_VAL_ 1410 COB_ID_1800_01 SubIndex_1800 1-1;
SG_MUL_VAL_ 1410 Highest_sub_index_supported_1800 SubIndex_1800 0-0;
SG_MUL_VAL_ 1410 SubIndex_1800 Index 6144-6144;
SG_MUL_VAL_ 1410 GENERATED_1602_03 SubIndex_1602 3-3;
SG_MUL_VAL_ 1410 GENERATED_1602_02 SubIndex_1602 2-2;
SG_MUL_VAL_ 1410 GENERATED_1602_01 SubIndex_1602 1-1;
SG_MUL_VAL_ 1410 NrOfMappedObjects_1602_00 SubIndex_1602 0-0;
SG_MUL_VAL_ 1410 SubIndex_1602 Index 5634-5634;
SG_MUL_VAL_ 1410 PTO_Switch_1601_01 SubIndex_1601 1-1;
SG_MUL_VAL_ 1410 NrOfMappedObjects_1601_00 SubIndex_1601 0-0;
SG_MUL_VAL_ 1410 SubIndex_1601 Index 5633-5633;
SG_MUL_VAL_ 1410 mappedObj5_1600_05 SubIndex_1600 5-5;
SG_MUL_VAL_ 1410 mappedObj4_1600_04 SubIndex_1600 4-4;
SG_MUL_VAL_ 1410 mappedObj3_1600_03 SubIndex_1600 3-3;
SG_MUL_VAL_ 1410 mappedObj2_1600_02 SubIndex_1600 2-2;
SG_MUL_VAL_ 1410 mappedObj1_1600_01 SubIndex_1600 1-1;
SG_MUL_VAL_ 1410 NrOfMappedObjects_1600_00 SubIndex_1600 0-0;
SG_MUL_VAL_ 1410 SubIndex_1600 Index 5632-5632;
SG_MUL_VAL_ 1410 TransmissionType_1402_02 SubIndex_1402 2-2;
SG_MUL_VAL_ 1410 COB_ID_1402_01 SubIndex_1402 1-1;
SG_MUL_VAL_ 1410 Highest_sub_index_supported_1402 SubIndex_1402 0-0;
SG_MUL_VAL_ 1410 SubIndex_1402 Index 5122-5122;
SG_MUL_VAL_ 1410 TransmissionType_1401_02 SubIndex_1401 2-2;
SG_MUL_VAL_ 1410 COB_ID_1401_01 SubIndex_1401 1-1;
SG_MUL_VAL_ 1410 Highest_sub_index_supported_1401 SubIndex_1401 0-0;
SG_MUL_VAL_ 1410 SubIndex_1401 Index 5121-5121;
SG_MUL_VAL_ 1410 TransmissionType_1400_02 SubIndex_1400 2-2;
SG_MUL_VAL_ 1410 COB_ID_1400_01 SubIndex_1400 1-1;
SG_MUL_VAL_ 1410 Highest_sub_index_supported_1400 SubIndex_1400 0-0;
SG_MUL_VAL_ 1410 SubIndex_1400 Index 5120-5120;
SG_MUL_VAL_ 1410 Vendor_Id_1018_01 SubIndex_1018 1-1;
SG_MUL_VAL_ 1410 NrOfElements_1018_00 SubIndex_1018 0-0;
SG_MUL_VAL_ 1410 SubIndex_1018 Index 4120-4120;
SG_MUL_VAL_ 1410 Sync_Window_Length_1007 SubIndex_1007 0-0;
SG_MUL_VAL_ 1410 SubIndex_1007 Index 4103-4103;
SG_MUL_VAL_ 1410 Communication_Cycle_Period_1006 SubIndex_1006 0-0;
SG_MUL_VAL_ 1410 SubIndex_1006 Index 4102-4102;
SG_MUL_VAL_ 1410 COB_ID_SYNC_1005 SubIndex_1005 0-0;
SG_MUL_VAL_ 1410 SubIndex_1005 Index 4101-4101;
SG_MUL_VAL_ 1410 ErrorRegister_1001 SubIndex_1001 0-0;
SG_MUL_VAL_ 1410 SubIndex_1001 Index 4097-4097;
SG_MUL_VAL_ 1410 Device_Type_1000 SubIndex_1000 0-0;
SG_MUL_VAL_ 1410 SubIndex_1000 Index 4096-4096;
SG_MUL_VAL_ 1410 Index TransferType 1-1;
SG_MUL_VAL_ 1410 TransferType SCS 1-2;
SG_MUL_VAL_ 1410 NotUsedBytes SCS 1-2;
SG_MUL_VAL_ 1410 SizeIndicator SCS 1-2;
SG_MUL_VAL_ 1538 requested_engine_speed_mini_0000 SubIndex_614A 3-3;
SG_MUL_VAL_ 1538 requested_engine_speed_maxi_0000 SubIndex_614A 2-2;
SG_MUL_VAL_ 1538 requested_engine_speed_valu_0000 SubIndex_614A 1-1;
SG_MUL_VAL_ 1538 requested_engine_speed_numb_0000 SubIndex_614A 0-0;
SG_MUL_VAL_ 1538 SubIndex_614A Index 24906-24906;
SG_MUL_VAL_ 1538 requested_engine_speed_lowe_0003 SubIndex_6142 3-3;
SG_MUL_VAL_ 1538 requested_engine_speed_lowe_0004 SubIndex_6142 2-2;
SG_MUL_VAL_ 1538 requested_engine_speed_lowe_0005 SubIndex_6142 1-1;
SG_MUL_VAL_ 1538 requested_engine_speed_lowe_0006 SubIndex_6142 0-0;
SG_MUL_VAL_ 1538 SubIndex_6142 Index 24898-24898;
SG_MUL_VAL_ 1538 requested_engine_speed_uppe_0003 SubIndex_6140 3-3;
SG_MUL_VAL_ 1538 requested_engine_speed_uppe_0004 SubIndex_6140 2-2;
SG_MUL_VAL_ 1538 requested_engine_speed_uppe_0005 SubIndex_6140 1-1;
SG_MUL_VAL_ 1538 requested_engine_speed_uppe_0006 SubIndex_6140 0-0;
SG_MUL_VAL_ 1538 SubIndex_6140 Index 24896-24896;
SG_MUL_VAL_ 1538 engine_stop_switch_Bit_1_613F_01 SubIndex_613F 1-1;
SG_MUL_VAL_ 1538 engine_stop_switch_Number_o_0000 SubIndex_613F 0-0;
SG_MUL_VAL_ 1538 SubIndex_613F Index 24895-24895;
SG_MUL_VAL_ 1538 engine_start_switch_Bit_1_6_0000 SubIndex_613E 1-1;
SG_MUL_VAL_ 1538 engine_start_switch_Number__0000 SubIndex_613E 0-0;
SG_MUL_VAL_ 1538 SubIndex_613E Index 24894-24894;
SG_MUL_VAL_ 1538 first_clutch_dependent_PTO__0001 SubIndex_6136 1-1;
SG_MUL_VAL_ 1538 first_clutch_dependent_PTO__0002 SubIndex_6136 0-0;
SG_MUL_VAL_ 1538 SubIndex_6136 Index 24886-24886;
SG_MUL_VAL_ 1538 first_engine_mounted_PTO_fe_0001 SubIndex_6131 1-1;
SG_MUL_VAL_ 1538 first_engine_mounted_PTO_fe_0002 SubIndex_6131 0-0;
SG_MUL_VAL_ 1538 SubIndex_6131 Index 24881-24881;
SG_MUL_VAL_ 1538 PTOSwitch_6113_05 SubIndex_6113 5-5;
SG_MUL_VAL_ 1538 SupportPositionGateIn_6113_04 SubIndex_6113 4-4;
SG_MUL_VAL_ 1538 engine_speed_minimum_value__0000 SubIndex_6113 3-3;
SG_MUL_VAL_ 1538 engine_speed_maximum_value__0000 SubIndex_6113 2-2;
SG_MUL_VAL_ 1538 EngineSpeed_6113_01 SubIndex_6113 1-1;
SG_MUL_VAL_ 1538 NrOfObjects_6113_00 SubIndex_6113 0-0;
SG_MUL_VAL_ 1538 SubIndex_6113 Index 24851-24851;
SG_MUL_VAL_ 1538 current_gear_minimum_value__0000 SubIndex_610C 3-3;
SG_MUL_VAL_ 1538 current_gear_maximum_value__0000 SubIndex_610C 2-2;
SG_MUL_VAL_ 1538 CurrentGearValue_610C_01 SubIndex_610C 1-1;
SG_MUL_VAL_ 1538 NrOfObjects_610C_00 SubIndex_610C 0-0;
SG_MUL_VAL_ 1538 SubIndex_610C Index 24844-24844;
SG_MUL_VAL_ 1538 wheel_based_vehicle_speed_m_0000 SubIndex_6006 3-3;
SG_MUL_VAL_ 1538 wheel_based_vehicle_speed_m_0001 SubIndex_6006 2-2;
SG_MUL_VAL_ 1538 wheel_based_vehicle_speed_v_0000 SubIndex_6006 1-1;
SG_MUL_VAL_ 1538 wheel_based_vehicle_speed_n_0000 SubIndex_6006 0-0;
SG_MUL_VAL_ 1538 SubIndex_6006 Index 24582-24582;
SG_MUL_VAL_ 1538 park_brake_demand_value_min_0000 SubIndex_6000 3-3;
SG_MUL_VAL_ 1538 park_brake_demand_value_max_0000 SubIndex_6000 2-2;
SG_MUL_VAL_ 1538 ParkBrakeDemandValue_6000_01 SubIndex_6000 1-1;
SG_MUL_VAL_ 1538 NrOfObjects_6000_00 SubIndex_6000 0-0;
SG_MUL_VAL_ 1538 SubIndex_6000 Index 24576-24576;
SG_MUL_VAL_ 1538 NrOfMappedObjects_1A02_00 SubIndex_1A02 0-0;
SG_MUL_VAL_ 1538 SubIndex_1A02 Index 6658-6658;
SG_MUL_VAL_ 1538 NrOfMappedObjects_1A01_00 SubIndex_1A01 0-0;
SG_MUL_VAL_ 1538 SubIndex_1A01 Index 6657-6657;
SG_MUL_VAL_ 1538 mappedObj5_1A00_05 SubIndex_1A00 5-5;
SG_MUL_VAL_ 1538 mappedObj4_1A00_04 SubIndex_1A00 4-4;
SG_MUL_VAL_ 1538 mappedObj3_1A00_03 SubIndex_1A00 3-3;
SG_MUL_VAL_ 1538 mappedObj2_1A00_02 SubIndex_1A00 2-2;
SG_MUL_VAL_ 1538 mappedObj1_1A00_01 SubIndex_1A00 1-1;
SG_MUL_VAL_ 1538 NrOfMappedObjects_1A00_00 SubIndex_1A00 0-0;
SG_MUL_VAL_ 1538 SubIndex_1A00 Index 6656-6656;
SG_MUL_VAL_ 1538 EventTimer_1802_05 SubIndex_1802 5-5;
SG_MUL_VAL_ 1538 TransmissionType_1802_02 SubIndex_1802 2-2;
SG_MUL_VAL_ 1538 COB_ID_1802_01 SubIndex_1802 1-1;
SG_MUL_VAL_ 1538 Highest_sub_index_supported_0000 SubIndex_1802 0-0;
SG_MUL_VAL_ 1538 SubIndex_1802 Index 6146-6146;
SG_MUL_VAL_ 1538 EventTimer_1801_05 SubIndex_1801 5-5;
SG_MUL_VAL_ 1538 TransmissionType_1801_02 SubIndex_1801 2-2;
SG_MUL_VAL_ 1538 COB_ID_1801_01 SubIndex_1801 1-1;
SG_MUL_VAL_ 1538 Highest_sub_index_supported_0001 SubIndex_1801 0-0;
SG_MUL_VAL_ 1538 SubIndex_1801 Index 6145-6145;
SG_MUL_VAL_ 1538 EventTimer_1800_05 SubIndex_1800 5-5;
SG_MUL_VAL_ 1538 TransmissionType_1800_02 SubIndex_1800 2-2;
SG_MUL_VAL_ 1538 COB_ID_1800_01 SubIndex_1800 1-1;
SG_MUL_VAL_ 1538 Highest_sub_index_supported_0002 SubIndex_1800 0-0;
SG_MUL_VAL_ 1538 SubIndex_1800 Index 6144-6144;
SG_MUL_VAL_ 1538 GENERATED_1602_03 SubIndex_1602 3-3;
SG_MUL_VAL_ 1538 GENERATED_1602_02 SubIndex_1602 2-2;
SG_MUL_VAL_ 1538 GENERATED_1602_01 SubIndex_1602 1-1;
SG_MUL_VAL_ 1538 NrOfMappedObjects_1602_00 SubIndex_1602 0-0;
SG_MUL_VAL_ 1538 SubIndex_1602 Index 5634-5634;
SG_MUL_VAL_ 1538 PTO_Switch_1601_01 SubIndex_1601 1-1;
SG_MUL_VAL_ 1538 NrOfMappedObjects_1601_00 SubIndex_1601 0-0;
SG_MUL_VAL_ 1538 SubIndex_1601 Index 5633-5633;
SG_MUL_VAL_ 1538 mappedObj5_1600_05 SubIndex_1600 5-5;
SG_MUL_VAL_ 1538 mappedObj4_1600_04 SubIndex_1600 4-4;
SG_MUL_VAL_ 1538 mappedObj3_1600_03 SubIndex_1600 3-3;
SG_MUL_VAL_ 1538 mappedObj2_1600_02 SubIndex_1600 2-2;
SG_MUL_VAL_ 1538 mappedObj1_1600_01 SubIndex_1600 1-1;
SG_MUL_VAL_ 1538 NrOfMappedObjects_1600_00 SubIndex_1600 0-0;
SG_MUL_VAL_ 1538 SubIndex_1600 Index 5632-5632;
SG_MUL_VAL_ 1538 TransmissionType_1402_02 SubIndex_1402 2-2;
SG_MUL_VAL_ 1538 COB_ID_1402_01 SubIndex_1402 1-1;
SG_MUL_VAL_ 1538 Highest_sub_index_supported_0003 SubIndex_1402 0-0;
SG_MUL_VAL_ 1538 SubIndex_1402 Index 5122-5122;
SG_MUL_VAL_ 1538 TransmissionType_1401_02 SubIndex_1401 2-2;
SG_MUL_VAL_ 1538 COB_ID_1401_01 SubIndex_1401 1-1;
SG_MUL_VAL_ 1538 Highest_sub_index_supported_0004 SubIndex_1401 0-0;
SG_MUL_VAL_ 1538 SubIndex_1401 Index 5121-5121;
SG_MUL_VAL_ 1538 TransmissionType_1400_02 SubIndex_1400 2-2;
SG_MUL_VAL_ 1538 COB_ID_1400_01 SubIndex_1400 1-1;
SG_MUL_VAL_ 1538 Highest_sub_index_supported_0005 SubIndex_1400 0-0;
SG_MUL_VAL_ 1538 SubIndex_1400 Index 5120-5120;
SG_MUL_VAL_ 1538 Vendor_Id_1018_01 SubIndex_1018 1-1;
SG_MUL_VAL_ 1538 NrOfElements_1018_00 SubIndex_1018 0-0;
SG_MUL_VAL_ 1538 SubIndex_1018 Index 4120-4120;
SG_MUL_VAL_ 1538 Sync_Window_Length_1007 SubIndex_1007 0-0;
SG_MUL_VAL_ 1538 SubIndex_1007 Index 4103-4103;
SG_MUL_VAL_ 1538 Communication_Cycle_Period_1006 SubIndex_1006 0-0;
SG_MUL_VAL_ 1538 SubIndex_1006 Index 4102-4102;
SG_MUL_VAL_ 1538 COB_ID_SYNC_1005 SubIndex_1005 0-0;
SG_MUL_VAL_ 1538 SubIndex_1005 Index 4101-4101;
SG_MUL_VAL_ 1538 ErrorRegister_1001 SubIndex_1001 0-0;
SG_MUL_VAL_ 1538 SubIndex_1001 Index 4097-4097;
SG_MUL_VAL_ 1538 Device_Type_1000 SubIndex_1000 0-0;
SG_MUL_VAL_ 1538 SubIndex_1000 Index 4096-4096;
SG_MUL_VAL_ 1538 Index TransferType 1-1;
SG_MUL_VAL_ 1538 TransferType CCS 1-2;
SG_MUL_VAL_ 1538 NotUsedBytes CCS 1-2;
SG_MUL_VAL_ 1538 SizeIndicator CCS 1-2;
SG_MUL_VAL_ 1409 NetVarUInt32Out10_A680_0A SubIndex_A680 10-10;
SG_MUL_VAL_ 1409 NetVarUInt32Out9_A680_09 SubIndex_A680 9-9;
SG_MUL_VAL_ 1409 NetVarUInt32Out8_A680_08 SubIndex_A680 8-8;
SG_MUL_VAL_ 1409 NetVarUInt32Out7_A680_07 SubIndex_A680 7-7;
SG_MUL_VAL_ 1409 NetVarUInt32Out6_A680_06 SubIndex_A680 6-6;
SG_MUL_VAL_ 1409 NetVarUInt32Out5_A680_05 SubIndex_A680 5-5;
SG_MUL_VAL_ 1409 NetVarUInt32Out4_A680_04 SubIndex_A680 4-4;
SG_MUL_VAL_ 1409 NetVarUInt32Out3_A680_03 SubIndex_A680 3-3;
SG_MUL_VAL_ 1409 NetVarUInt32Out2_A680_02 SubIndex_A680 2-2;
SG_MUL_VAL_ 1409 NetVarUInt32Out1_A680_01 SubIndex_A680 1-1;
SG_MUL_VAL_ 1409 NrOfObjects_A680_00 SubIndex_A680 0-0;
SG_MUL_VAL_ 1409 SubIndex_A680 Index 42624-42624;
SG_MUL_VAL_ 1409 NetVarInt32Out10_A640_0A SubIndex_A640 10-10;
SG_MUL_VAL_ 1409 NetVarInt32Out9_A640_09 SubIndex_A640 9-9;
SG_MUL_VAL_ 1409 NetVarInt32Out8_A640_08 SubIndex_A640 8-8;
SG_MUL_VAL_ 1409 NetVarInt32Out7_A640_07 SubIndex_A640 7-7;
SG_MUL_VAL_ 1409 NetVarInt32Out6_A640_06 SubIndex_A640 6-6;
SG_MUL_VAL_ 1409 NetVarInt32Out5_A640_05 SubIndex_A640 5-5;
SG_MUL_VAL_ 1409 NetVarInt32Out4_A640_04 SubIndex_A640 4-4;
SG_MUL_VAL_ 1409 pos_act_val_sup_rear_A640_03 SubIndex_A640 3-3;
SG_MUL_VAL_ 1409 pos_act_val_sup_front_A640_02 SubIndex_A640 2-2;
SG_MUL_VAL_ 1409 pos_act_val_ladder_A640_01 SubIndex_A640 1-1;
SG_MUL_VAL_ 1409 NrOfObjects_A640_00 SubIndex_A640 0-0;
SG_MUL_VAL_ 1409 SubIndex_A640 Index 42560-42560;
SG_MUL_VAL_ 1409 NetVarUInt16Out10_A580_0A SubIndex_A580 10-10;
SG_MUL_VAL_ 1409 NetVarUInt16Out9_A580_09 SubIndex_A580 9-9;
SG_MUL_VAL_ 1409 NetVarUInt16Out8_A580_08 SubIndex_A580 8-8;
SG_MUL_VAL_ 1409 EngineSpeed_A580_07 SubIndex_A580 7-7;
SG_MUL_VAL_ 1409 wheel_based_vehicle_speed_A580_0 SubIndex_A580 6-6;
SG_MUL_VAL_ 1409 NetVarUInt16Out5_A580_05 SubIndex_A580 5-5;
SG_MUL_VAL_ 1409 NetVarUInt16Out4_A580_04 SubIndex_A580 4-4;
SG_MUL_VAL_ 1409 statusword_support_rear_A580_03 SubIndex_A580 3-3;
SG_MUL_VAL_ 1409 statusword_support_front_A580_02 SubIndex_A580 2-2;
SG_MUL_VAL_ 1409 statusword_ladder_A580_01 SubIndex_A580 1-1;
SG_MUL_VAL_ 1409 NrOfObjects_A580_00 SubIndex_A580 0-0;
SG_MUL_VAL_ 1409 SubIndex_A580 Index 42368-42368;
SG_MUL_VAL_ 1409 NetVarInt16Out10_A540_0A SubIndex_A540 10-10;
SG_MUL_VAL_ 1409 NetVarInt16Out9_A540_09 SubIndex_A540 9-9;
SG_MUL_VAL_ 1409 NetVarInt16Out8_A540_08 SubIndex_A540 8-8;
SG_MUL_VAL_ 1409 NetVarInt16Out7_A540_07 SubIndex_A540 7-7;
SG_MUL_VAL_ 1409 NetVarInt16Out6_A540_06 SubIndex_A540 6-6;
SG_MUL_VAL_ 1409 NetVarInt16Out5_A540_05 SubIndex_A540 5-5;
SG_MUL_VAL_ 1409 NetVarInt16Out4_A540_04 SubIndex_A540 4-4;
SG_MUL_VAL_ 1409 NetVarInt16Out3_A540_03 SubIndex_A540 3-3;
SG_MUL_VAL_ 1409 NetVarInt16Out2_A540_02 SubIndex_A540 2-2;
SG_MUL_VAL_ 1409 velocity_demand_ladder_A540_01 SubIndex_A540 1-1;
SG_MUL_VAL_ 1409 NrOfObjects_A540_00 SubIndex_A540 0-0;
SG_MUL_VAL_ 1409 SubIndex_A540 Index 42304-42304;
SG_MUL_VAL_ 1409 PTO_gear_Feedback_A4C0_0A SubIndex_A4C0 10-10;
SG_MUL_VAL_ 1409 PTO_Switch_A4C0_09 SubIndex_A4C0 9-9;
SG_MUL_VAL_ 1409 NetVarUInt8Out8_A4C0_08 SubIndex_A4C0 8-8;
SG_MUL_VAL_ 1409 NetVarUInt8Out7_A4C0_07 SubIndex_A4C0 7-7;
SG_MUL_VAL_ 1409 EngMountedPTO_A4C0_06 SubIndex_A4C0 6-6;
SG_MUL_VAL_ 1409 ParkBrakeDemandValue_A4C0_05 SubIndex_A4C0 5-5;
SG_MUL_VAL_ 1409 Support_Down_A4C0_04 SubIndex_A4C0 4-4;
SG_MUL_VAL_ 1409 Support_Up_A4C0_03 SubIndex_A4C0 3-3;
SG_MUL_VAL_ 1409 Ladder_Down_A4C0_02 SubIndex_A4C0 2-2;
SG_MUL_VAL_ 1409 Ladder_Up_A4C0_01 SubIndex_A4C0 1-1;
SG_MUL_VAL_ 1409 NrOfObjects_A4C0_00 SubIndex_A4C0 0-0;
SG_MUL_VAL_ 1409 SubIndex_A4C0 Index 42176-42176;
SG_MUL_VAL_ 1409 NetVarInt8Out10_A480_0A SubIndex_A480 10-10;
SG_MUL_VAL_ 1409 NetVarInt8Out9_A480_09 SubIndex_A480 9-9;
SG_MUL_VAL_ 1409 NetVarInt8Out8_A480_08 SubIndex_A480 8-8;
SG_MUL_VAL_ 1409 NetVarInt8Out7_A480_07 SubIndex_A480 7-7;
SG_MUL_VAL_ 1409 CurrentGearValue_A480_06 SubIndex_A480 6-6;
SG_MUL_VAL_ 1409 NetVarInt8Out5_A480_05 SubIndex_A480 5-5;
SG_MUL_VAL_ 1409 NetVarInt8Out4_A480_04 SubIndex_A480 4-4;
SG_MUL_VAL_ 1409 NetVarInt8Out3_A480_03 SubIndex_A480 3-3;
SG_MUL_VAL_ 1409 NetVarInt8Out2_A480_02 SubIndex_A480 2-2;
SG_MUL_VAL_ 1409 NetVarInt8Out1_A480_01 SubIndex_A480 1-1;
SG_MUL_VAL_ 1409 NrOfObjects_A480_00 SubIndex_A480 0-0;
SG_MUL_VAL_ 1409 SubIndex_A480 Index 42112-42112;
SG_MUL_VAL_ 1409 NetVarUInt32In10_A200_0A SubIndex_A200 10-10;
SG_MUL_VAL_ 1409 NetVarUInt32In9_A200_09 SubIndex_A200 9-9;
SG_MUL_VAL_ 1409 NetVarUInt32In8_A200_08 SubIndex_A200 8-8;
SG_MUL_VAL_ 1409 NetVarUInt32In7_A200_07 SubIndex_A200 7-7;
SG_MUL_VAL_ 1409 NetVarUInt32In6_A200_06 SubIndex_A200 6-6;
SG_MUL_VAL_ 1409 NetVarUInt32In5_A200_05 SubIndex_A200 5-5;
SG_MUL_VAL_ 1409 NetVarUInt32In4_A200_04 SubIndex_A200 4-4;
SG_MUL_VAL_ 1409 NetVarUInt32In3_A200_03 SubIndex_A200 3-3;
SG_MUL_VAL_ 1409 NetVarUInt32In2_A200_02 SubIndex_A200 2-2;
SG_MUL_VAL_ 1409 NetVarUInt32In1_A200_01 SubIndex_A200 1-1;
SG_MUL_VAL_ 1409 NrOfObjects_A200_00 SubIndex_A200 0-0;
SG_MUL_VAL_ 1409 SubIndex_A200 Index 41472-41472;
SG_MUL_VAL_ 1409 NetVarInt32In10_A1C0_0A SubIndex_A1C0 10-10;
SG_MUL_VAL_ 1409 NetVarInt32In9_A1C0_09 SubIndex_A1C0 9-9;
SG_MUL_VAL_ 1409 NetVarInt32In8_A1C0_08 SubIndex_A1C0 8-8;
SG_MUL_VAL_ 1409 NetVarInt32In7_A1C0_07 SubIndex_A1C0 7-7;
SG_MUL_VAL_ 1409 NetVarInt32In6_A1C0_06 SubIndex_A1C0 6-6;
SG_MUL_VAL_ 1409 NetVarInt32In5_A1C0_05 SubIndex_A1C0 5-5;
SG_MUL_VAL_ 1409 NetVarInt32In4_A1C0_04 SubIndex_A1C0 4-4;
SG_MUL_VAL_ 1409 NetVarInt32In3_A1C0_03 SubIndex_A1C0 3-3;
SG_MUL_VAL_ 1409 NetVarInt32In2_A1C0_02 SubIndex_A1C0 2-2;
SG_MUL_VAL_ 1409 NetVarInt32In1_A1C0_01 SubIndex_A1C0 1-1;
SG_MUL_VAL_ 1409 NrOfObjects_A1C0_00 SubIndex_A1C0 0-0;
SG_MUL_VAL_ 1409 SubIndex_A1C0 Index 41408-41408;
SG_MUL_VAL_ 1409 NetVarUInt16In10_A100_0A SubIndex_A100 10-10;
SG_MUL_VAL_ 1409 NetVarUInt16In9_A100_09 SubIndex_A100 9-9;
SG_MUL_VAL_ 1409 NetVarUInt16In8_A100_08 SubIndex_A100 8-8;
SG_MUL_VAL_ 1409 NetVarUInt16In7_A100_07 SubIndex_A100 7-7;
SG_MUL_VAL_ 1409 NetVarUInt16In6_A100_06 SubIndex_A100 6-6;
SG_MUL_VAL_ 1409 NetVarUInt16In5_A100_05 SubIndex_A100 5-5;
SG_MUL_VAL_ 1409 NetVarUInt16In4_A100_04 SubIndex_A100 4-4;
SG_MUL_VAL_ 1409 controlword_sup_rear_A100_03 SubIndex_A100 3-3;
SG_MUL_VAL_ 1409 controlword_sup_front_A100_02 SubIndex_A100 2-2;
SG_MUL_VAL_ 1409 controlword_ladder_A100_01 SubIndex_A100 1-1;
SG_MUL_VAL_ 1409 NrOfObjects_A100_00 SubIndex_A100 0-0;
SG_MUL_VAL_ 1409 SubIndex_A100 Index 41216-41216;
SG_MUL_VAL_ 1409 NetVarInt16In10_A0C0_0A SubIndex_A0C0 10-10;
SG_MUL_VAL_ 1409 NetVarInt16In9_A0C0_09 SubIndex_A0C0 9-9;
SG_MUL_VAL_ 1409 NetVarInt16In8_A0C0_08 SubIndex_A0C0 8-8;
SG_MUL_VAL_ 1409 NetVarInt16In7_A0C0_07 SubIndex_A0C0 7-7;
SG_MUL_VAL_ 1409 NetVarInt16In6_A0C0_06 SubIndex_A0C0 6-6;
SG_MUL_VAL_ 1409 NetVarInt16In5_A0C0_05 SubIndex_A0C0 5-5;
SG_MUL_VAL_ 1409 requested_engine_speed_A0C0_04 SubIndex_A0C0 4-4;
SG_MUL_VAL_ 1409 vl_target_velocity_sup_rear_A0C0 SubIndex_A0C0 3-3;
SG_MUL_VAL_ 1409 vl_target_velocity_sup_front_A0C SubIndex_A0C0 2-2;
SG_MUL_VAL_ 1409 vl_target_velocity_ladder_A0C0_0 SubIndex_A0C0 1-1;
SG_MUL_VAL_ 1409 NrOfObjects_A0C0_00 SubIndex_A0C0 0-0;
SG_MUL_VAL_ 1409 SubIndex_A0C0 Index 41152-41152;
SG_MUL_VAL_ 1409 NetVarUInt8In9A_A040_0A SubIndex_A040 10-10;
SG_MUL_VAL_ 1409 MasterPTO_Feedback_A040_09 SubIndex_A040 9-9;
SG_MUL_VAL_ 1409 NetVarUInt8In8_A040_08 SubIndex_A040 8-8;
SG_MUL_VAL_ 1409 NetVarUInt8In7_A040_07 SubIndex_A040 7-7;
SG_MUL_VAL_ 1409 NetVarUInt8In6_A040_06 SubIndex_A040 6-6;
SG_MUL_VAL_ 1409 NetVarUInt8In5_A040_05 SubIndex_A040 5-5;
SG_MUL_VAL_ 1409 PTO_Switch_State_A040_04 SubIndex_A040 4-4;
SG_MUL_VAL_ 1409 Supportposvalue_A040_03 SubIndex_A040 3-3;
SG_MUL_VAL_ 1409 SupportLock_A040_02 SubIndex_A040 2-2;
SG_MUL_VAL_ 1409 LadderLock_A040_01 SubIndex_A040 1-1;
SG_MUL_VAL_ 1409 NrOfObjects_A040_00 SubIndex_A040 0-0;
SG_MUL_VAL_ 1409 SubIndex_A040 Index 41024-41024;
SG_MUL_VAL_ 1409 NetVarInt8In10_A000_0A SubIndex_A000 10-10;
SG_MUL_VAL_ 1409 NetVarInt8In9_A000_09 SubIndex_A000 9-9;
SG_MUL_VAL_ 1409 NetVarInt8In8_A000_08 SubIndex_A000 8-8;
SG_MUL_VAL_ 1409 NetVarInt8In7_A000_07 SubIndex_A000 7-7;
SG_MUL_VAL_ 1409 NetVarInt8In6_A000_06 SubIndex_A000 6-6;
SG_MUL_VAL_ 1409 NetVarInt8In5_A000_05 SubIndex_A000 5-5;
SG_MUL_VAL_ 1409 NetVarInt8In4_A000_04 SubIndex_A000 4-4;
SG_MUL_VAL_ 1409 NetVarInt8In3_A000_03 SubIndex_A000 3-3;
SG_MUL_VAL_ 1409 NetVarInt8In2_A000_02 SubIndex_A000 2-2;
SG_MUL_VAL_ 1409 CurrentGearValueM_A000_01 SubIndex_A000 1-1;
SG_MUL_VAL_ 1409 NrOfObjects_A000_00 SubIndex_A000 0-0;
SG_MUL_VAL_ 1409 SubIndex_A000 Index 40960-40960;
SG_MUL_VAL_ 1409 SerialNumber_7f_1F88_7F SubIndex_1F88 127-127;
SG_MUL_VAL_ 1409 SerialNumber_7e_1F88_7E SubIndex_1F88 126-126;
SG_MUL_VAL_ 1409 SerialNumber_7d_1F88_7D SubIndex_1F88 125-125;
SG_MUL_VAL_ 1409 SerialNumber_7c_1F88_7C SubIndex_1F88 124-124;
SG_MUL_VAL_ 1409 SerialNumber_7b_1F88_7B SubIndex_1F88 123-123;
SG_MUL_VAL_ 1409 SerialNumber_7a_1F88_7A SubIndex_1F88 122-122;
SG_MUL_VAL_ 1409 SerialNumber_79_1F88_79 SubIndex_1F88 121-121;
SG_MUL_VAL_ 1409 SerialNumber_78_1F88_78 SubIndex_1F88 120-120;
SG_MUL_VAL_ 1409 SerialNumber_77_1F88_77 SubIndex_1F88 119-119;
SG_MUL_VAL_ 1409 SerialNumber_76_1F88_76 SubIndex_1F88 118-118;
SG_MUL_VAL_ 1409 SerialNumber_75_1F88_75 SubIndex_1F88 117-117;
SG_MUL_VAL_ 1409 SerialNumber_74_1F88_74 SubIndex_1F88 116-116;
SG_MUL_VAL_ 1409 SerialNumber_73_1F88_73 SubIndex_1F88 115-115;
SG_MUL_VAL_ 1409 SerialNumber_72_1F88_72 SubIndex_1F88 114-114;
SG_MUL_VAL_ 1409 SerialNumber_71_1F88_71 SubIndex_1F88 113-113;
SG_MUL_VAL_ 1409 SerialNumber_70_1F88_70 SubIndex_1F88 112-112;
SG_MUL_VAL_ 1409 SerialNumber_6f_1F88_6F SubIndex_1F88 111-111;
SG_MUL_VAL_ 1409 SerialNumber_6e_1F88_6E SubIndex_1F88 110-110;
SG_MUL_VAL_ 1409 SerialNumber_6d_1F88_6D SubIndex_1F88 109-109;
SG_MUL_VAL_ 1409 SerialNumber_6c_1F88_6C SubIndex_1F88 108-108;
SG_MUL_VAL_ 1409 SerialNumber_6b_1F88_6B SubIndex_1F88 107-107;
SG_MUL_VAL_ 1409 SerialNumber_6a_1F88_6A SubIndex_1F88 106-106;
SG_MUL_VAL_ 1409 SerialNumber_69_1F88_69 SubIndex_1F88 105-105;
SG_MUL_VAL_ 1409 SerialNumber_68_1F88_68 SubIndex_1F88 104-104;
SG_MUL_VAL_ 1409 SerialNumber_67_1F88_67 SubIndex_1F88 103-103;
SG_MUL_VAL_ 1409 SerialNumber_66_1F88_66 SubIndex_1F88 102-102;
SG_MUL_VAL_ 1409 SerialNumber_65_1F88_65 SubIndex_1F88 101-101;
SG_MUL_VAL_ 1409 SerialNumber_64_1F88_64 SubIndex_1F88 100-100;
SG_MUL_VAL_ 1409 SerialNumber_63_1F88_63 SubIndex_1F88 99-99;
SG_MUL_VAL_ 1409 SerialNumber_62_1F88_62 SubIndex_1F88 98-98;
SG_MUL_VAL_ 1409 SerialNumber_61_1F88_61 SubIndex_1F88 97-97;
SG_MUL_VAL_ 1409 SerialNumber_60_1F88_60 SubIndex_1F88 96-96;
SG_MUL_VAL_ 1409 SerialNumber_5f_1F88_5F SubIndex_1F88 95-95;
SG_MUL_VAL_ 1409 SerialNumber_5e_1F88_5E SubIndex_1F88 94-94;
SG_MUL_VAL_ 1409 SerialNumber_5d_1F88_5D SubIndex_1F88 93-93;
SG_MUL_VAL_ 1409 SerialNumber_5c_1F88_5C SubIndex_1F88 92-92;
SG_MUL_VAL_ 1409 SerialNumber_5b_1F88_5B SubIndex_1F88 91-91;
SG_MUL_VAL_ 1409 SerialNumber_5a_1F88_5A SubIndex_1F88 90-90;
SG_MUL_VAL_ 1409 SerialNumber_59_1F88_59 SubIndex_1F88 89-89;
SG_MUL_VAL_ 1409 SerialNumber_58_1F88_58 SubIndex_1F88 88-88;
SG_MUL_VAL_ 1409 SerialNumber_57_1F88_57 SubIndex_1F88 87-87;
SG_MUL_VAL_ 1409 SerialNumber_56_1F88_56 SubIndex_1F88 86-86;
SG_MUL_VAL_ 1409 SerialNumber_55_1F88_55 SubIndex_1F88 85-85;
SG_MUL_VAL_ 1409 SerialNumber_54_1F88_54 SubIndex_1F88 84-84;
SG_MUL_VAL_ 1409 SerialNumber_53_1F88_53 SubIndex_1F88 83-83;
SG_MUL_VAL_ 1409 SerialNumber_52_1F88_52 SubIndex_1F88 82-82;
SG_MUL_VAL_ 1409 SerialNumber_51_1F88_51 SubIndex_1F88 81-81;
SG_MUL_VAL_ 1409 SerialNumber_50_1F88_50 SubIndex_1F88 80-80;
SG_MUL_VAL_ 1409 SerialNumber_4f_1F88_4F SubIndex_1F88 79-79;
SG_MUL_VAL_ 1409 SerialNumber_4e_1F88_4E SubIndex_1F88 78-78;
SG_MUL_VAL_ 1409 SerialNumber_4d_1F88_4D SubIndex_1F88 77-77;
SG_MUL_VAL_ 1409 SerialNumber_4c_1F88_4C SubIndex_1F88 76-76;
SG_MUL_VAL_ 1409 SerialNumber_4b_1F88_4B SubIndex_1F88 75-75;
SG_MUL_VAL_ 1409 SerialNumber_4a_1F88_4A SubIndex_1F88 74-74;
SG_MUL_VAL_ 1409 SerialNumber_49_1F88_49 SubIndex_1F88 73-73;
SG_MUL_VAL_ 1409 SerialNumber_48_1F88_48 SubIndex_1F88 72-72;
SG_MUL_VAL_ 1409 SerialNumber_47_1F88_47 SubIndex_1F88 71-71;
SG_MUL_VAL_ 1409 SerialNumber_46_1F88_46 SubIndex_1F88 70-70;
SG_MUL_VAL_ 1409 SerialNumber_45_1F88_45 SubIndex_1F88 69-69;
SG_MUL_VAL_ 1409 SerialNumber_44_1F88_44 SubIndex_1F88 68-68;
SG_MUL_VAL_ 1409 SerialNumber_43_1F88_43 SubIndex_1F88 67-67;
SG_MUL_VAL_ 1409 SerialNumber_42_1F88_42 SubIndex_1F88 66-66;
SG_MUL_VAL_ 1409 SerialNumber_41_1F88_41 SubIndex_1F88 65-65;
SG_MUL_VAL_ 1409 SerialNumber_40_1F88_40 SubIndex_1F88 64-64;
SG_MUL_VAL_ 1409 SerialNumber_3f_1F88_3F SubIndex_1F88 63-63;
SG_MUL_VAL_ 1409 SerialNumber_3e_1F88_3E SubIndex_1F88 62-62;
SG_MUL_VAL_ 1409 SerialNumber_3d_1F88_3D SubIndex_1F88 61-61;
SG_MUL_VAL_ 1409 SerialNumber_3c_1F88_3C SubIndex_1F88 60-60;
SG_MUL_VAL_ 1409 SerialNumber_3b_1F88_3B SubIndex_1F88 59-59;
SG_MUL_VAL_ 1409 SerialNumber_3a_1F88_3A SubIndex_1F88 58-58;
SG_MUL_VAL_ 1409 SerialNumber_39_1F88_39 SubIndex_1F88 57-57;
SG_MUL_VAL_ 1409 SerialNumber_38_1F88_38 SubIndex_1F88 56-56;
SG_MUL_VAL_ 1409 SerialNumber_37_1F88_37 SubIndex_1F88 55-55;
SG_MUL_VAL_ 1409 SerialNumber_36_1F88_36 SubIndex_1F88 54-54;
SG_MUL_VAL_ 1409 SerialNumber_35_1F88_35 SubIndex_1F88 53-53;
SG_MUL_VAL_ 1409 SerialNumber_34_1F88_34 SubIndex_1F88 52-52;
SG_MUL_VAL_ 1409 SerialNumber_33_1F88_33 SubIndex_1F88 51-51;
SG_MUL_VAL_ 1409 SerialNumber_32_1F88_32 SubIndex_1F88 50-50;
SG_MUL_VAL_ 1409 SerialNumber_31_1F88_31 SubIndex_1F88 49-49;
SG_MUL_VAL_ 1409 SerialNumber_30_1F88_30 SubIndex_1F88 48-48;
SG_MUL_VAL_ 1409 SerialNumber_2f_1F88_2F SubIndex_1F88 47-47;
SG_MUL_VAL_ 1409 SerialNumber_2e_1F88_2E SubIndex_1F88 46-46;
SG_MUL_VAL_ 1409 SerialNumber_2d_1F88_2D SubIndex_1F88 45-45;
SG_MUL_VAL_ 1409 SerialNumber_2c_1F88_2C SubIndex_1F88 44-44;
SG_MUL_VAL_ 1409 SerialNumber_2b_1F88_2B SubIndex_1F88 43-43;
SG_MUL_VAL_ 1409 SerialNumber_2a_1F88_2A SubIndex_1F88 42-42;
SG_MUL_VAL_ 1409 SerialNumber_29_1F88_29 SubIndex_1F88 41-41;
SG_MUL_VAL_ 1409 SerialNumber_28_1F88_28 SubIndex_1F88 40-40;
SG_MUL_VAL_ 1409 SerialNumber_27_1F88_27 SubIndex_1F88 39-39;
SG_MUL_VAL_ 1409 SerialNumber_26_1F88_26 SubIndex_1F88 38-38;
SG_MUL_VAL_ 1409 SerialNumber_25_1F88_25 SubIndex_1F88 37-37;
SG_MUL_VAL_ 1409 SerialNumber_24_1F88_24 SubIndex_1F88 36-36;
SG_MUL_VAL_ 1409 SerialNumber_23_1F88_23 SubIndex_1F88 35-35;
SG_MUL_VAL_ 1409 SerialNumber_22_1F88_22 SubIndex_1F88 34-34;
SG_MUL_VAL_ 1409 SerialNumber_21_1F88_21 SubIndex_1F88 33-33;
SG_MUL_VAL_ 1409 SerialNumber_20_1F88_20 SubIndex_1F88 32-32;
SG_MUL_VAL_ 1409 SerialNumber_1f_1F88_1F SubIndex_1F88 31-31;
SG_MUL_VAL_ 1409 SerialNumber_1e_1F88_1E SubIndex_1F88 30-30;
SG_MUL_VAL_ 1409 SerialNumber_1d_1F88_1D SubIndex_1F88 29-29;
SG_MUL_VAL_ 1409 SerialNumber_1c_1F88_1C SubIndex_1F88 28-28;
SG_MUL_VAL_ 1409 SerialNumber_1b_1F88_1B SubIndex_1F88 27-27;
SG_MUL_VAL_ 1409 SerialNumber_1a_1F88_1A SubIndex_1F88 26-26;
SG_MUL_VAL_ 1409 SerialNumber_19_1F88_19 SubIndex_1F88 25-25;
SG_MUL_VAL_ 1409 SerialNumber_18_1F88_18 SubIndex_1F88 24-24;
SG_MUL_VAL_ 1409 SerialNumber_17_1F88_17 SubIndex_1F88 23-23;
SG_MUL_VAL_ 1409 SerialNumber_16_1F88_16 SubIndex_1F88 22-22;
SG_MUL_VAL_ 1409 SerialNumber_15_1F88_15 SubIndex_1F88 21-21;
SG_MUL_VAL_ 1409 SerialNumber_14_1F88_14 SubIndex_1F88 20-20;
SG_MUL_VAL_ 1409 SerialNumber_13_1F88_13 SubIndex_1F88 19-19;
SG_MUL_VAL_ 1409 SerialNumber_12_1F88_12 SubIndex_1F88 18-18;
SG_MUL_VAL_ 1409 SerialNumber_11_1F88_11 SubIndex_1F88 17-17;
SG_MUL_VAL_ 1409 SerialNumber_10_1F88_10 SubIndex_1F88 16-16;
SG_MUL_VAL_ 1409 SerialNumber_f_1F88_0F SubIndex_1F88 15-15;
SG_MUL_VAL_ 1409 SerialNumber_e_1F88_0E SubIndex_1F88 14-14;
SG_MUL_VAL_ 1409 SerialNumber_d_1F88_0D SubIndex_1F88 13-13;
SG_MUL_VAL_ 1409 SerialNumber_c_1F88_0C SubIndex_1F88 12-12;
SG_MUL_VAL_ 1409 SerialNumber_b_1F88_0B SubIndex_1F88 11-11;
SG_MUL_VAL_ 1409 SerialNumber_a_1F88_0A SubIndex_1F88 10-10;
SG_MUL_VAL_ 1409 SerialNumber_9_1F88_09 SubIndex_1F88 9-9;
SG_MUL_VAL_ 1409 SerialNumber_8_1F88_08 SubIndex_1F88 8-8;
SG_MUL_VAL_ 1409 SerialNumber_7_1F88_07 SubIndex_1F88 7-7;
SG_MUL_VAL_ 1409 SerialNumber_6_1F88_06 SubIndex_1F88 6-6;
SG_MUL_VAL_ 1409 SerialNumber_5_1F88_05 SubIndex_1F88 5-5;
SG_MUL_VAL_ 1409 SerialNumber_4_1F88_04 SubIndex_1F88 4-4;
SG_MUL_VAL_ 1409 SerialNumber_3_1F88_03 SubIndex_1F88 3-3;
SG_MUL_VAL_ 1409 SerialNumber_2_1F88_02 SubIndex_1F88 2-2;
SG_MUL_VAL_ 1409 SerialNumber_1F88_01 SubIndex_1F88 1-1;
SG_MUL_VAL_ 1409 NrOfObjects_1F88_00 SubIndex_1F88 0-0;
SG_MUL_VAL_ 1409 SubIndex_1F88 Index 8072-8072;
SG_MUL_VAL_ 1409 VendorIdentification_7f_1F85_7F SubIndex_1F85 127-127;
SG_MUL_VAL_ 1409 VendorIdentification_7e_1F85_7E SubIndex_1F85 126-126;
SG_MUL_VAL_ 1409 VendorIdentification_7d_1F85_7D SubIndex_1F85 125-125;
SG_MUL_VAL_ 1409 VendorIdentification_7c_1F85_7C SubIndex_1F85 124-124;
SG_MUL_VAL_ 1409 VendorIdentification_7b_1F85_7B SubIndex_1F85 123-123;
SG_MUL_VAL_ 1409 VendorIdentification_7a_1F85_7A SubIndex_1F85 122-122;
SG_MUL_VAL_ 1409 VendorIdentification_79_1F85_79 SubIndex_1F85 121-121;
SG_MUL_VAL_ 1409 VendorIdentification_78_1F85_78 SubIndex_1F85 120-120;
SG_MUL_VAL_ 1409 VendorIdentification_77_1F85_77 SubIndex_1F85 119-119;
SG_MUL_VAL_ 1409 VendorIdentification_76_1F85_76 SubIndex_1F85 118-118;
SG_MUL_VAL_ 1409 VendorIdentification_75_1F85_75 SubIndex_1F85 117-117;
SG_MUL_VAL_ 1409 VendorIdentification_74_1F85_74 SubIndex_1F85 116-116;
SG_MUL_VAL_ 1409 VendorIdentification_73_1F85_73 SubIndex_1F85 115-115;
SG_MUL_VAL_ 1409 VendorIdentification_72_1F85_72 SubIndex_1F85 114-114;
SG_MUL_VAL_ 1409 VendorIdentification_71_1F85_71 SubIndex_1F85 113-113;
SG_MUL_VAL_ 1409 VendorIdentification_70_1F85_70 SubIndex_1F85 112-112;
SG_MUL_VAL_ 1409 VendorIdentification_6f_1F85_6F SubIndex_1F85 111-111;
SG_MUL_VAL_ 1409 VendorIdentification_6e_1F85_6E SubIndex_1F85 110-110;
SG_MUL_VAL_ 1409 VendorIdentification_6d_1F85_6D SubIndex_1F85 109-109;
SG_MUL_VAL_ 1409 VendorIdentification_6c_1F85_6C SubIndex_1F85 108-108;
SG_MUL_VAL_ 1409 VendorIdentification_6b_1F85_6B SubIndex_1F85 107-107;
SG_MUL_VAL_ 1409 VendorIdentification_6a_1F85_6A SubIndex_1F85 106-106;
SG_MUL_VAL_ 1409 VendorIdentification_69_1F85_69 SubIndex_1F85 105-105;
SG_MUL_VAL_ 1409 VendorIdentification_68_1F85_68 SubIndex_1F85 104-104;
SG_MUL_VAL_ 1409 VendorIdentification_67_1F85_67 SubIndex_1F85 103-103;
SG_MUL_VAL_ 1409 VendorIdentification_66_1F85_66 SubIndex_1F85 102-102;
SG_MUL_VAL_ 1409 VendorIdentification_65_1F85_65 SubIndex_1F85 101-101;
SG_MUL_VAL_ 1409 VendorIdentification_64_1F85_64 SubIndex_1F85 100-100;
SG_MUL_VAL_ 1409 VendorIdentification_63_1F85_63 SubIndex_1F85 99-99;
SG_MUL_VAL_ 1409 VendorIdentification_62_1F85_62 SubIndex_1F85 98-98;
SG_MUL_VAL_ 1409 VendorIdentification_61_1F85_61 SubIndex_1F85 97-97;
SG_MUL_VAL_ 1409 VendorIdentification_60_1F85_60 SubIndex_1F85 96-96;
SG_MUL_VAL_ 1409 VendorIdentification_5f_1F85_5F SubIndex_1F85 95-95;
SG_MUL_VAL_ 1409 VendorIdentification_5e_1F85_5E SubIndex_1F85 94-94;
SG_MUL_VAL_ 1409 VendorIdentification_5d_1F85_5D SubIndex_1F85 93-93;
SG_MUL_VAL_ 1409 VendorIdentification_5c_1F85_5C SubIndex_1F85 92-92;
SG_MUL_VAL_ 1409 VendorIdentification_5b_1F85_5B SubIndex_1F85 91-91;
SG_MUL_VAL_ 1409 VendorIdentification_5a_1F85_5A SubIndex_1F85 90-90;
SG_MUL_VAL_ 1409 VendorIdentification_59_1F85_59 SubIndex_1F85 89-89;
SG_MUL_VAL_ 1409 VendorIdentification_58_1F85_58 SubIndex_1F85 88-88;
SG_MUL_VAL_ 1409 VendorIdentification_57_1F85_57 SubIndex_1F85 87-87;
SG_MUL_VAL_ 1409 VendorIdentification_56_1F85_56 SubIndex_1F85 86-86;
SG_MUL_VAL_ 1409 VendorIdentification_55_1F85_55 SubIndex_1F85 85-85;
SG_MUL_VAL_ 1409 VendorIdentification_54_1F85_54 SubIndex_1F85 84-84;
SG_MUL_VAL_ 1409 VendorIdentification_53_1F85_53 SubIndex_1F85 83-83;
SG_MUL_VAL_ 1409 VendorIdentification_52_1F85_52 SubIndex_1F85 82-82;
SG_MUL_VAL_ 1409 VendorIdentification_51_1F85_51 SubIndex_1F85 81-81;
SG_MUL_VAL_ 1409 VendorIdentification_50_1F85_50 SubIndex_1F85 80-80;
SG_MUL_VAL_ 1409 VendorIdentification_4f_1F85_4F SubIndex_1F85 79-79;
SG_MUL_VAL_ 1409 VendorIdentification_4e_1F85_4E SubIndex_1F85 78-78;
SG_MUL_VAL_ 1409 VendorIdentification_4d_1F85_4D SubIndex_1F85 77-77;
SG_MUL_VAL_ 1409 VendorIdentification_4c_1F85_4C SubIndex_1F85 76-76;
SG_MUL_VAL_ 1409 VendorIdentification_4b_1F85_4B SubIndex_1F85 75-75;
SG_MUL_VAL_ 1409 VendorIdentification_4a_1F85_4A SubIndex_1F85 74-74;
SG_MUL_VAL_ 1409 VendorIdentification_49_1F85_49 SubIndex_1F85 73-73;
SG_MUL_VAL_ 1409 VendorIdentification_48_1F85_48 SubIndex_1F85 72-72;
SG_MUL_VAL_ 1409 VendorIdentification_47_1F85_47 SubIndex_1F85 71-71;
SG_MUL_VAL_ 1409 VendorIdentification_46_1F85_46 SubIndex_1F85 70-70;
SG_MUL_VAL_ 1409 VendorIdentification_45_1F85_45 SubIndex_1F85 69-69;
SG_MUL_VAL_ 1409 VendorIdentification_44_1F85_44 SubIndex_1F85 68-68;
SG_MUL_VAL_ 1409 VendorIdentification_43_1F85_43 SubIndex_1F85 67-67;
SG_MUL_VAL_ 1409 VendorIdentification_42_1F85_42 SubIndex_1F85 66-66;
SG_MUL_VAL_ 1409 VendorIdentification_41_1F85_41 SubIndex_1F85 65-65;
SG_MUL_VAL_ 1409 VendorIdentification_40_1F85_40 SubIndex_1F85 64-64;
SG_MUL_VAL_ 1409 VendorIdentification_3f_1F85_3F SubIndex_1F85 63-63;
SG_MUL_VAL_ 1409 VendorIdentification_3e_1F85_3E SubIndex_1F85 62-62;
SG_MUL_VAL_ 1409 VendorIdentification_3d_1F85_3D SubIndex_1F85 61-61;
SG_MUL_VAL_ 1409 VendorIdentification_3c_1F85_3C SubIndex_1F85 60-60;
SG_MUL_VAL_ 1409 VendorIdentification_3b_1F85_3B SubIndex_1F85 59-59;
SG_MUL_VAL_ 1409 VendorIdentification_3a_1F85_3A SubIndex_1F85 58-58;
SG_MUL_VAL_ 1409 VendorIdentification_39_1F85_39 SubIndex_1F85 57-57;
SG_MUL_VAL_ 1409 VendorIdentification_38_1F85_38 SubIndex_1F85 56-56;
SG_MUL_VAL_ 1409 VendorIdentification_37_1F85_37 SubIndex_1F85 55-55;
SG_MUL_VAL_ 1409 VendorIdentification_36_1F85_36 SubIndex_1F85 54-54;
SG_MUL_VAL_ 1409 VendorIdentification_35_1F85_35 SubIndex_1F85 53-53;
SG_MUL_VAL_ 1409 VendorIdentification_34_1F85_34 SubIndex_1F85 52-52;
SG_MUL_VAL_ 1409 VendorIdentification_33_1F85_33 SubIndex_1F85 51-51;
SG_MUL_VAL_ 1409 VendorIdentification_32_1F85_32 SubIndex_1F85 50-50;
SG_MUL_VAL_ 1409 VendorIdentification_31_1F85_31 SubIndex_1F85 49-49;
SG_MUL_VAL_ 1409 VendorIdentification_30_1F85_30 SubIndex_1F85 48-48;
SG_MUL_VAL_ 1409 VendorIdentification_2f_1F85_2F SubIndex_1F85 47-47;
SG_MUL_VAL_ 1409 VendorIdentification_2e_1F85_2E SubIndex_1F85 46-46;
SG_MUL_VAL_ 1409 VendorIdentification_2d_1F85_2D SubIndex_1F85 45-45;
SG_MUL_VAL_ 1409 VendorIdentification_2c_1F85_2C SubIndex_1F85 44-44;
SG_MUL_VAL_ 1409 VendorIdentification_2b_1F85_2B SubIndex_1F85 43-43;
SG_MUL_VAL_ 1409 VendorIdentification_2a_1F85_2A SubIndex_1F85 42-42;
SG_MUL_VAL_ 1409 VendorIdentification_29_1F85_29 SubIndex_1F85 41-41;
SG_MUL_VAL_ 1409 VendorIdentification_28_1F85_28 SubIndex_1F85 40-40;
SG_MUL_VAL_ 1409 VendorIdentification_27_1F85_27 SubIndex_1F85 39-39;
SG_MUL_VAL_ 1409 VendorIdentification_26_1F85_26 SubIndex_1F85 38-38;
SG_MUL_VAL_ 1409 VendorIdentification_25_1F85_25 SubIndex_1F85 37-37;
SG_MUL_VAL_ 1409 VendorIdentification_24_1F85_24 SubIndex_1F85 36-36;
SG_MUL_VAL_ 1409 VendorIdentification_23_1F85_23 SubIndex_1F85 35-35;
SG_MUL_VAL_ 1409 VendorIdentification_22_1F85_22 SubIndex_1F85 34-34;
SG_MUL_VAL_ 1409 VendorIdentification_21_1F85_21 SubIndex_1F85 33-33;
SG_MUL_VAL_ 1409 VendorIdentification_20_1F85_20 SubIndex_1F85 32-32;
SG_MUL_VAL_ 1409 VendorIdentification_1f_1F85_1F SubIndex_1F85 31-31;
SG_MUL_VAL_ 1409 VendorIdentification_1e_1F85_1E SubIndex_1F85 30-30;
SG_MUL_VAL_ 1409 VendorIdentification_1d_1F85_1D SubIndex_1F85 29-29;
SG_MUL_VAL_ 1409 VendorIdentification_1c_1F85_1C SubIndex_1F85 28-28;
SG_MUL_VAL_ 1409 VendorIdentification_1b_1F85_1B SubIndex_1F85 27-27;
SG_MUL_VAL_ 1409 VendorIdentification_1a_1F85_1A SubIndex_1F85 26-26;
SG_MUL_VAL_ 1409 VendorIdentification_19_1F85_19 SubIndex_1F85 25-25;
SG_MUL_VAL_ 1409 VendorIdentification_18_1F85_18 SubIndex_1F85 24-24;
SG_MUL_VAL_ 1409 VendorIdentification_17_1F85_17 SubIndex_1F85 23-23;
SG_MUL_VAL_ 1409 VendorIdentification_16_1F85_16 SubIndex_1F85 22-22;
SG_MUL_VAL_ 1409 VendorIdentification_15_1F85_15 SubIndex_1F85 21-21;
SG_MUL_VAL_ 1409 VendorIdentification_14_1F85_14 SubIndex_1F85 20-20;
SG_MUL_VAL_ 1409 VendorIdentification_13_1F85_13 SubIndex_1F85 19-19;
SG_MUL_VAL_ 1409 VendorIdentification_12_1F85_12 SubIndex_1F85 18-18;
SG_MUL_VAL_ 1409 VendorIdentification_11_1F85_11 SubIndex_1F85 17-17;
SG_MUL_VAL_ 1409 VendorIdentification_10_1F85_10 SubIndex_1F85 16-16;
SG_MUL_VAL_ 1409 VendorIdentification_f_1F85_0F SubIndex_1F85 15-15;
SG_MUL_VAL_ 1409 VendorIdentification_e_1F85_0E SubIndex_1F85 14-14;
SG_MUL_VAL_ 1409 VendorIdentification_d_1F85_0D SubIndex_1F85 13-13;
SG_MUL_VAL_ 1409 VendorIdentification_c_1F85_0C SubIndex_1F85 12-12;
SG_MUL_VAL_ 1409 VendorIdentification_b_1F85_0B SubIndex_1F85 11-11;
SG_MUL_VAL_ 1409 VendorIdentification_a_1F85_0A SubIndex_1F85 10-10;
SG_MUL_VAL_ 1409 VendorIdentification_9_1F85_09 SubIndex_1F85 9-9;
SG_MUL_VAL_ 1409 VendorIdentification_8_1F85_08 SubIndex_1F85 8-8;
SG_MUL_VAL_ 1409 VendorIdentification_7_1F85_07 SubIndex_1F85 7-7;
SG_MUL_VAL_ 1409 VendorIdentification_6_1F85_06 SubIndex_1F85 6-6;
SG_MUL_VAL_ 1409 VendorIdentification_5_1F85_05 SubIndex_1F85 5-5;
SG_MUL_VAL_ 1409 VendorIdentification_4_1F85_04 SubIndex_1F85 4-4;
SG_MUL_VAL_ 1409 VendorIdentification_3_1F85_03 SubIndex_1F85 3-3;
SG_MUL_VAL_ 1409 VendorIdentification_2_1F85_02 SubIndex_1F85 2-2;
SG_MUL_VAL_ 1409 VendorIdentification_1F85_01 SubIndex_1F85 1-1;
SG_MUL_VAL_ 1409 NrOfObjects_1F85_00 SubIndex_1F85 0-0;
SG_MUL_VAL_ 1409 SubIndex_1F85 Index 8069-8069;
SG_MUL_VAL_ 1409 RequestGuard_All_1F83_80 SubIndex_1F83 128-128;
SG_MUL_VAL_ 1409 RequestGuard_1F83_7F SubIndex_1F83 127-127;
SG_MUL_VAL_ 1409 RequestGuard_1F83_7E SubIndex_1F83 126-126;
SG_MUL_VAL_ 1409 RequestGuard_1F83_7D SubIndex_1F83 125-125;
SG_MUL_VAL_ 1409 RequestGuard_1F83_7C SubIndex_1F83 124-124;
SG_MUL_VAL_ 1409 RequestGuard_1F83_7B SubIndex_1F83 123-123;
SG_MUL_VAL_ 1409 RequestGuard_1F83_7A SubIndex_1F83 122-122;
SG_MUL_VAL_ 1409 RequestGuard_1F83_79 SubIndex_1F83 121-121;
SG_MUL_VAL_ 1409 RequestGuard_1F83_78 SubIndex_1F83 120-120;
SG_MUL_VAL_ 1409 RequestGuard_1F83_77 SubIndex_1F83 119-119;
SG_MUL_VAL_ 1409 RequestGuard_1F83_76 SubIndex_1F83 118-118;
SG_MUL_VAL_ 1409 RequestGuard_1F83_75 SubIndex_1F83 117-117;
SG_MUL_VAL_ 1409 RequestGuard_1F83_74 SubIndex_1F83 116-116;
SG_MUL_VAL_ 1409 RequestGuard_1F83_73 SubIndex_1F83 115-115;
SG_MUL_VAL_ 1409 RequestGuard_1F83_72 SubIndex_1F83 114-114;
SG_MUL_VAL_ 1409 RequestGuard_1F83_71 SubIndex_1F83 113-113;
SG_MUL_VAL_ 1409 RequestGuard_1F83_70 SubIndex_1F83 112-112;
SG_MUL_VAL_ 1409 RequestGuard_1F83_6F SubIndex_1F83 111-111;
SG_MUL_VAL_ 1409 RequestGuard_1F83_6E SubIndex_1F83 110-110;
SG_MUL_VAL_ 1409 RequestGuard_1F83_6D SubIndex_1F83 109-109;
SG_MUL_VAL_ 1409 RequestGuard_1F83_6C SubIndex_1F83 108-108;
SG_MUL_VAL_ 1409 RequestGuard_1F83_6B SubIndex_1F83 107-107;
SG_MUL_VAL_ 1409 RequestGuard_1F83_6A SubIndex_1F83 106-106;
SG_MUL_VAL_ 1409 RequestGuard_1F83_69 SubIndex_1F83 105-105;
SG_MUL_VAL_ 1409 RequestGuard_1F83_68 SubIndex_1F83 104-104;
SG_MUL_VAL_ 1409 RequestGuard_1F83_67 SubIndex_1F83 103-103;
SG_MUL_VAL_ 1409 RequestGuard_1F83_66 SubIndex_1F83 102-102;
SG_MUL_VAL_ 1409 RequestGuard_1F83_65 SubIndex_1F83 101-101;
SG_MUL_VAL_ 1409 RequestGuard_1F83_64 SubIndex_1F83 100-100;
SG_MUL_VAL_ 1409 RequestGuard_1F83_63 SubIndex_1F83 99-99;
SG_MUL_VAL_ 1409 RequestGuard_1F83_62 SubIndex_1F83 98-98;
SG_MUL_VAL_ 1409 RequestGuard_1F83_61 SubIndex_1F83 97-97;
SG_MUL_VAL_ 1409 RequestGuard_1F83_60 SubIndex_1F83 96-96;
SG_MUL_VAL_ 1409 RequestGuard_1F83_5F SubIndex_1F83 95-95;
SG_MUL_VAL_ 1409 RequestGuard_1F83_5E SubIndex_1F83 94-94;
SG_MUL_VAL_ 1409 RequestGuard_1F83_5D SubIndex_1F83 93-93;
SG_MUL_VAL_ 1409 RequestGuard_1F83_5C SubIndex_1F83 92-92;
SG_MUL_VAL_ 1409 RequestGuard_1F83_5B SubIndex_1F83 91-91;
SG_MUL_VAL_ 1409 RequestGuard_1F83_5A SubIndex_1F83 90-90;
SG_MUL_VAL_ 1409 RequestGuard_1F83_59 SubIndex_1F83 89-89;
SG_MUL_VAL_ 1409 RequestGuard_1F83_58 SubIndex_1F83 88-88;
SG_MUL_VAL_ 1409 RequestGuard_1F83_57 SubIndex_1F83 87-87;
SG_MUL_VAL_ 1409 RequestGuard_1F83_56 SubIndex_1F83 86-86;
SG_MUL_VAL_ 1409 RequestGuard_1F83_55 SubIndex_1F83 85-85;
SG_MUL_VAL_ 1409 RequestGuard_1F83_54 SubIndex_1F83 84-84;
SG_MUL_VAL_ 1409 RequestGuard_1F83_53 SubIndex_1F83 83-83;
SG_MUL_VAL_ 1409 RequestGuard_1F83_52 SubIndex_1F83 82-82;
SG_MUL_VAL_ 1409 RequestGuard_1F83_51 SubIndex_1F83 81-81;
SG_MUL_VAL_ 1409 RequestGuard_1F83_50 SubIndex_1F83 80-80;
SG_MUL_VAL_ 1409 RequestGuard_1F83_4F SubIndex_1F83 79-79;
SG_MUL_VAL_ 1409 RequestGuard_1F83_4E SubIndex_1F83 78-78;
SG_MUL_VAL_ 1409 RequestGuard_1F83_4D SubIndex_1F83 77-77;
SG_MUL_VAL_ 1409 RequestGuard_1F83_4C SubIndex_1F83 76-76;
SG_MUL_VAL_ 1409 RequestGuard_1F83_4B SubIndex_1F83 75-75;
SG_MUL_VAL_ 1409 RequestGuard_1F83_4A SubIndex_1F83 74-74;
SG_MUL_VAL_ 1409 RequestGuard_1F83_49 SubIndex_1F83 73-73;
SG_MUL_VAL_ 1409 RequestGuard_1F83_48 SubIndex_1F83 72-72;
SG_MUL_VAL_ 1409 RequestGuard_1F83_47 SubIndex_1F83 71-71;
SG_MUL_VAL_ 1409 RequestGuard_1F83_46 SubIndex_1F83 70-70;
SG_MUL_VAL_ 1409 RequestGuard_1F83_45 SubIndex_1F83 69-69;
SG_MUL_VAL_ 1409 RequestGuard_1F83_44 SubIndex_1F83 68-68;
SG_MUL_VAL_ 1409 RequestGuard_1F83_43 SubIndex_1F83 67-67;
SG_MUL_VAL_ 1409 RequestGuard_1F83_42 SubIndex_1F83 66-66;
SG_MUL_VAL_ 1409 RequestGuard_1F83_41 SubIndex_1F83 65-65;
SG_MUL_VAL_ 1409 RequestGuard_1F83_40 SubIndex_1F83 64-64;
SG_MUL_VAL_ 1409 RequestGuard_1F83_3F SubIndex_1F83 63-63;
SG_MUL_VAL_ 1409 RequestGuard_1F83_3E SubIndex_1F83 62-62;
SG_MUL_VAL_ 1409 RequestGuard_1F83_3D SubIndex_1F83 61-61;
SG_MUL_VAL_ 1409 RequestGuard_1F83_3C SubIndex_1F83 60-60;
SG_MUL_VAL_ 1409 RequestGuard_1F83_3B SubIndex_1F83 59-59;
SG_MUL_VAL_ 1409 RequestGuard_1F83_3A SubIndex_1F83 58-58;
SG_MUL_VAL_ 1409 RequestGuard_1F83_39 SubIndex_1F83 57-57;
SG_MUL_VAL_ 1409 RequestGuard_1F83_38 SubIndex_1F83 56-56;
SG_MUL_VAL_ 1409 RequestGuard_1F83_37 SubIndex_1F83 55-55;
SG_MUL_VAL_ 1409 RequestGuard_1F83_36 SubIndex_1F83 54-54;
SG_MUL_VAL_ 1409 RequestGuard_1F83_35 SubIndex_1F83 53-53;
SG_MUL_VAL_ 1409 RequestGuard_1F83_34 SubIndex_1F83 52-52;
SG_MUL_VAL_ 1409 RequestGuard_1F83_33 SubIndex_1F83 51-51;
SG_MUL_VAL_ 1409 RequestGuard_1F83_32 SubIndex_1F83 50-50;
SG_MUL_VAL_ 1409 RequestGuard_1F83_31 SubIndex_1F83 49-49;
SG_MUL_VAL_ 1409 RequestGuard_1F83_30 SubIndex_1F83 48-48;
SG_MUL_VAL_ 1409 RequestGuard_1F83_2F SubIndex_1F83 47-47;
SG_MUL_VAL_ 1409 RequestGuard_1F83_2E SubIndex_1F83 46-46;
SG_MUL_VAL_ 1409 RequestGuard_1F83_2D SubIndex_1F83 45-45;
SG_MUL_VAL_ 1409 RequestGuard_1F83_2C SubIndex_1F83 44-44;
SG_MUL_VAL_ 1409 RequestGuard_1F83_2B SubIndex_1F83 43-43;
SG_MUL_VAL_ 1409 RequestGuard_1F83_2A SubIndex_1F83 42-42;
SG_MUL_VAL_ 1409 RequestGuard_1F83_29 SubIndex_1F83 41-41;
SG_MUL_VAL_ 1409 RequestGuard_1F83_28 SubIndex_1F83 40-40;
SG_MUL_VAL_ 1409 RequestGuard_1F83_27 SubIndex_1F83 39-39;
SG_MUL_VAL_ 1409 RequestGuard_1F83_26 SubIndex_1F83 38-38;
SG_MUL_VAL_ 1409 RequestGuard_1F83_25 SubIndex_1F83 37-37;
SG_MUL_VAL_ 1409 RequestGuard_1F83_24 SubIndex_1F83 36-36;
SG_MUL_VAL_ 1409 RequestGuard_1F83_23 SubIndex_1F83 35-35;
SG_MUL_VAL_ 1409 RequestGuard_1F83_22 SubIndex_1F83 34-34;
SG_MUL_VAL_ 1409 RequestGuard_1F83_21 SubIndex_1F83 33-33;
SG_MUL_VAL_ 1409 RequestGuard_1F83_20 SubIndex_1F83 32-32;
SG_MUL_VAL_ 1409 RequestGuard_1F83_1F SubIndex_1F83 31-31;
SG_MUL_VAL_ 1409 RequestGuard_1F83_1E SubIndex_1F83 30-30;
SG_MUL_VAL_ 1409 RequestGuard_1F83_1D SubIndex_1F83 29-29;
SG_MUL_VAL_ 1409 RequestGuard_1F83_1C SubIndex_1F83 28-28;
SG_MUL_VAL_ 1409 RequestGuard_1F83_1B SubIndex_1F83 27-27;
SG_MUL_VAL_ 1409 RequestGuard_1F83_1A SubIndex_1F83 26-26;
SG_MUL_VAL_ 1409 RequestGuard_1F83_19 SubIndex_1F83 25-25;
SG_MUL_VAL_ 1409 RequestGuard_1F83_18 SubIndex_1F83 24-24;
SG_MUL_VAL_ 1409 RequestGuard_1F83_17 SubIndex_1F83 23-23;
SG_MUL_VAL_ 1409 RequestGuard_1F83_16 SubIndex_1F83 22-22;
SG_MUL_VAL_ 1409 RequestGuard_1F83_15 SubIndex_1F83 21-21;
SG_MUL_VAL_ 1409 RequestGuard_1F83_14 SubIndex_1F83 20-20;
SG_MUL_VAL_ 1409 RequestGuard_1F83_13 SubIndex_1F83 19-19;
SG_MUL_VAL_ 1409 RequestGuard_1F83_12 SubIndex_1F83 18-18;
SG_MUL_VAL_ 1409 RequestGuard_1F83_11 SubIndex_1F83 17-17;
SG_MUL_VAL_ 1409 RequestGuard_1F83_10 SubIndex_1F83 16-16;
SG_MUL_VAL_ 1409 RequestGuard_1F83_0F SubIndex_1F83 15-15;
SG_MUL_VAL_ 1409 RequestGuard_1F83_0E SubIndex_1F83 14-14;
SG_MUL_VAL_ 1409 RequestGuard_1F83_0D SubIndex_1F83 13-13;
SG_MUL_VAL_ 1409 RequestGuard_1F83_0C SubIndex_1F83 12-12;
SG_MUL_VAL_ 1409 RequestGuard_1F83_0B SubIndex_1F83 11-11;
SG_MUL_VAL_ 1409 RequestGuard_1F83_0A SubIndex_1F83 10-10;
SG_MUL_VAL_ 1409 RequestGuard_1F83_09 SubIndex_1F83 9-9;
SG_MUL_VAL_ 1409 RequestGuard_1F83_08 SubIndex_1F83 8-8;
SG_MUL_VAL_ 1409 RequestGuard_1F83_07 SubIndex_1F83 7-7;
SG_MUL_VAL_ 1409 RequestGuard_1F83_06 SubIndex_1F83 6-6;
SG_MUL_VAL_ 1409 RequestGuard_1F83_05 SubIndex_1F83 5-5;
SG_MUL_VAL_ 1409 RequestGuard_1F83_04 SubIndex_1F83 4-4;
SG_MUL_VAL_ 1409 RequestGuard_1F83_03 SubIndex_1F83 3-3;
SG_MUL_VAL_ 1409 RequestGuard_1F83_02 SubIndex_1F83 2-2;
SG_MUL_VAL_ 1409 RequestGuard_1F83_01 SubIndex_1F83 1-1;
SG_MUL_VAL_ 1409 Highest_sub_index_supported_1F83 SubIndex_1F83 0-0;
SG_MUL_VAL_ 1409 SubIndex_1F83 Index 8067-8067;
SG_MUL_VAL_ 1409 RequestNMT_All_1F82_80 SubIndex_1F82 128-128;
SG_MUL_VAL_ 1409 RequestNMT_1F82_7F SubIndex_1F82 127-127;
SG_MUL_VAL_ 1409 RequestNMT_1F82_7E SubIndex_1F82 126-126;
SG_MUL_VAL_ 1409 RequestNMT_1F82_7D SubIndex_1F82 125-125;
SG_MUL_VAL_ 1409 RequestNMT_1F82_7C SubIndex_1F82 124-124;
SG_MUL_VAL_ 1409 RequestNMT_1F82_7B SubIndex_1F82 123-123;
SG_MUL_VAL_ 1409 RequestNMT_1F82_7A SubIndex_1F82 122-122;
SG_MUL_VAL_ 1409 RequestNMT_1F82_79 SubIndex_1F82 121-121;
SG_MUL_VAL_ 1409 RequestNMT_1F82_78 SubIndex_1F82 120-120;
SG_MUL_VAL_ 1409 RequestNMT_1F82_77 SubIndex_1F82 119-119;
SG_MUL_VAL_ 1409 RequestNMT_1F82_76 SubIndex_1F82 118-118;
SG_MUL_VAL_ 1409 RequestNMT_1F82_75 SubIndex_1F82 117-117;
SG_MUL_VAL_ 1409 RequestNMT_1F82_74 SubIndex_1F82 116-116;
SG_MUL_VAL_ 1409 RequestNMT_1F82_73 SubIndex_1F82 115-115;
SG_MUL_VAL_ 1409 RequestNMT_1F82_72 SubIndex_1F82 114-114;
SG_MUL_VAL_ 1409 RequestNMT_1F82_71 SubIndex_1F82 113-113;
SG_MUL_VAL_ 1409 RequestNMT_1F82_70 SubIndex_1F82 112-112;
SG_MUL_VAL_ 1409 RequestNMT_1F82_6F SubIndex_1F82 111-111;
SG_MUL_VAL_ 1409 RequestNMT_1F82_6E SubIndex_1F82 110-110;
SG_MUL_VAL_ 1409 RequestNMT_1F82_6D SubIndex_1F82 109-109;
SG_MUL_VAL_ 1409 RequestNMT_1F82_6C SubIndex_1F82 108-108;
SG_MUL_VAL_ 1409 RequestNMT_1F82_6B SubIndex_1F82 107-107;
SG_MUL_VAL_ 1409 RequestNMT_1F82_6A SubIndex_1F82 106-106;
SG_MUL_VAL_ 1409 RequestNMT_1F82_69 SubIndex_1F82 105-105;
SG_MUL_VAL_ 1409 RequestNMT_1F82_68 SubIndex_1F82 104-104;
SG_MUL_VAL_ 1409 RequestNMT_1F82_67 SubIndex_1F82 103-103;
SG_MUL_VAL_ 1409 RequestNMT_1F82_66 SubIndex_1F82 102-102;
SG_MUL_VAL_ 1409 RequestNMT_1F82_65 SubIndex_1F82 101-101;
SG_MUL_VAL_ 1409 RequestNMT_1F82_64 SubIndex_1F82 100-100;
SG_MUL_VAL_ 1409 RequestNMT_1F82_63 SubIndex_1F82 99-99;
SG_MUL_VAL_ 1409 RequestNMT_1F82_62 SubIndex_1F82 98-98;
SG_MUL_VAL_ 1409 RequestNMT_1F82_61 SubIndex_1F82 97-97;
SG_MUL_VAL_ 1409 RequestNMT_1F82_60 SubIndex_1F82 96-96;
SG_MUL_VAL_ 1409 RequestNMT_1F82_5F SubIndex_1F82 95-95;
SG_MUL_VAL_ 1409 RequestNMT_1F82_5E SubIndex_1F82 94-94;
SG_MUL_VAL_ 1409 RequestNMT_1F82_5D SubIndex_1F82 93-93;
SG_MUL_VAL_ 1409 RequestNMT_1F82_5C SubIndex_1F82 92-92;
SG_MUL_VAL_ 1409 RequestNMT_1F82_5B SubIndex_1F82 91-91;
SG_MUL_VAL_ 1409 RequestNMT_1F82_5A SubIndex_1F82 90-90;
SG_MUL_VAL_ 1409 RequestNMT_1F82_59 SubIndex_1F82 89-89;
SG_MUL_VAL_ 1409 RequestNMT_1F82_58 SubIndex_1F82 88-88;
SG_MUL_VAL_ 1409 RequestNMT_1F82_57 SubIndex_1F82 87-87;
SG_MUL_VAL_ 1409 RequestNMT_1F82_56 SubIndex_1F82 86-86;
SG_MUL_VAL_ 1409 RequestNMT_1F82_55 SubIndex_1F82 85-85;
SG_MUL_VAL_ 1409 RequestNMT_1F82_54 SubIndex_1F82 84-84;
SG_MUL_VAL_ 1409 RequestNMT_1F82_53 SubIndex_1F82 83-83;
SG_MUL_VAL_ 1409 RequestNMT_1F82_52 SubIndex_1F82 82-82;
SG_MUL_VAL_ 1409 RequestNMT_1F82_51 SubIndex_1F82 81-81;
SG_MUL_VAL_ 1409 RequestNMT_1F82_50 SubIndex_1F82 80-80;
SG_MUL_VAL_ 1409 RequestNMT_1F82_4F SubIndex_1F82 79-79;
SG_MUL_VAL_ 1409 RequestNMT_1F82_4E SubIndex_1F82 78-78;
SG_MUL_VAL_ 1409 RequestNMT_1F82_4D SubIndex_1F82 77-77;
SG_MUL_VAL_ 1409 RequestNMT_1F82_4C SubIndex_1F82 76-76;
SG_MUL_VAL_ 1409 RequestNMT_1F82_4B SubIndex_1F82 75-75;
SG_MUL_VAL_ 1409 RequestNMT_1F82_4A SubIndex_1F82 74-74;
SG_MUL_VAL_ 1409 RequestNMT_1F82_49 SubIndex_1F82 73-73;
SG_MUL_VAL_ 1409 RequestNMT_1F82_48 SubIndex_1F82 72-72;
SG_MUL_VAL_ 1409 RequestNMT_1F82_47 SubIndex_1F82 71-71;
SG_MUL_VAL_ 1409 RequestNMT_1F82_46 SubIndex_1F82 70-70;
SG_MUL_VAL_ 1409 RequestNMT_1F82_45 SubIndex_1F82 69-69;
SG_MUL_VAL_ 1409 RequestNMT_1F82_44 SubIndex_1F82 68-68;
SG_MUL_VAL_ 1409 RequestNMT_1F82_43 SubIndex_1F82 67-67;
SG_MUL_VAL_ 1409 RequestNMT_1F82_42 SubIndex_1F82 66-66;
SG_MUL_VAL_ 1409 RequestNMT_1F82_41 SubIndex_1F82 65-65;
SG_MUL_VAL_ 1409 RequestNMT_1F82_40 SubIndex_1F82 64-64;
SG_MUL_VAL_ 1409 RequestNMT_1F82_3F SubIndex_1F82 63-63;
SG_MUL_VAL_ 1409 RequestNMT_1F82_3E SubIndex_1F82 62-62;
SG_MUL_VAL_ 1409 RequestNMT_1F82_3D SubIndex_1F82 61-61;
SG_MUL_VAL_ 1409 RequestNMT_1F82_3C SubIndex_1F82 60-60;
SG_MUL_VAL_ 1409 RequestNMT_1F82_3B SubIndex_1F82 59-59;
SG_MUL_VAL_ 1409 RequestNMT_1F82_3A SubIndex_1F82 58-58;
SG_MUL_VAL_ 1409 RequestNMT_1F82_39 SubIndex_1F82 57-57;
SG_MUL_VAL_ 1409 RequestNMT_1F82_38 SubIndex_1F82 56-56;
SG_MUL_VAL_ 1409 RequestNMT_1F82_37 SubIndex_1F82 55-55;
SG_MUL_VAL_ 1409 RequestNMT_1F82_36 SubIndex_1F82 54-54;
SG_MUL_VAL_ 1409 RequestNMT_1F82_35 SubIndex_1F82 53-53;
SG_MUL_VAL_ 1409 RequestNMT_1F82_34 SubIndex_1F82 52-52;
SG_MUL_VAL_ 1409 RequestNMT_1F82_33 SubIndex_1F82 51-51;
SG_MUL_VAL_ 1409 RequestNMT_1F82_32 SubIndex_1F82 50-50;
SG_MUL_VAL_ 1409 RequestNMT_1F82_31 SubIndex_1F82 49-49;
SG_MUL_VAL_ 1409 RequestNMT_1F82_30 SubIndex_1F82 48-48;
SG_MUL_VAL_ 1409 RequestNMT_1F82_2F SubIndex_1F82 47-47;
SG_MUL_VAL_ 1409 RequestNMT_1F82_2E SubIndex_1F82 46-46;
SG_MUL_VAL_ 1409 RequestNMT_1F82_2D SubIndex_1F82 45-45;
SG_MUL_VAL_ 1409 RequestNMT_1F82_2C SubIndex_1F82 44-44;
SG_MUL_VAL_ 1409 RequestNMT_1F82_2B SubIndex_1F82 43-43;
SG_MUL_VAL_ 1409 RequestNMT_1F82_2A SubIndex_1F82 42-42;
SG_MUL_VAL_ 1409 RequestNMT_1F82_29 SubIndex_1F82 41-41;
SG_MUL_VAL_ 1409 RequestNMT_1F82_28 SubIndex_1F82 40-40;
SG_MUL_VAL_ 1409 RequestNMT_1F82_27 SubIndex_1F82 39-39;
SG_MUL_VAL_ 1409 RequestNMT_1F82_26 SubIndex_1F82 38-38;
SG_MUL_VAL_ 1409 RequestNMT_1F82_25 SubIndex_1F82 37-37;
SG_MUL_VAL_ 1409 RequestNMT_1F82_24 SubIndex_1F82 36-36;
SG_MUL_VAL_ 1409 RequestNMT_1F82_23 SubIndex_1F82 35-35;
SG_MUL_VAL_ 1409 RequestNMT_1F82_22 SubIndex_1F82 34-34;
SG_MUL_VAL_ 1409 RequestNMT_1F82_21 SubIndex_1F82 33-33;
SG_MUL_VAL_ 1409 RequestNMT_1F82_20 SubIndex_1F82 32-32;
SG_MUL_VAL_ 1409 RequestNMT_1F82_1F SubIndex_1F82 31-31;
SG_MUL_VAL_ 1409 RequestNMT_1F82_1E SubIndex_1F82 30-30;
SG_MUL_VAL_ 1409 RequestNMT_1F82_1D SubIndex_1F82 29-29;
SG_MUL_VAL_ 1409 RequestNMT_1F82_1C SubIndex_1F82 28-28;
SG_MUL_VAL_ 1409 RequestNMT_1F82_1B SubIndex_1F82 27-27;
SG_MUL_VAL_ 1409 RequestNMT_1F82_1A SubIndex_1F82 26-26;
SG_MUL_VAL_ 1409 RequestNMT_1F82_19 SubIndex_1F82 25-25;
SG_MUL_VAL_ 1409 RequestNMT_1F82_18 SubIndex_1F82 24-24;
SG_MUL_VAL_ 1409 RequestNMT_1F82_17 SubIndex_1F82 23-23;
SG_MUL_VAL_ 1409 RequestNMT_1F82_16 SubIndex_1F82 22-22;
SG_MUL_VAL_ 1409 RequestNMT_1F82_15 SubIndex_1F82 21-21;
SG_MUL_VAL_ 1409 RequestNMT_1F82_14 SubIndex_1F82 20-20;
SG_MUL_VAL_ 1409 RequestNMT_1F82_13 SubIndex_1F82 19-19;
SG_MUL_VAL_ 1409 RequestNMT_1F82_12 SubIndex_1F82 18-18;
SG_MUL_VAL_ 1409 RequestNMT_1F82_11 SubIndex_1F82 17-17;
SG_MUL_VAL_ 1409 RequestNMT_1F82_10 SubIndex_1F82 16-16;
SG_MUL_VAL_ 1409 RequestNMT_1F82_0F SubIndex_1F82 15-15;
SG_MUL_VAL_ 1409 RequestNMT_1F82_0E SubIndex_1F82 14-14;
SG_MUL_VAL_ 1409 RequestNMT_1F82_0D SubIndex_1F82 13-13;
SG_MUL_VAL_ 1409 RequestNMT_1F82_0C SubIndex_1F82 12-12;
SG_MUL_VAL_ 1409 RequestNMT_1F82_0B SubIndex_1F82 11-11;
SG_MUL_VAL_ 1409 RequestNMT_1F82_0A SubIndex_1F82 10-10;
SG_MUL_VAL_ 1409 RequestNMT_1F82_09 SubIndex_1F82 9-9;
SG_MUL_VAL_ 1409 RequestNMT_1F82_08 SubIndex_1F82 8-8;
SG_MUL_VAL_ 1409 RequestNMT_1F82_07 SubIndex_1F82 7-7;
SG_MUL_VAL_ 1409 RequestNMT_1F82_06 SubIndex_1F82 6-6;
SG_MUL_VAL_ 1409 RequestNMT_1F82_05 SubIndex_1F82 5-5;
SG_MUL_VAL_ 1409 RequestNMT_1F82_04 SubIndex_1F82 4-4;
SG_MUL_VAL_ 1409 RequestNMT_1F82_03 SubIndex_1F82 3-3;
SG_MUL_VAL_ 1409 RequestNMT_1F82_02 SubIndex_1F82 2-2;
SG_MUL_VAL_ 1409 RequestNMT_1F82_01 SubIndex_1F82 1-1;
SG_MUL_VAL_ 1409 Highest_sub_index_supported_1F82 SubIndex_1F82 0-0;
SG_MUL_VAL_ 1409 SubIndex_1F82 Index 8066-8066;
SG_MUL_VAL_ 1409 SlaveAssignment_1F81_7F SubIndex_1F81 127-127;
SG_MUL_VAL_ 1409 SlaveAssignment_1F81_7E SubIndex_1F81 126-126;
SG_MUL_VAL_ 1409 SlaveAssignment_1F81_7D SubIndex_1F81 125-125;
SG_MUL_VAL_ 1409 SlaveAssignment_1F81_7C SubIndex_1F81 124-124;
SG_MUL_VAL_ 1409 SlaveAssignment_1F81_7B SubIndex_1F81 123-123;
SG_MUL_VAL_ 1409 SlaveAssignment_1F81_7A SubIndex_1F81 122-122;
SG_MUL_VAL_ 1409 SlaveAssignment_1F81_79 SubIndex_1F81 121-121;
SG_MUL_VAL_ 1409 SlaveAssignment_1F81_78 SubIndex_1F81 120-120;
